VERSION ""

NS_ :

BS_:

BU_: ESM HIB HIP HIS SaGE CBC DASM DIAGNOST EBCM ECM EPS ESC ESL ETM HALF HCP IC OCM ORC PTS RF_HUB SCCM SGW

BO_ 1033 NM_SBWM: 8 ESM
 SG_ Awake_Diag_Actv m15 : 33|1@1+ (1,0) [0|0] ""  CBC,EBCM,EPS,ESC,ESL,HCP,IC,RF_HUB,SCCM,SGW
 SG_ Awake_EEPROM m15 : 35|1@1+ (1,0) [0|0] ""  CBC,EBCM,EPS,ESC,ESL,HCP,IC,RF_HUB,SCCM,SGW
 SG_ Awake_Ignition_On m15 : 34|1@1+ (1,0) [0|0] ""  CBC,EBCM,EPS,ESC,ESL,HCP,IC,RF_HUB,SCCM,SGW
 SG_ Awake_NwSt m15 : 32|1@1+ (1,0) [0|0] ""  CBC,EBCM,EPS,ESC,ESL,HCP,IC,RF_HUB,SCCM,SGW
 SG_ Awake_URS m15 : 36|1@1+ (1,0) [0|0] ""  CBC,EBCM,EPS,ESC,ESL,HCP,IC,RF_HUB,SCCM,SGW
 SG_ NM_Mode : 0|8@1+ (1,0) [0|0] ""  CBC,EBCM,EPS,ESC,ESL,HCP,IC,RF_HUB,SCCM,SGW
 SG_ NM_Sleep_Ack : 22|1@1+ (1,0) [0|0] ""  CBC,EBCM,EPS,ESC,ESL,HCP,IC,RF_HUB,SCCM,SGW
 SG_ NM_Sleep_Ind : 23|1@1+ (1,0) [0|0] ""  CBC,EBCM,EPS,ESC,ESL,HCP,IC,RF_HUB,SCCM,SGW
 SG_ NM_Successor : 8|8@1+ (1,0) [0|63] ""  CBC,EBCM,EPS,ESC,ESL,HCP,IC,RF_HUB,SCCM,SGW
 SG_ NM_Ud_Launch : 16|6@1+ (1,0) [0|0] ""  CBC,EBCM,EPS,ESC,ESL,HCP,IC,RF_HUB,SCCM,SGW
 SG_ NM_Ud_Srv M : 24|8@1+ (1,0) [0|0] ""  CBC,EBCM,EPS,ESC,ESL,HCP,IC,RF_HUB,SCCM,SGW
 SG_ Nw_Id : 56|8@1+ (1,0) [0|0] ""  CBC,EBCM,EPS,ESC,ESL,HCP,IC,RF_HUB,SCCM,SGW
 SG_ WakeupCnt m2 : 40|8@1+ (1,0) [0|254] ""  CBC,EBCM,EPS,ESC,ESL,HCP,IC,RF_HUB,SCCM,SGW
 SG_ WakeupRsn_SBWM m2 : 32|8@1+ (1,0) [0|0] ""  CBC,EBCM,EPS,ESC,ESL,HCP,IC,RF_HUB,SCCM,SGW

BO_ 1059 NM_SCCM: 8 SCCM
 SG_ Awake_Diag_Actv m15 : 33|1@1+ (1,0) [0|0] ""  CBC,EBCM,EPS,ESC,ESL,HCP,IC,RF_HUB,SCCM,SGW
 SG_ Awake_EEPROM m15 : 36|1@1+ (1,0) [0|0] ""  CBC,EBCM,EPS,ESC,ESL,HCP,IC,RF_HUB,SCCM,SGW
 SG_ Awake_FTP_Psd m15 : 38|1@1+ (1,0) [0|0] ""  CBC,EBCM,EPS,ESC,ESL,HCP,IC,RF_HUB,SCCM,SGW
 SG_ Awake_HrnSwt_Actv m15 : 39|1@1+ (1,0) [0|0] ""  CBC,EBCM,EPS,ESC,ESL,HCP,IC,RF_HUB,SCCM,SGW
 SG_ Awake_Ignition_On m15 : 35|1@1+ (1,0) [0|0] ""  CBC,EBCM,EPS,ESC,ESL,HCP,IC,RF_HUB,SCCM,SGW
 SG_ Awake_NwSt m15 : 32|1@1+ (1,0) [0|0] ""  CBC,EBCM,EPS,ESC,ESL,HCP,IC,RF_HUB,SCCM,SGW
 SG_ Awake_StwSw_Actv m15 : 34|1@1+ (1,0) [0|0] ""  CBC,EBCM,EPS,ESC,ESL,HCP,IC,RF_HUB,SCCM,SGW
 SG_ Awake_tilt_tel_Psd m15 : 37|1@1+ (1,0) [0|0] ""  CBC,EBCM,EPS,ESC,ESL,HCP,IC,RF_HUB,SCCM,SGW
 SG_ NM_Mode : 0|8@1+ (1,0) [0|0] ""  CBC,EBCM,EPS,ESC,ESL,HCP,IC,RF_HUB,SCCM,SGW
 SG_ NM_Sleep_Ack : 22|1@1+ (1,0) [0|0] ""  CBC,EBCM,EPS,ESC,ESL,HCP,IC,RF_HUB,SCCM,SGW
 SG_ NM_Sleep_Ind : 23|1@1+ (1,0) [0|0] ""  CBC,EBCM,EPS,ESC,ESL,HCP,IC,RF_HUB,SCCM,SGW
 SG_ NM_Successor : 8|8@1+ (1,0) [0|63] ""  CBC,EBCM,EPS,ESC,ESL,HCP,IC,RF_HUB,SCCM,SGW
 SG_ NM_Ud_Launch : 16|6@1+ (1,0) [0|0] ""  CBC,EBCM,EPS,ESC,ESL,HCP,IC,RF_HUB,SCCM,SGW
 SG_ NM_Ud_Srv M : 24|8@1+ (1,0) [0|0] ""  CBC,EBCM,EPS,ESC,ESL,HCP,IC,RF_HUB,SCCM,SGW
 SG_ Nw_Id : 56|8@1+ (1,0) [0|0] ""  CBC,EBCM,EPS,ESC,ESL,HCP,IC,RF_HUB,SCCM,SGW
 SG_ WakeupCnt m2 : 40|8@1+ (1,0) [0|254] ""  CBC,EBCM,EPS,ESC,ESL,HCP,IC,RF_HUB,SCCM,SGW
 SG_ WakeupRsn_SCCM m2 : 32|8@1+ (1,0) [0|0] ""  CBC,EBCM,EPS,ESC,ESL,HCP,IC,RF_HUB,SCCM,SGW

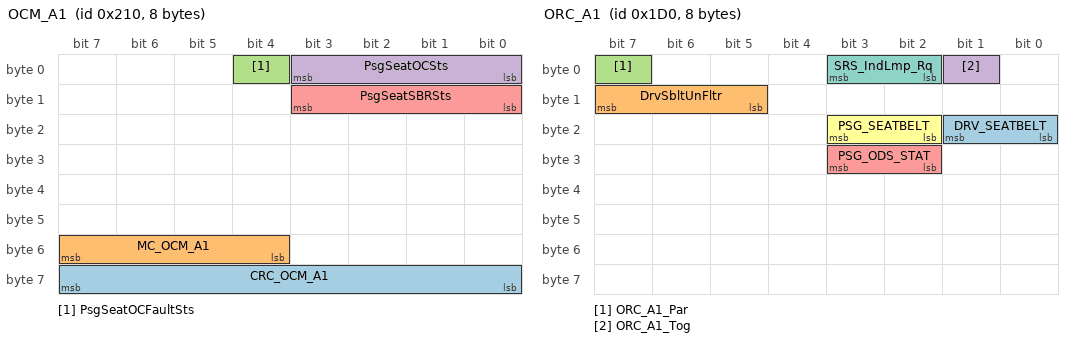
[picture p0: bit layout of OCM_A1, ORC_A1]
BO_ 528 OCM_A1: 8 OCM
 SG_ CRC_OCM_A1 : 56|8@1+ (1,0) [0|0] ""  ORC,SGW
 SG_ MC_OCM_A1 : 52|4@1+ (1,0) [0|15] ""  ORC,SGW
 SG_ PsgSeatOCFaultSts : 4|1@1+ (1,0) [0|0] ""  ORC,SGW
 SG_ PsgSeatOCSts : 0|4@1+ (1,0) [0|0] ""  ORC,SGW
 SG_ PsgSeatSBRSts : 8|4@1+ (1,0) [0|0] ""  ORC,SGW

BO_ 464 ORC_A1: 8 ORC
 SG_ DRV_SEATBELT : 16|2@1+ (1,0) [0|0] ""  HIB,DASM,ECM,ESC,ETM,HCP,IC,SGW
 SG_ DrvSbltUnFltr : 13|3@1+ (1,0) [0|0] ""  ECM,ESC,SGW
 SG_ ORC_A1_Par : 7|1@1+ (1,0) [0|0] ""  HIB,DASM,SGW
 SG_ ORC_A1_Tog : 1|1@1+ (1,0) [0|0] ""  HIB,DASM,SGW
 SG_ PSG_ODS_STAT : 26|2@1+ (1,0) [0|0] ""  IC,SGW
 SG_ PSG_SEATBELT : 18|2@1+ (1,0) [0|0] ""  ETM,IC,SGW
 SG_ SRS_IndLmp_Rq : 2|2@1+ (1,0) [0|0] ""  ETM,IC,SGW

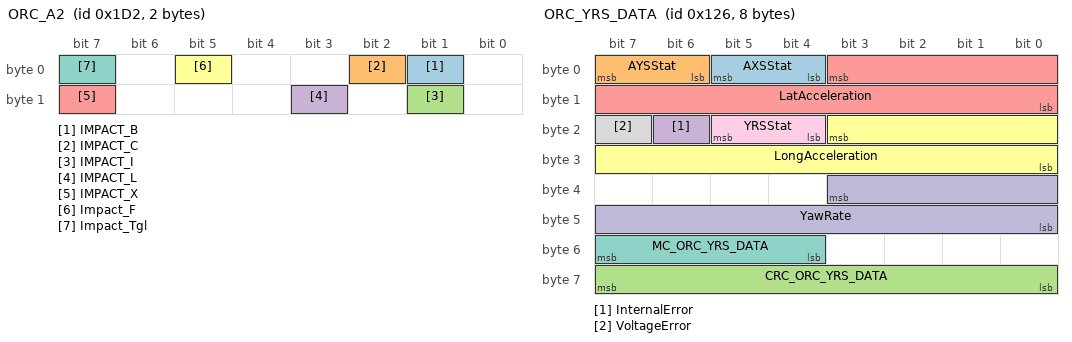
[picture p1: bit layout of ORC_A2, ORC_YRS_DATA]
BO_ 466 ORC_A2: 2 ORC
 SG_ IMPACT_B : 1|1@1+ (1,0) [0|0] ""  ETM,SGW
 SG_ IMPACT_C : 2|1@1+ (1,0) [0|0] ""  ETM,SGW
 SG_ IMPACT_I : 9|1@1+ (1,0) [0|0] ""  ETM,SGW
 SG_ IMPACT_L : 11|1@1+ (1,0) [0|0] ""  ETM,SGW
 SG_ IMPACT_X : 15|1@1+ (1,0) [0|0] ""  CBC,ECM,ETM,HCP,OCM,SGW
 SG_ Impact_F : 5|1@1+ (1,0) [0|0] ""  ETM,SGW
 SG_ Impact_Tgl : 7|1@1+ (1,0) [0|0] ""  CBC,ECM,ETM,HCP,OCM,SGW

BO_ 469 ORC_A4: 8 ORC
 SG_ ORC_Health : 23|1@1+ (1,0) [0|0] ""  HCP,SGW

BO_ 294 ORC_YRS_DATA: 8 ORC
 SG_ AXSStat : 4|2@1+ (1,0) [0|0] ""  EBCM,ESC,HCP,SGW
 SG_ AYSStat : 6|2@1+ (1,0) [0|0] ""  ESC,SGW
 SG_ CRC_ORC_YRS_DATA : 56|8@1+ (1,0) [0|0] ""  EBCM,ESC,SGW
 SG_ InternalError : 22|1@1+ (1,0) [0|0] ""  EBCM,ESC,SGW
 SG_ LatAcceleration : 3|12@0+ (0.02,-40.96) [-40.96|40.92] "m/s²"  EBCM,ESC,SGW
 SG_ LongAcceleration : 19|12@0+ (0.02,-40.96) [-40.96|40.92] "m/s²"  EBCM,ESC,HCP,SGW
 SG_ MC_ORC_YRS_DATA : 52|4@1+ (1,0) [0|15] ""  EBCM,ESC,SGW
 SG_ VoltageError : 23|1@1+ (1,0) [0|0] ""  EBCM,ESC,SGW
 SG_ YRSStat : 20|2@1+ (1,0) [0|0] ""  EBCM,ESC,SGW
 SG_ YawRate : 35|12@0+ (0.08,-163.84) [-163.84|163.68] "°/s"  EBCM,ESC,SGW

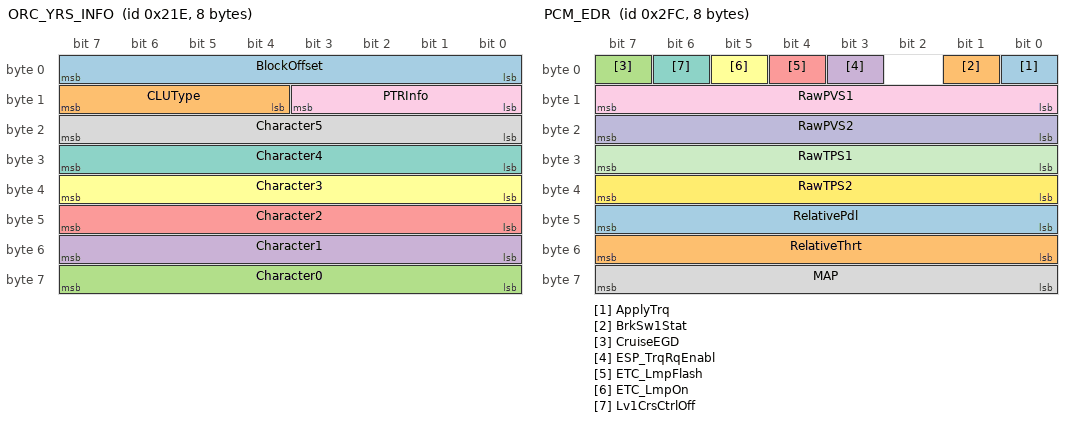
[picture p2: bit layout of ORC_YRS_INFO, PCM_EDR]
BO_ 542 ORC_YRS_INFO: 8 ORC
 SG_ BlockOffset : 0|8@1+ (1,0) [0|0] ""  ESC,SGW
 SG_ CLUType : 12|4@1+ (1,0) [0|0] ""  ESC,SGW
 SG_ Character0 : 56|8@1+ (1,0) [0|0] ""  ESC,SGW
 SG_ Character1 : 48|8@1+ (1,0) [0|0] ""  ESC,SGW
 SG_ Character2 : 40|8@1+ (1,0) [0|0] ""  ESC,SGW
 SG_ Character3 : 32|8@1+ (1,0) [0|0] ""  ESC,SGW
 SG_ Character4 : 24|8@1+ (1,0) [0|0] ""  ESC,SGW
 SG_ Character5 : 16|8@1+ (1,0) [0|0] ""  ESC,SGW
 SG_ PTRInfo : 8|4@1+ (1,0) [0|0] ""  ESC,SGW

BO_ 764 PCM_EDR: 8 ECM
 SG_ ApplyTrq : 0|1@1+ (1,0) [0|0] ""  SGW
 SG_ BrkSw1Stat : 1|1@1+ (1,0) [0|0] ""  ETM,SGW
 SG_ CruiseEGD : 7|1@1+ (1,0) [0|0] ""  SGW
 SG_ ESP_TrqRqEnabl : 3|1@1+ (1,0) [0|0] ""  ORC,SGW
 SG_ ETC_LmpFlash : 4|1@1+ (1,0) [0|0] ""  ORC,SGW
 SG_ ETC_LmpOn : 5|1@1+ (1,0) [0|0] ""  ORC,SGW
 SG_ Lv1CrsCtrlOff : 6|1@1+ (1,0) [0|0] ""  ORC,SGW
 SG_ MAP : 56|8@1+ (0.8,0) [0|203.2] "kPa"  ORC,SGW
 SG_ RawPVS1 : 8|8@1+ (0.019607843,0) [0|4.98] "Volts"  ORC,SGW
 SG_ RawPVS2 : 16|8@1+ (0.019607843,0) [0|4.98] "Volts"  ORC,SGW
 SG_ RawTPS1 : 24|8@1+ (0.019607843,0) [0|4.98] "Volts"  ORC,SGW
 SG_ RawTPS2 : 32|8@1+ (0.019607843,0) [0|4.98] "Volts"  ORC,SGW
 SG_ RelativePdl : 40|8@1+ (0.019607843,0) [0|4.98] "Volts"  SGW
 SG_ RelativeThrt : 48|8@1+ (0.019607843,0) [0|4.98] "Volts"  SGW

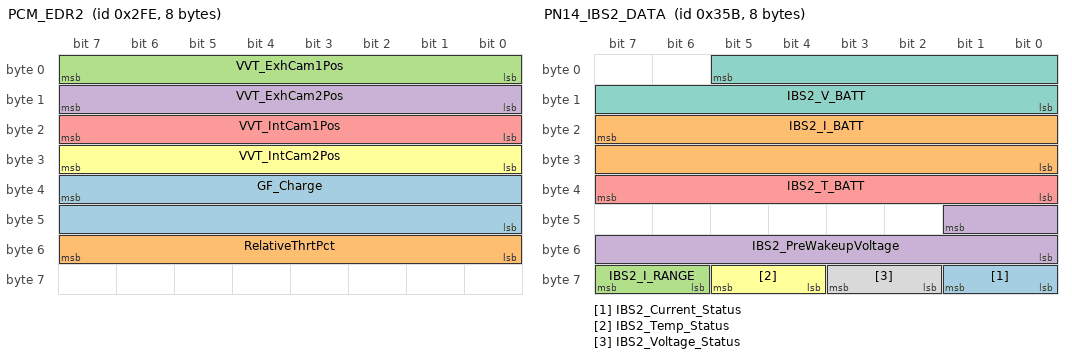
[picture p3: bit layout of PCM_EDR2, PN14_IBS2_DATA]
BO_ 766 PCM_EDR2: 8 ECM
 SG_ GF_Charge : 39|16@0+ (0.2,0) [0|13106.8] "mg/cycle/cyl"  ETM,ORC,SGW
 SG_ RelativeThrtPct : 48|8@1+ (0.4,0) [0|100] "%"  ORC,SGW
 SG_ VVT_ExhCam1Pos : 0|8@1+ (1,0) [1|255] "Degrees"  SGW
 SG_ VVT_ExhCam2Pos : 8|8@1+ (1,0) [1|255] "Degrees"  SGW
 SG_ VVT_IntCam1Pos : 16|8@1+ (1,0) [1|255] "Degrees"  SGW
 SG_ VVT_IntCam2Pos : 24|8@1+ (1,0) [1|255] "Degrees"  SGW

BO_ 859 PN14_IBS2_DATA: 8 CBC
 SG_ IBS2_Current_Status : 56|2@1+ (1,0) [0|0] ""  SGW
 SG_ IBS2_I_BATT : 23|16@0+ (1,-32768) [-32768|32766] "I_RANGE res."  SGW
 SG_ IBS2_I_RANGE : 62|2@1+ (1,0) [0|0] "Amp"  SGW
 SG_ IBS2_PreWakeupVoltage : 41|10@0+ (0.01,5) [5|15] "V"  SGW
 SG_ IBS2_T_BATT : 32|8@1+ (1,-40) [-40|105] "°C"  HCP,SGW
 SG_ IBS2_Temp_Status : 60|2@1+ (1,0) [0|0] ""  HCP,SGW
 SG_ IBS2_V_BATT : 5|14@0+ (0.0009765625,3) [3|18] "Volts"  HCP,SGW
 SG_ IBS2_Voltage_Status : 58|2@1+ (1,0) [0|0] ""  HCP,SGW

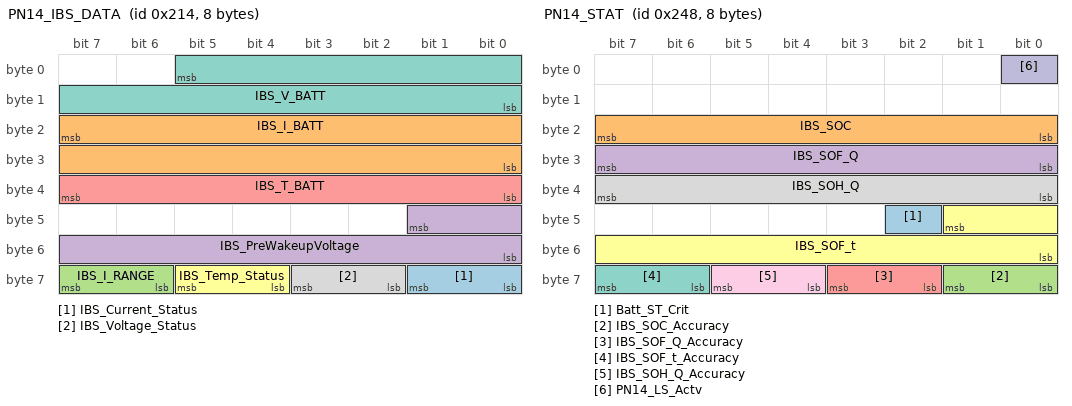
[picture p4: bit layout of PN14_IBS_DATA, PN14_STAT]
BO_ 532 PN14_IBS_DATA: 8 CBC
 SG_ IBS_Current_Status : 56|2@1+ (1,0) [0|0] ""  SGW
 SG_ IBS_I_BATT : 23|16@0+ (1,-32768) [-32768|32766] "I_RANGE res."  ETM,SGW
 SG_ IBS_I_RANGE : 62|2@1+ (1,0) [0|0] "Amp"  SGW
 SG_ IBS_PreWakeupVoltage : 41|10@0+ (0.01,5) [5|15] "V"  SGW
 SG_ IBS_T_BATT : 32|8@1+ (1,-40) [-40|105] "°C"  ETM,HCP,SGW
 SG_ IBS_Temp_Status : 60|2@1+ (1,0) [0|0] ""  HCP,SGW
 SG_ IBS_V_BATT : 5|14@0+ (0.0009765625,3) [3|18] "Volts"  ETM,HCP,ORC,SGW
 SG_ IBS_Voltage_Status : 58|2@1+ (1,0) [0|0] ""  HCP,SGW

BO_ 584 PN14_STAT: 8 CBC
 SG_ Batt_ST_Crit : 42|1@1+ (1,0) [0|0] ""  IC,SGW
 SG_ IBS_SOC : 16|8@1+ (1,0) [0|100] "%"  ETM,HCP,ORC,SGW
 SG_ IBS_SOC_Accuracy : 56|2@1+ (1,0) [0|0] ""  ETM,HCP,SGW
 SG_ IBS_SOF_Q : 24|8@1+ (0.5,0) [0|127] "Ah"  SGW
 SG_ IBS_SOF_Q_Accuracy : 58|2@1+ (1,0) [0|0] ""  SGW
 SG_ IBS_SOF_t : 41|10@0+ (1,0) [0|1022] "min"  SGW
 SG_ IBS_SOF_t_Accuracy : 62|2@1+ (1,0) [0|0] ""  SGW
 SG_ IBS_SOH_Q : 32|8@1+ (0.5,0) [0|127] "Ah"  SGW
 SG_ IBS_SOH_Q_Accuracy : 60|2@1+ (1,0) [0|0] ""  SGW
 SG_ PN14_LS_Actv : 0|1@1+ (1,0) [0|0] ""  IC,SGW

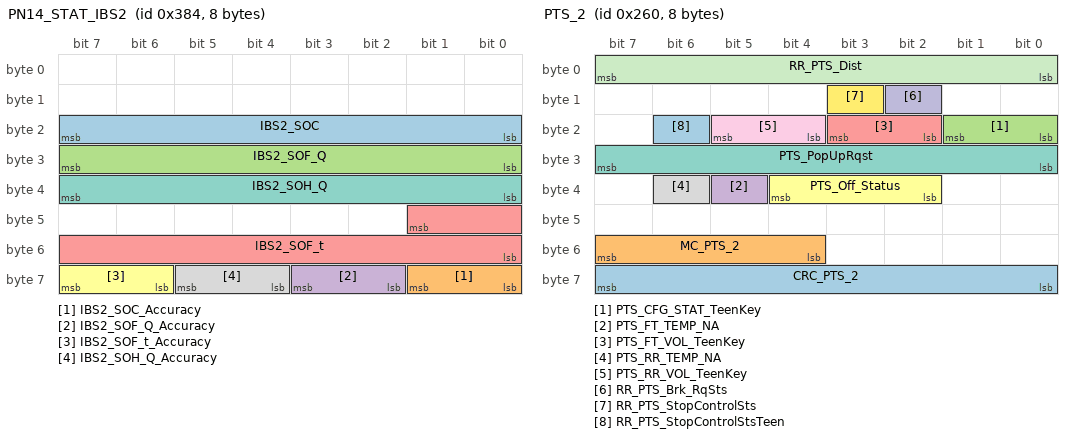
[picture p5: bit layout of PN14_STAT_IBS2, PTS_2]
BO_ 900 PN14_STAT_IBS2: 8 CBC
 SG_ IBS2_SOC : 16|8@1+ (1,0) [0|100] "%"  HCP,SGW
 SG_ IBS2_SOC_Accuracy : 56|2@1+ (1,0) [0|0] ""  HCP,SGW
 SG_ IBS2_SOF_Q : 24|8@1+ (0.5,0) [0|127] "Ah"  SGW
 SG_ IBS2_SOF_Q_Accuracy : 58|2@1+ (1,0) [0|0] ""  SGW
 SG_ IBS2_SOF_t : 41|10@0+ (1,0) [0|1022] "min"  SGW
 SG_ IBS2_SOF_t_Accuracy : 62|2@1+ (1,0) [0|0] ""  SGW
 SG_ IBS2_SOH_Q : 32|8@1+ (0.5,0) [0|127] "Ah"  SGW
 SG_ IBS2_SOH_Q_Accuracy : 60|2@1+ (1,0) [0|0] ""  SGW

BO_ 826 PTS_1: 8 PTS
 SG_ PTS_AlrFC : 40|4@1+ (1,0) [0|0] ""  CBC,IC,SGW
 SG_ PTS_AlrFL : 8|4@1+ (1,0) [0|0] ""  CBC,IC,SGW
 SG_ PTS_AlrFR : 16|4@1+ (1,0) [0|0] ""  CBC,IC,SGW
 SG_ PTS_AlrRC : 48|4@1+ (1,0) [0|0] ""  CBC,IC,SGW
 SG_ PTS_AlrRL : 24|4@1+ (1,0) [0|0] ""  CBC,IC,SGW
 SG_ PTS_AlrRR : 32|4@1+ (1,0) [0|0] ""  CBC,IC,SGW
 SG_ PTS_CFG_STAT : 1|2@1+ (1,0) [0|0] ""  CBC,SGW
 SG_ PTS_FT_NA : 3|1@1+ (1,0) [0|0] ""  IC,SGW
 SG_ PTS_FT_SRV : 58|1@1+ (1,0) [0|0] ""  ETM,IC,SGW
 SG_ PTS_GraphicFC : 46|2@1+ (1,0) [0|0] ""  IC,SGW
 SG_ PTS_GraphicFL : 14|2@1+ (1,0) [0|0] ""  IC,SGW
 SG_ PTS_GraphicFR : 22|2@1+ (1,0) [0|0] ""  IC,SGW
 SG_ PTS_GraphicRC : 54|2@1+ (1,0) [0|0] ""  IC,SGW
 SG_ PTS_GraphicRL : 30|2@1+ (1,0) [0|0] ""  IC,SGW
 SG_ PTS_GraphicRR : 38|2@1+ (1,0) [0|0] ""  IC,SGW
 SG_ PTS_RR_NA : 4|1@1+ (1,0) [0|0] ""  IC,SGW
 SG_ PTS_RR_SRV : 59|1@1+ (1,0) [0|0] ""  ETM,IC,SGW
 SG_ PTS_SRV_RQ : 5|1@1+ (1,0) [0|0] ""  IC,SGW
 SG_ PTS_STAT : 60|2@1+ (1,0) [0|0] ""  CBC,SGW

BO_ 608 PTS_2: 8 PTS
 SG_ CRC_PTS_2 : 56|8@1+ (1,0) [0|0] ""  ESC,SGW
 SG_ MC_PTS_2 : 52|4@1+ (1,0) [0|15] ""  ESC,SGW
 SG_ PTS_CFG_STAT_TeenKey : 16|2@1+ (1,0) [0|0] ""  CBC,SGW
 SG_ PTS_FT_TEMP_NA : 37|1@1+ (1,0) [0|0] ""  IC,SGW
 SG_ PTS_FT_VOL_TeenKey : 18|2@1+ (1,0) [0|0] ""  CBC,SGW
 SG_ PTS_Off_Status : 34|3@1+ (1,0) [0|0] ""  IC,SGW
 SG_ PTS_PopUpRqst : 24|8@1+ (1,0) [0|0] ""  IC,SGW
 SG_ PTS_RR_TEMP_NA : 38|1@1+ (1,0) [0|0] ""  IC,SGW
 SG_ PTS_RR_VOL_TeenKey : 20|2@1+ (1,0) [0|0] ""  CBC,SGW
 SG_ RR_PTS_Brk_RqSts : 10|1@1+ (1,0) [0|0] ""  ESC,SGW
 SG_ RR_PTS_Dist : 0|8@1+ (1,0) [0|254] "cm"  ESC,SGW
 SG_ RR_PTS_StopControlSts : 11|1@1+ (1,0) [0|0] ""  CBC,IC,SGW
 SG_ RR_PTS_StopControlStsTeen : 22|1@1+ (1,0) [0|0] ""  CBC,IC,SGW

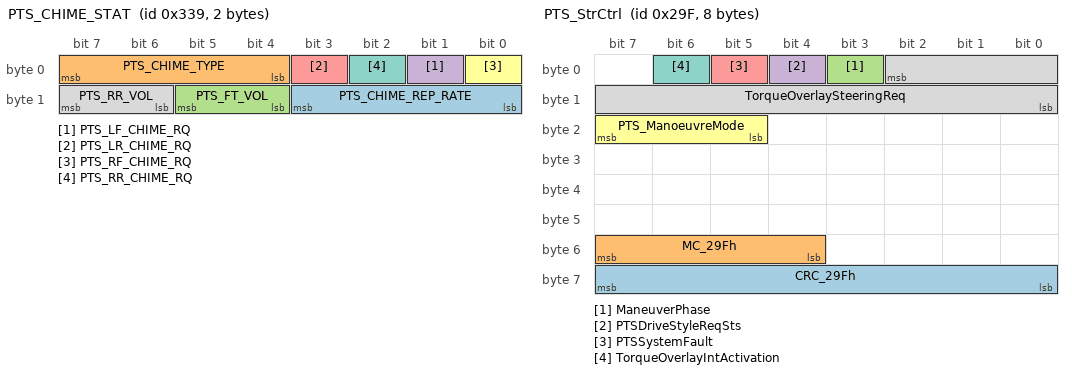
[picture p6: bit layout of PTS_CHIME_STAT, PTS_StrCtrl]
BO_ 825 PTS_CHIME_STAT: 2 PTS
 SG_ PTS_CHIME_REP_RATE : 8|4@1+ (1,0) [0|15] "Hz"  CBC,SGW
 SG_ PTS_CHIME_TYPE : 4|4@1+ (1,0) [0|0] ""  CBC,SGW
 SG_ PTS_FT_VOL : 12|2@1+ (1,0) [0|0] ""  CBC,SGW
 SG_ PTS_LF_CHIME_RQ : 1|1@1+ (1,0) [0|0] ""  CBC,SGW
 SG_ PTS_LR_CHIME_RQ : 3|1@1+ (1,0) [0|0] ""  CBC,SGW
 SG_ PTS_RF_CHIME_RQ : 0|1@1+ (1,0) [0|0] ""  CBC,SGW
 SG_ PTS_RR_CHIME_RQ : 2|1@1+ (1,0) [0|0] ""  CBC,SGW
 SG_ PTS_RR_VOL : 14|2@1+ (1,0) [0|0] ""  CBC,SGW

BO_ 671 PTS_StrCtrl: 8 PTS
 SG_ CRC_29Fh : 56|8@1+ (1,0) [0|0] ""  EPS,SGW
 SG_ MC_29Fh : 52|4@1+ (1,0) [0|15] ""  EPS,SGW
 SG_ ManeuverPhase : 3|1@1+ (1,0) [0|0] ""  EPS,SGW
 SG_ PTSDriveStyleReqSts : 4|1@1+ (1,0) [0|0] ""  EPS,SGW
 SG_ PTSSystemFault : 5|1@1+ (1,0) [0|0] ""  EPS,SGW
 SG_ PTS_ManoeuvreMode : 21|3@1+ (1,0) [0|0] ""  IC,SGW
 SG_ TorqueOverlayIntActivation : 6|1@1+ (1,0) [0|0] ""  EPS,SGW
 SG_ TorqueOverlaySteeringReq : 2|11@0+ (0.0078125,-8) [-8|7.9921875] "Nm"  EPS,SGW

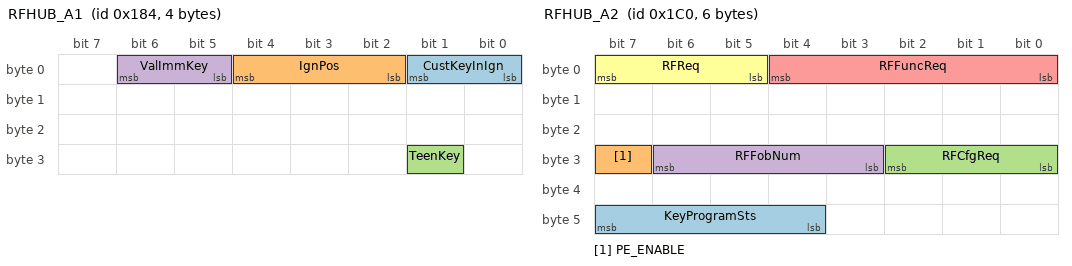
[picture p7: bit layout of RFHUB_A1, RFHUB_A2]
BO_ 388 RFHUB_A1: 4 RF_HUB
 SG_ CustKeyInIgn : 0|2@1+ (1,0) [0|0] ""  CBC,SGW
 SG_ IgnPos : 2|3@1+ (1,0) [0|0] ""  CBC,SGW
 SG_ TeenKey : 25|1@1+ (1,0) [0|0] ""  CBC,SGW
 SG_ ValImmKey : 5|2@1+ (1,0) [0|0] ""  SGW

BO_ 448 RFHUB_A2: 6 RF_HUB
 SG_ KeyProgramSts : 44|4@1+ (1,0) [0|0] ""  IC,SGW
 SG_ PE_ENABLE : 31|1@1+ (1,0) [0|0] ""  CBC,SGW
 SG_ RFCfgReq : 24|3@1+ (1,0) [0|0] ""  CBC,SGW
 SG_ RFFobNum : 27|4@1+ (1,0) [0|0] ""  CBC,SGW
 SG_ RFFuncReq : 0|5@1+ (1,0) [0|0] ""  CBC,ETM,IC,SGW
 SG_ RFReq : 5|3@1+ (1,0) [0|0] ""  CBC,IC,SGW

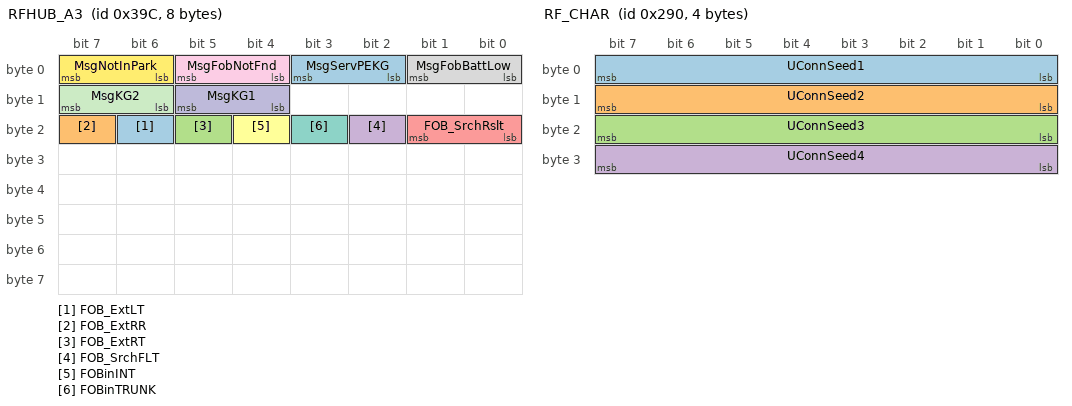
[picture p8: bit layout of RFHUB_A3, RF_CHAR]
BO_ 924 RFHUB_A3: 8 RF_HUB
 SG_ FOB_ExtLT : 22|1@1+ (1,0) [0|0] ""  CBC,SGW
 SG_ FOB_ExtRR : 23|1@1+ (1,0) [0|0] ""  CBC,SGW
 SG_ FOB_ExtRT : 21|1@1+ (1,0) [0|0] ""  CBC,SGW
 SG_ FOB_SrchFLT : 18|1@1+ (1,0) [0|0] ""  CBC,SGW
 SG_ FOB_SrchRslt : 16|2@1+ (1,0) [0|0] ""  CBC,SGW
 SG_ FOBinINT : 20|1@1+ (1,0) [0|0] ""  CBC,SGW
 SG_ FOBinTRUNK : 19|1@1+ (1,0) [0|0] ""  SGW
 SG_ MsgFobBattLow : 0|2@1+ (1,0) [0|0] ""  IC,SGW
 SG_ MsgFobNotFnd : 4|2@1+ (1,0) [0|0] ""  IC,SGW
 SG_ MsgKG1 : 12|2@1+ (1,0) [0|0] ""  IC,SGW
 SG_ MsgKG2 : 14|2@1+ (1,0) [0|0] ""  IC,SGW
 SG_ MsgNotInPark : 6|2@1+ (1,0) [0|0] ""  IC,SGW
 SG_ MsgServPEKG : 2|2@1+ (1,0) [0|0] ""  SGW

BO_ 656 RF_CHAR: 4 RF_HUB
 SG_ UConnSeed1 : 0|8@1+ (1,0) [0|0] ""  ETM,SGW
 SG_ UConnSeed2 : 8|8@1+ (1,0) [0|0] ""  ETM,SGW
 SG_ UConnSeed3 : 16|8@1+ (1,0) [0|0] ""  ETM,SGW
 SG_ UConnSeed4 : 24|8@1+ (1,0) [0|0] ""  ETM,SGW

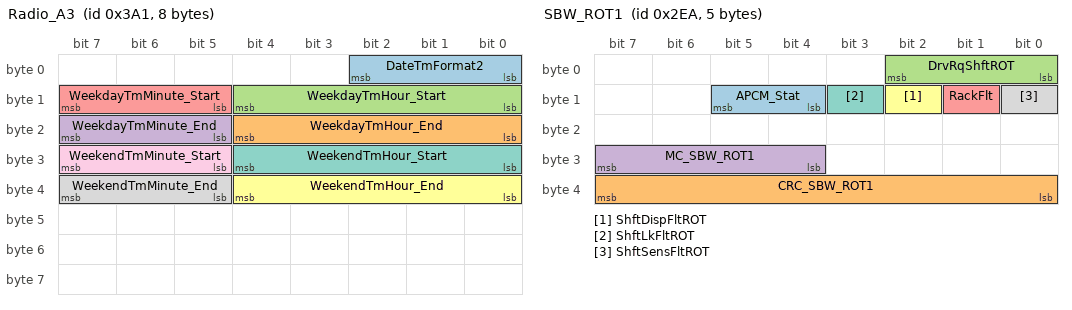
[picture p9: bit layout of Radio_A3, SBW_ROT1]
BO_ 929 Radio_A3: 8 CBC
 SG_ DateTmFormat2 : 0|3@1+ (1,0) [0|0] ""  IC,SGW
 SG_ WeekdayTmHour_End : 16|5@1+ (1,0) [0|24] "Hours"  IC,SGW
 SG_ WeekdayTmHour_Start : 8|5@1+ (1,0) [0|24] "Hours"  IC,SGW
 SG_ WeekdayTmMinute_End : 21|3@1+ (1,0) [0|0] "min"  IC,SGW
 SG_ WeekdayTmMinute_Start : 13|3@1+ (1,0) [0|0] "min"  IC,SGW
 SG_ WeekendTmHour_End : 32|5@1+ (1,0) [0|24] "Hours"  IC,SGW
 SG_ WeekendTmHour_Start : 24|5@1+ (1,0) [0|24] "Hours"  IC,SGW
 SG_ WeekendTmMinute_End : 37|3@1+ (1,0) [0|0] "min"  IC,SGW
 SG_ WeekendTmMinute_Start : 29|3@1+ (1,0) [0|0] "min"  IC,SGW

BO_ 746 SBW_ROT1: 5 ESM
 SG_ APCM_Stat : 12|2@1+ (1,0) [0|0] ""  HCP,SGW
 SG_ CRC_SBW_ROT1 : 32|8@1+ (1,0) [0|0] ""  EBCM,ESC,HCP,SGW
 SG_ DrvRqShftROT : 0|3@1+ (1,0) [0|0] ""  EBCM,ECM,ESC,HCP,RF_HUB,SGW
 SG_ MC_SBW_ROT1 : 28|4@1+ (1,0) [0|15] ""  EBCM,ESC,HCP,SGW
 SG_ RackFlt : 9|1@1+ (1,0) [0|0] ""  HCP,SGW
 SG_ ShftDispFltROT : 10|1@1+ (1,0) [0|0] ""  HCP,SGW
 SG_ ShftLkFltROT : 11|1@1+ (1,0) [0|0] ""  HCP,SGW
 SG_ ShftSensFltROT : 8|1@1+ (1,0) [0|0] ""  HCP,IC,SGW

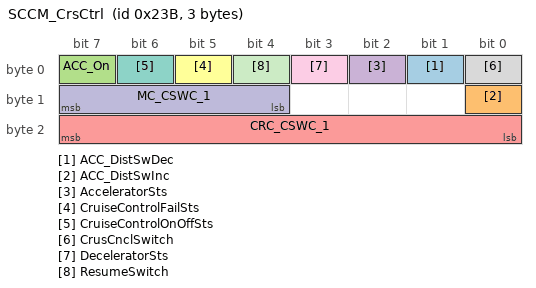
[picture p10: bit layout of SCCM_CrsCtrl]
BO_ 571 SCCM_CrsCtrl: 3 SCCM
 SG_ ACC_DistSwDec : 1|1@1+ (1,0) [0|0] ""  HIB,DASM,SGW
 SG_ ACC_DistSwInc : 8|1@1+ (1,0) [0|0] ""  HIB,DASM,SGW
 SG_ ACC_On : 7|1@1+ (1,0) [0|0] ""  HIB,DASM,ESC,SGW
 SG_ AcceleratorSts : 2|1@1+ (1,0) [0|0] ""  HIB,DASM,ECM,ESC,SGW
 SG_ CRC_CSWC_1 : 16|8@1+ (1,0) [0|0] ""  ECM,SGW
 SG_ CruiseControlFailSts : 5|1@1+ (1,0) [0|0] ""  HIB,DASM,ECM,ESC,SGW
 SG_ CruiseControlOnOffSts : 6|1@1+ (1,0) [0|0] ""  HIB,DASM,ECM,ESC,SGW
 SG_ CrusCnclSwitch : 0|1@1+ (1,0) [0|0] ""  HIB,DASM,ECM,ESC,SGW
 SG_ DeceleratorSts : 3|1@1+ (1,0) [0|0] ""  HIB,DASM,ECM,ESC,SGW
 SG_ MC_CSWC_1 : 12|4@1+ (1,0) [0|15] ""  ECM,SGW
 SG_ ResumeSwitch : 4|1@1+ (1,0) [0|0] ""  HIB,DASM,ECM,ESC,SGW

CM_ SG_ 1033 Awake_Diag_Actv "Stay awake for diagnostics active; True = [1]";
CM_ SG_ 1033 Awake_EEPROM "Stay awake for EEPROM write access; True = [1]";
CM_ SG_ 1033 Awake_Ignition_On "Stay awake for ignition on; True = [1]";
CM_ SG_ 1033 Awake_NwSt "Stay awake for network startup; True = [1]";
CM_ SG_ 1033 Awake_URS "Stay awake for 'Unlock Run Start' hardwired input; True = [1]";
CM_ SG_ 1033 NM_Mode "Network management mode";
CM_ SG_ 1033 NM_Sleep_Ack "Network management sleep acknowledge; True = [1]";
CM_ SG_ 1033 NM_Sleep_Ind "Network management sleep indication; True = [1]";
CM_ SG_ 1033 NM_Successor "Network management logical successor";
CM_ SG_ 1033 NM_Ud_Launch "Network management userdata launch type";
CM_ SG_ 1033 NM_Ud_Srv "Network management userdata service no.";
CM_ SG_ 1033 Nw_Id "Network identification no.";
CM_ SG_ 1033 WakeupCnt "Counter for module wakeup states during network sleep";
CM_ SG_ 1033 WakeupRsn_SBWM "Wakeup reason SBWM";
CM_ SG_ 1059 Awake_Diag_Actv "Stay awake for diagnostics active; True = [1]";
CM_ SG_ 1059 Awake_EEPROM "Stay awake for EEPROM write access; True = [1]";
CM_ SG_ 1059 Awake_FTP_Psd "Stay awake for flash to pass lever actuated; True = [1]";
CM_ SG_ 1059 Awake_HrnSwt_Actv "Stay awake for  horn switch active; True = [1]";
CM_ SG_ 1059 Awake_Ignition_On "Stay awake for ignition on; True = [1]";
CM_ SG_ 1059 Awake_NwSt "Stay awake for network startup; True = [1]";
CM_ SG_ 1059 Awake_StwSw_Actv "Stay awake for steering wheel switches active; True = [1]";
CM_ SG_ 1059 Awake_tilt_tel_Psd "Stay awake for tilt/telescope switch actuated; True = [1]";
CM_ SG_ 1059 NM_Mode "Network management mode";
CM_ SG_ 1059 NM_Sleep_Ack "Network management sleep acknowledge; True = [1]";
CM_ SG_ 1059 NM_Sleep_Ind "Network management sleep indication; True = [1]";
CM_ SG_ 1059 NM_Successor "Network management logical successor";
CM_ SG_ 1059 NM_Ud_Launch "Network management userdata launch type";
CM_ SG_ 1059 NM_Ud_Srv "Network management userdata service no.";
CM_ SG_ 1059 Nw_Id "Network identification no.";
CM_ SG_ 1059 WakeupCnt "Counter for module wakeup states during network sleep";
CM_ SG_ 1059 WakeupRsn_SCCM "Wakeup reason SCCM";
CM_ SG_ 528 CRC_OCM_A1 "CRC-checksum byte 1 to 7 according to SAE J1850";
CM_ SG_ 528 MC_OCM_A1 "Message counter";
CM_ SG_ 528 PsgSeatOCFaultSts "Passenger occupant classification fault; True = [1]";
CM_ SG_ 528 PsgSeatOCSts "Occupant classification passenger";
CM_ SG_ 528 PsgSeatSBRSts "Passenger seatbelt reminder status";
CM_ SG_ 464 DRV_SEATBELT "Drivers seat belt status";
CM_ SG_ 464 DrvSbltUnFltr "Drivers seat belt fault status - unfiltered";
CM_ SG_ 464 ORC_A1_Par "ORC_A1 even parity bit";
CM_ SG_ 464 ORC_A1_Tog "ORC_A1 toggle bit";
CM_ SG_ 464 PSG_ODS_STAT "Passenger Occupant Detection Sensor Status";
CM_ SG_ 464 PSG_SEATBELT "Passengers seat belt status";
CM_ SG_ 464 SRS_IndLmp_Rq "SRS indication lamp request";
CM_ SG_ 466 IMPACT_B "EARS Rear Event; actuate = [1]; do_not_actuate = [0]";
CM_ SG_ 466 IMPACT_C "EARS higher severity front event; actuate = [1]; do_not_actuate = [0]";
CM_ SG_ 466 IMPACT_I "EARS Rollover Event; actuate = [1]; do_not_actuate = [0]";
CM_ SG_ 466 IMPACT_L "EARS Side Event; actuate = [1]; do_not_actuate = [0]";
CM_ SG_ 466 IMPACT_X "Any impact event; actuate = [1]; do_not_actuate = [0]";
CM_ SG_ 466 Impact_F "EARS lower severity front event; actuate = [1]; do_not_actuate = [0]";
CM_ SG_ 466 Impact_Tgl "Toggle bit for all impact events; See Signal Description Document";
CM_ SG_ 469 ORC_Health "ORC alive and active; True = [1]";
CM_ SG_ 294 AXSStat "Longitudinal signal status";
CM_ SG_ 294 AYSStat "Latitudinal signal status";
CM_ SG_ 294 CRC_ORC_YRS_DATA "CRC-checksum byte 1 to 7 according to SAE J1850";
CM_ SG_ 294 InternalError "ORC ESC internal error; True = [1]";
CM_ SG_ 294 LatAcceleration "Raw lateral acceleration";
CM_ SG_ 294 LongAcceleration "Raw longitudinal acceleration";
CM_ SG_ 294 MC_ORC_YRS_DATA "Message counter";
CM_ SG_ 294 VoltageError "ORC ESC voltage error; True = [1]";
CM_ SG_ 294 YRSStat "Yaw rate signal status";
CM_ SG_ 294 YawRate "Raw yaw acceleration";
CM_ SG_ 542 BlockOffset "Part number block offset";
CM_ SG_ 542 CLUType "Part number CLU type";
CM_ SG_ 542 Character0 "Part number character 0";
CM_ SG_ 542 Character1 "Part number character 1";
CM_ SG_ 542 Character2 "Part number character 2";
CM_ SG_ 542 Character3 "Part number character 3";
CM_ SG_ 542 Character4 "Part number character 4";
CM_ SG_ 542 Character5 "Part number character 5";
CM_ SG_ 542 PTRInfo "Part number PTR information";
CM_ SG_ 764 ApplyTrq "EDR ONLY - Torque may be applied to the wheels";
CM_ SG_ 764 BrkSw1Stat "EDR ONLY - Brake switch1 status, off = [0]";
CM_ SG_ 764 CruiseEGD "EDR ONLY - Cruise system is engaged";
CM_ SG_ 764 ESP_TrqRqEnabl "EDR ONLY - ESP torque requests are allowed = [1]";
CM_ SG_ 764 ETC_LmpFlash "EDR ONLY - ETC lamp is flashing";
CM_ SG_ 764 ETC_LmpOn "EDR ONLY - ETC lamp is on";
CM_ SG_ 764 Lv1CrsCtrlOff "EDR ONLY - Level is requested cruise off";
CM_ SG_ 764 MAP "EDR ONLY - Intake manifold pressure";
CM_ SG_ 764 RawPVS1 "EDR ONLY - Raw pedal value sensor #1";
CM_ SG_ 764 RawPVS2 "EDR ONLY - Raw pedal value sensor #2";
CM_ SG_ 764 RawTPS1 "EDR ONLY - Raw throttle position sensor #1";
CM_ SG_ 764 RawTPS2 "EDR ONLY - Raw throttle position sensor #2";
CM_ SG_ 764 RelativePdl "EDR ONLY - Relative pedal value";
CM_ SG_ 764 RelativeThrt "EDR ONLY - Relative throttle value";
CM_ SG_ 766 GF_Charge "EDR ONLY - Port flow per cylinder per stroke";
CM_ SG_ 766 RelativeThrtPct "EDR ONLY - Relative throttle percent";
CM_ SG_ 766 VVT_ExhCam1Pos "EDR ONLY - Centerline position for exhaust cam on bank 1";
CM_ SG_ 766 VVT_ExhCam2Pos "EDR ONLY - Centerline position for exhaust cam on bank 2";
CM_ SG_ 766 VVT_IntCam1Pos "EDR ONLY - Centerline position for intake cam on bank 1";
CM_ SG_ 766 VVT_IntCam2Pos "EDR ONLY - Centerline position for intake cam on bank 2";
CM_ SG_ 859 IBS2_Current_Status "IBS2 Current Status";
CM_ SG_ 859 IBS2_I_BATT "Secondary Battery current (Using I_Range resolution)";
CM_ SG_ 859 IBS2_I_RANGE "Secondary Current range sensor setting";
CM_ SG_ 859 IBS2_PreWakeupVoltage "IBS2 voltage before LIN wakeup";
CM_ SG_ 859 IBS2_T_BATT "Secondary Battery temperature";
CM_ SG_ 859 IBS2_Temp_Status "IBS2 Temperature Status";
CM_ SG_ 859 IBS2_V_BATT "Secondary Batt. voltage measured at the terminals";
CM_ SG_ 859 IBS2_Voltage_Status "IBS2 Voltage Status";
CM_ SG_ 532 IBS_Current_Status "IBS Current Status";
CM_ SG_ 532 IBS_I_BATT "Battery current (Using I_Range resolution)";
CM_ SG_ 532 IBS_I_RANGE "Current range sensor setting";
CM_ SG_ 532 IBS_PreWakeupVoltage "IBS voltage before LIN wakeup";
CM_ SG_ 532 IBS_T_BATT "Battery temperature";
CM_ SG_ 532 IBS_Temp_Status "IBS Temperature Status";
CM_ SG_ 532 IBS_V_BATT "Batt. voltage measured at the terminals";
CM_ SG_ 532 IBS_Voltage_Status "IBS Voltage Status";
CM_ SG_ 584 Batt_ST_Crit "Battery reached critical state";
CM_ SG_ 584 IBS_SOC "State of charge";
CM_ SG_ 584 IBS_SOC_Accuracy "SOC accuracy status";
CM_ SG_ 584 IBS_SOF_Q "Residual battery charge in Ah";
CM_ SG_ 584 IBS_SOF_Q_Accuracy "SOF_Q accuracy status";
CM_ SG_ 584 IBS_SOF_t "Predicted time limit for start capability";
CM_ SG_ 584 IBS_SOF_t_Accuracy "SOF_t accuracy status";
CM_ SG_ 584 IBS_SOH_Q "State of health";
CM_ SG_ 584 IBS_SOH_Q_Accuracy "SOH_Q accuracy status";
CM_ SG_ 584 PN14_LS_Actv "14 V powernet Load Shed active";
CM_ SG_ 900 IBS2_SOC "State of charge - secondary batt";
CM_ SG_ 900 IBS2_SOC_Accuracy "SOC accuracy status - secondary batt";
CM_ SG_ 900 IBS2_SOF_Q "Residual battery charge in Ah - secondary batt";
CM_ SG_ 900 IBS2_SOF_Q_Accuracy "SOF_Q accuracy status - secondary batt";
CM_ SG_ 900 IBS2_SOF_t "Predicted time limit for start capability- secondary batt";
CM_ SG_ 900 IBS2_SOF_t_Accuracy "SOF_t accuracy status - secondary batt";
CM_ SG_ 900 IBS2_SOH_Q "Batt State of health - secondary batt";
CM_ SG_ 900 IBS2_SOH_Q_Accuracy "SOH_Q accuracy status - secondary batt";
CM_ SG_ 826 PTS_AlrFC "PTS alert front center";
CM_ SG_ 826 PTS_AlrFL "PTS alert front left";
CM_ SG_ 826 PTS_AlrFR "PTS alert front right";
CM_ SG_ 826 PTS_AlrRC "PTS alert rear center";
CM_ SG_ 826 PTS_AlrRL "PTS alert rear left";
CM_ SG_ 826 PTS_AlrRR "PTS alert rear right";
CM_ SG_ 826 PTS_CFG_STAT "Park assist configuration status";
CM_ SG_ 826 PTS_FT_NA "Front park assist not available - blinded sensor; True = [1]";
CM_ SG_ 826 PTS_FT_SRV "Front PTS sensor service request; True = [1]";
CM_ SG_ 826 PTS_GraphicFC "PTS graphic flash rate front center";
CM_ SG_ 826 PTS_GraphicFL "PTS graphic flash rate front left";
CM_ SG_ 826 PTS_GraphicFR "PTS graphic flash rate front right";
CM_ SG_ 826 PTS_GraphicRC "PTS graphic flash rate rear center";
CM_ SG_ 826 PTS_GraphicRL "PTS graphic flash rate rear left";
CM_ SG_ 826 PTS_GraphicRR "PTS graphic flash rate rear right";
CM_ SG_ 826 PTS_RR_NA "Rear park assist not available - blinded sensor; True = [1]";
CM_ SG_ 826 PTS_RR_SRV "Rear PTS sensor service request; True = [1]";
CM_ SG_ 826 PTS_SRV_RQ "PTS service warning request; True = [1]";
CM_ SG_ 826 PTS_STAT "Park Assist System - LED control status";
CM_ SG_ 608 CRC_PTS_2 "CRC-checksum byte 1 to 7 according to SAE J1850";
CM_ SG_ 608 MC_PTS_2 "Message counter";
CM_ SG_ 608 PTS_CFG_STAT_TeenKey "Park assist configuration status for teen key";
CM_ SG_ 608 PTS_FT_TEMP_NA "ParkSense front system temporarily not available; True = [1]";
CM_ SG_ 608 PTS_FT_VOL_TeenKey "PTS Front Volume Setting for teen key";
CM_ SG_ 608 PTS_Off_Status "ParkSense system on/off status indication";
CM_ SG_ 608 PTS_PopUpRqst "ParkSense HMI pop-up message request";
CM_ SG_ 608 PTS_RR_TEMP_NA "ParkSense rear system temporarily not available; True = [1]";
CM_ SG_ 608 PTS_RR_VOL_TeenKey "PTS Rear Volume Setting for teen key";
CM_ SG_ 608 RR_PTS_Brk_RqSts "PTS rear brake request flag; True = [1]";
CM_ SG_ 608 RR_PTS_Dist "Rear distance to nearest obstacle";
CM_ SG_ 608 RR_PTS_StopControlSts "PTS rear park stop control status; Enabled = [1]";
CM_ SG_ 608 RR_PTS_StopControlStsTeen "PTS rear park stop control status for teen key; Enabled = [1]";
CM_ SG_ 825 PTS_CHIME_REP_RATE "PTS chime repetition rate";
CM_ SG_ 825 PTS_CHIME_TYPE "PTS chime type";
CM_ SG_ 825 PTS_FT_VOL "PTS Front Volume Setting";
CM_ SG_ 825 PTS_LF_CHIME_RQ "PTS left front chime on request; True = [1]";
CM_ SG_ 825 PTS_LR_CHIME_RQ "PTS left rear chime on request; True = [1]";
CM_ SG_ 825 PTS_RF_CHIME_RQ "PTS right front chime on request; True = [1]";
CM_ SG_ 825 PTS_RR_CHIME_RQ "PTS right rear chime on request; True = [1]";
CM_ SG_ 825 PTS_RR_VOL "PTS Rear Volume Setting";
CM_ SG_ 671 CRC_29Fh "CRC-checksum byte 1 to 7 according to SAE J1850";
CM_ SG_ 671 MC_29Fh "Message counter";
CM_ SG_ 671 ManeuverPhase "Movement direction estimated by PTS; Forward = [1]";
CM_ SG_ 671 PTSDriveStyleReqSts "PTS drive style request status; Active = [1]";
CM_ SG_ 671 PTSSystemFault "PTS system fault; True = [1]";
CM_ SG_ 671 PTS_ManoeuvreMode "Parking maneuver mode status of the PTS";
CM_ SG_ 671 TorqueOverlayIntActivation "Torques overlay interface activiation request; Active = [1]";
CM_ SG_ 671 TorqueOverlaySteeringReq "Torque requested by the PTS torque overlay";
CM_ SG_ 388 CustKeyInIgn "Driver's request, key-in-ignition";
CM_ SG_ 388 IgnPos "Drivers request, ignition position";
CM_ SG_ 388 TeenKey "Teen key present; Present = [1]";
CM_ SG_ 388 ValImmKey "Drivers request, immobilizer results";
CM_ SG_ 448 KeyProgramSts "Key programming status";
CM_ SG_ 448 PE_ENABLE "Passive entry feature enabled; [1] = True";
CM_ SG_ 448 RFCfgReq "Change customer programmable items by RKE";
CM_ SG_ 448 RFFobNum "FOB number making the request";
CM_ SG_ 448 RFFuncReq "Basic request (RKE, PE, Remstart)";
CM_ SG_ 448 RFReq "Who's asking for the request";
CM_ SG_ 924 FOB_ExtLT "FOB is in zone exterior left";
CM_ SG_ 924 FOB_ExtRR "FOB is in zone exterior rear";
CM_ SG_ 924 FOB_ExtRT "FOB is in zone exterior right";
CM_ SG_ 924 FOB_SrchFLT "FOB search fault";
CM_ SG_ 924 FOB_SrchRslt "FOB search result";
CM_ SG_ 924 FOBinINT "FOB is in zone interior";
CM_ SG_ 924 FOBinTRUNK "FOB is in zone trunk";
CM_ SG_ 924 MsgFobBattLow "Indicates battery low on FOBIK last used for RKE purposes";
CM_ SG_ 924 MsgFobNotFnd "FOB Not Detected.";
CM_ SG_ 924 MsgKG1 "Place holder for future.";
CM_ SG_ 924 MsgKG2 "Place holder for future.";
CM_ SG_ 924 MsgNotInPark "Vehicle was not in Park.";
CM_ SG_ 924 MsgServPEKG "Service the Keyless System.";
CM_ SG_ 656 UConnSeed1 "Character 1";
CM_ SG_ 656 UConnSeed2 "Character 2";
CM_ SG_ 656 UConnSeed3 "Character 3";
CM_ SG_ 656 UConnSeed4 "Character 4";
CM_ SG_ 929 DateTmFormat2 "Date and Time Format";
CM_ SG_ 929 WeekdayTmHour_End "Time of day during the weekday: Hours";
CM_ SG_ 929 WeekdayTmHour_Start "Time of day during the weekday: Hours";
CM_ SG_ 929 WeekdayTmMinute_End "Time of day during the weekday: Minutes";
CM_ SG_ 929 WeekdayTmMinute_Start "Time of day during the weekday: Minutes";
CM_ SG_ 929 WeekendTmHour_End "Time of day during the weekend: Hours";
CM_ SG_ 929 WeekendTmHour_Start "Time of day during the weekend: Hours";
CM_ SG_ 929 WeekendTmMinute_End "Time of day during the weekend: Minutes";
CM_ SG_ 929 WeekendTmMinute_Start "Time of day during the weekend: Minutes";
CM_ SG_ 746 APCM_Stat "Auto position correction mode status";
CM_ SG_ 746 CRC_SBW_ROT1 "CRC-checksum byte 1 to 4 according to SAE J1850";
CM_ SG_ 746 DrvRqShftROT "Driver requested gear shift position";
CM_ SG_ 746 MC_SBW_ROT1 "Message counter";
CM_ SG_ 746 RackFlt "Rack / detent sensor fault, 1=fault";
CM_ SG_ 746 ShftDispFltROT "Gear shifter display/trigger fault status - rotary shifter, 1=fault";
CM_ SG_ 746 ShftLkFltROT "Shift lock fault - rotary shifter, 1=fault";
CM_ SG_ 746 ShftSensFltROT "Shift sensor single fault - rotary shifter, 1=fault";
CM_ SG_ 571 ACC_DistSwDec "Cruise Switch: Distance Decrease pressed";
CM_ SG_ 571 ACC_DistSwInc "Cruise Switch: Distance Increase pressed";
CM_ SG_ 571 ACC_On "Cruise Switch: ACC or ESC mode pressed";
CM_ SG_ 571 AcceleratorSts "Cruise Switch: Set/Accel Pressed";
CM_ SG_ 571 CRC_CSWC_1 "CRC-checksum byte 1 to 2 according to SAE J1850";
CM_ SG_ 571 CruiseControlFailSts "Cruise Switch: Implausible State=1";
CM_ SG_ 571 CruiseControlOnOffSts "Cruise Switch: On/Off  Pressed";
CM_ SG_ 571 CrusCnclSwitch "Cruise Switch: Cancel Pressed";
CM_ SG_ 571 DeceleratorSts "Cruise Switch: Coast or Set/Decel Pressed";
CM_ SG_ 571 MC_CSWC_1 "Message counter";
CM_ SG_ 571 ResumeSwitch "Cruise Switch: Resume Pressed";
BA_DEF_ BO_  "App-Botschaft" ENUM  "nein","ja";
BA_DEF_ BO_  "CanMsgMinLen" INT 0 8;
BA_DEF_ BO_  "DiagRequest" ENUM  "nein","ja";
BA_DEF_ BO_  "DiagResponse" ENUM  "nein","ja";
BA_DEF_ BO_  "DiagState" ENUM  "nein","ja";
BA_DEF_ BO_  "GenMsgCycleTime" INT 0 65535;
BA_DEF_ BO_  "GenMsgCycleTimeActive" INT 0 65535;
BA_DEF_ BO_  "GenMsgDelayTime" INT 0 65535;
BA_DEF_ BO_  "GenMsgNrOfRepetitions" INT 0 65535;
BA_DEF_ BO_  "GenMsgSendType" ENUM  "cyclicX","spontanX","cyclicIfActiveX","spontanWithDelay","cyclicAndSpontanX","cyclicAndSpontanWithDelay","spontanWithRepitition","cyclicIfActiveAndSpontanWD","cyclicIfActiveFast","cyclicWithRepeatOnDemand","none";
BA_DEF_ BO_  "GenMsgStartDelayTime" INT 0 65535;
BA_DEF_ BO_  "GenMsgStartValue" STRING ;
BA_DEF_ BO_  "NWM-Botschaft" ENUM  "nein","ja";
BA_DEF_ BO_  "TpTxIndex" INT 0 99;
BA_DEF_ SG_  "FlexKomComment" STRING ;
BA_DEF_ SG_  "FlexKomIsMotorola" ENUM  "nein","ja";
BA_DEF_ SG_  "FlexKomSID" INT 0 2147483647;
BA_DEF_ SG_  "FlexKomSigLaenge" INT 0 64;
BA_DEF_ SG_  "FlexKomSigName" STRING ;
BA_DEF_ SG_  "FlexKomSigStartPos" INT 0 63;
BA_DEF_ SG_  "FlexKomSigStartValue" STRING ;
BA_DEF_ SG_  "GenSigCycleTime" INT 0 65535;
BA_DEF_ SG_  "GenSigCycleTimeActive" INT 0 65535;
BA_DEF_ SG_  "GenSigSendType" ENUM  "cyclicX","spontanX","cyclicIfActiveX","spontanWithDelay","cyclicAndSpontanX","cyclicAndSpontanWithDelay","spontanWithRepitition","cyclicIfActiveAndSpontanWD","cyclicIfActiveFast","cyclicWithRepeatOnDemand","none";
BA_DEF_ SG_  "GenSigSNA" STRING ;
BA_DEF_ SG_  "GenSigStartValue" HEX 0 2147483648;
BA_DEF_ SG_  "GenSigTimeout_CBC" INT 0 65535;
BA_DEF_ SG_  "GenSigTimeout_EPS" INT 0 65535;
BA_DEF_ SG_  "GenSigTimeout_ESC" INT 0 65535;
BA_DEF_ SG_  "GenSigTimeout_ESL" INT 0 65535;
BA_DEF_ SG_  "GenSigTimeout_RHSC2" INT 0 65535;
BA_DEF_ SG_  "GenSigTimeout_ETM" INT 0 65535;
BA_DEF_ SG_  "GenSigTimeout_HaLF" INT 0 65535;
BA_DEF_ SG_  "GenSigTimeout_IC" INT 0 65535;
BA_DEF_ SG_  "GenSigTimeout_OCM" INT 0 65535;
BA_DEF_ SG_  "GenSigTimeout_ORC" INT 0 65535;
BA_DEF_ SG_  "GenSigTimeout_PTS" INT 0 65535;
BA_DEF_ SG_  "GenSigTimeout_RF_HUB" INT 0 65535;
BA_DEF_ SG_  "GenSigTimeout_SCCM" INT 0 65535;
BA_DEF_ SG_  "RID" STRING ;
BA_DEF_DEF_  "App-Botschaft" "nein";
BA_DEF_DEF_  "CanMsgMinLen" 0;
BA_DEF_DEF_  "DiagRequest" "nein";
BA_DEF_DEF_  "DiagResponse" "nein";
BA_DEF_DEF_  "DiagState" "nein";
BA_DEF_DEF_  "GenMsgCycleTime" 0;
BA_DEF_DEF_  "GenMsgCycleTimeActive" 0;
BA_DEF_DEF_  "GenMsgDelayTime" 0;
BA_DEF_DEF_  "GenMsgNrOfRepetitions" 0;
BA_DEF_DEF_  "GenMsgSendType" "cyclicX";
BA_DEF_DEF_  "GenMsgStartDelayTime" 0;
BA_DEF_DEF_  "GenMsgStartValue" "";
BA_DEF_DEF_  "NWM-Botschaft" "nein";
BA_DEF_DEF_  "TpTxIndex" 0;
BA_DEF_DEF_  "FlexKomComment" "";
BA_DEF_DEF_  "FlexKomIsMotorola" "nein";
BA_DEF_DEF_  "FlexKomSID" 0;
BA_DEF_DEF_  "FlexKomSigLaenge" 0;
BA_DEF_DEF_  "FlexKomSigName" "";
BA_DEF_DEF_  "FlexKomSigStartPos" 0;
BA_DEF_DEF_  "FlexKomSigStartValue" "";
BA_DEF_DEF_  "GenSigCycleTime" 0;
BA_DEF_DEF_  "GenSigCycleTimeActive" 0;
BA_DEF_DEF_  "GenSigSendType" "cyclicX";
BA_DEF_DEF_  "GenSigSNA" "";
BA_DEF_DEF_  "GenSigStartValue" 0;
BA_DEF_DEF_  "GenSigTimeout_CBC" 0;
BA_DEF_DEF_  "GenSigTimeout_EPS" 0;
BA_DEF_DEF_  "GenSigTimeout_ESC" 0;
BA_DEF_DEF_  "GenSigTimeout_ESL" 0;
BA_DEF_DEF_  "GenSigTimeout_RHSC2" 0;
BA_DEF_DEF_  "GenSigTimeout_ETM" 0;
BA_DEF_DEF_  "GenSigTimeout_HaLF" 0;
BA_DEF_DEF_  "GenSigTimeout_IC" 0;
BA_DEF_DEF_  "GenSigTimeout_OCM" 0;
BA_DEF_DEF_  "GenSigTimeout_ORC" 0;
BA_DEF_DEF_  "GenSigTimeout_PTS" 0;
BA_DEF_DEF_  "GenSigTimeout_RF_HUB" 0;
BA_DEF_DEF_  "GenSigTimeout_SCCM" 0;
BA_DEF_DEF_  "RID" "";
BA_ "GenMsgDelayTime" BO_ 1033 20;
BA_ "GenMsgNrOfRepetitions" BO_ 1033 2;
BA_ "GenMsgSendType" BO_ 1033 1;
BA_ "GenMsgStartValue" BO_ 1033 "FFFFFFFF000000FFh";
BA_ "NWM-Botschaft" BO_ 1033 1;
BA_ "GenMsgDelayTime" BO_ 1059 20;
BA_ "GenMsgNrOfRepetitions" BO_ 1059 2;
BA_ "GenMsgSendType" BO_ 1059 1;
BA_ "GenMsgStartValue" BO_ 1059 "FFFFFFFF000000FFh";
BA_ "NWM-Botschaft" BO_ 1059 1;
BA_ "GenMsgCycleTime" BO_ 528 1000;
BA_ "GenMsgDelayTime" BO_ 528 20;
BA_ "GenMsgNrOfRepetitions" BO_ 528 2;
BA_ "GenMsgSendType" BO_ 528 5;
BA_ "GenMsgStartValue" BO_ 528 "0F0F0000000000FFh";
BA_ "GenMsgCycleTime" BO_ 464 1000;
BA_ "GenMsgDelayTime" BO_ 464 20;
BA_ "GenMsgNrOfRepetitions" BO_ 464 2;
BA_ "GenMsgSendType" BO_ 464 5;
BA_ "GenMsgStartValue" BO_ 464 "44E70F0F00070000h";
BA_ "GenMsgCycleTimeActive" BO_ 466 20;
BA_ "GenMsgDelayTime" BO_ 466 20;
BA_ "GenMsgNrOfRepetitions" BO_ 466 2;
BA_ "GenMsgSendType" BO_ 466 2;
BA_ "GenMsgStartValue" BO_ 466 "0000h";
BA_ "GenMsgCycleTime" BO_ 469 250;
BA_ "GenMsgDelayTime" BO_ 469 20;
BA_ "GenMsgNrOfRepetitions" BO_ 469 2;
BA_ "GenMsgSendType" BO_ 469 5;
BA_ "GenMsgStartValue" BO_ 469 "0000000000000000h";
BA_ "GenMsgCycleTime" BO_ 294 10;
BA_ "GenMsgDelayTime" BO_ 294 20;
BA_ "GenMsgNrOfRepetitions" BO_ 294 2;
BA_ "GenMsgStartValue" BO_ 294 "000000000FFF00FFh";
BA_ "GenMsgCycleTime" BO_ 542 100;
BA_ "GenMsgDelayTime" BO_ 542 100;
BA_ "GenMsgNrOfRepetitions" BO_ 542 3;
BA_ "GenMsgSendType" BO_ 542 9;
BA_ "GenMsgStartValue" BO_ 542 "0000000000000000h";
BA_ "GenMsgCycleTime" BO_ 764 100;
BA_ "GenMsgDelayTime" BO_ 764 20;
BA_ "GenMsgNrOfRepetitions" BO_ 764 2;
BA_ "GenMsgStartValue" BO_ 764 "00FFFFFFFFFFFFFFh";
BA_ "GenMsgCycleTime" BO_ 766 100;
BA_ "GenMsgDelayTime" BO_ 766 20;
BA_ "GenMsgNrOfRepetitions" BO_ 766 2;
BA_ "GenMsgStartValue" BO_ 766 "FFFFFFFF0000FF00h";
BA_ "GenMsgCycleTime" BO_ 859 100;
BA_ "GenMsgDelayTime" BO_ 859 20;
BA_ "GenMsgNrOfRepetitions" BO_ 859 2;
BA_ "GenMsgStartDelayTime" BO_ 859 10;
BA_ "GenMsgStartValue" BO_ 859 "3FFFFFFFFF03FFC0h";
BA_ "GenMsgCycleTime" BO_ 532 100;
BA_ "GenMsgDelayTime" BO_ 532 20;
BA_ "GenMsgNrOfRepetitions" BO_ 532 2;
BA_ "GenMsgStartDelayTime" BO_ 532 10;
BA_ "GenMsgStartValue" BO_ 532 "3FFFFFFFFF03FFC0h";
BA_ "GenMsgCycleTime" BO_ 584 500;
BA_ "GenMsgDelayTime" BO_ 584 20;
BA_ "GenMsgNrOfRepetitions" BO_ 584 2;
BA_ "GenMsgSendType" BO_ 584 5;
BA_ "GenMsgStartDelayTime" BO_ 584 70;
BA_ "GenMsgStartValue" BO_ 584 "0000FFFFFF03FFFFh";
BA_ "GenMsgCycleTime" BO_ 900 500;
BA_ "GenMsgDelayTime" BO_ 900 20;
BA_ "GenMsgNrOfRepetitions" BO_ 900 2;
BA_ "GenMsgSendType" BO_ 900 5;
BA_ "GenMsgStartDelayTime" BO_ 900 70;
BA_ "GenMsgStartValue" BO_ 900 "0000FFFFFF03FFFFh";
BA_ "GenMsgCycleTime" BO_ 826 500;
BA_ "GenMsgDelayTime" BO_ 826 20;
BA_ "GenMsgNrOfRepetitions" BO_ 826 2;
BA_ "GenMsgSendType" BO_ 826 5;
BA_ "GenMsgStartValue" BO_ 826 "00F0F0F0F0F0F000h";
BA_ "GenMsgCycleTime" BO_ 608 500;
BA_ "GenMsgDelayTime" BO_ 608 20;
BA_ "GenMsgNrOfRepetitions" BO_ 608 2;
BA_ "GenMsgSendType" BO_ 608 5;
BA_ "GenMsgStartValue" BO_ 608 "FF001400000000FFh";
BA_ "GenMsgCycleTime" BO_ 825 500;
BA_ "GenMsgDelayTime" BO_ 825 20;
BA_ "GenMsgNrOfRepetitions" BO_ 825 2;
BA_ "GenMsgSendType" BO_ 825 5;
BA_ "GenMsgStartValue" BO_ 825 "0050h";
BA_ "GenMsgCycleTime" BO_ 671 20;
BA_ "GenMsgDelayTime" BO_ 671 20;
BA_ "GenMsgNrOfRepetitions" BO_ 671 2;
BA_ "GenMsgStartValue" BO_ 671 "04000000000000FFh";
BA_ "GenMsgCycleTime" BO_ 388 100;
BA_ "GenMsgDelayTime" BO_ 388 20;
BA_ "GenMsgNrOfRepetitions" BO_ 388 2;
BA_ "GenMsgSendType" BO_ 388 5;
BA_ "GenMsgStartValue" BO_ 388 "1C000000h";
BA_ "GenMsgCycleTime" BO_ 448 200;
BA_ "GenMsgDelayTime" BO_ 448 20;
BA_ "GenMsgNrOfRepetitions" BO_ 448 2;
BA_ "GenMsgSendType" BO_ 448 5;
BA_ "GenMsgStartValue" BO_ 448 "000000000000h";
BA_ "GenMsgCycleTime" BO_ 924 1000;
BA_ "GenMsgDelayTime" BO_ 924 20;
BA_ "GenMsgNrOfRepetitions" BO_ 924 2;
BA_ "GenMsgSendType" BO_ 924 5;
BA_ "GenMsgStartValue" BO_ 924 "0000000000000000h";
BA_ "GenMsgDelayTime" BO_ 656 20;
BA_ "GenMsgNrOfRepetitions" BO_ 656 2;
BA_ "GenMsgSendType" BO_ 656 1;
BA_ "GenMsgStartValue" BO_ 656 "00000000h";
BA_ "GenMsgCycleTime" BO_ 929 1000;
BA_ "GenMsgDelayTime" BO_ 929 20;
BA_ "GenMsgNrOfRepetitions" BO_ 929 2;
BA_ "GenMsgSendType" BO_ 929 5;
BA_ "GenMsgStartValue" BO_ 929 "07FFFFFFFF000000h";
BA_ "GenMsgCycleTime" BO_ 746 20;
BA_ "GenMsgDelayTime" BO_ 746 20;
BA_ "GenMsgNrOfRepetitions" BO_ 746 2;
BA_ "GenMsgStartValue" BO_ 746 "00000000FFh";
BA_ "GenMsgDelayTime" BO_ 571 20;
BA_ "GenMsgNrOfRepetitions" BO_ 571 2;
BA_ "GenMsgSendType" BO_ 571 1;
BA_ "GenMsgStartValue" BO_ 571 "0000FFh";
BA_ "FlexKomComment" SG_ 1033 Awake_Diag_Actv "Mode 15 of NM_Ud_Srv";
BA_ "FlexKomIsMotorola" SG_ 1033 Awake_Diag_Actv 1;
BA_ "FlexKomSID" SG_ 1033 Awake_Diag_Actv 1370;
BA_ "FlexKomSigLaenge" SG_ 1033 Awake_Diag_Actv 24;
BA_ "FlexKomSigName" SG_ 1033 Awake_Diag_Actv "Awake_SBWM";
BA_ "FlexKomSigStartPos" SG_ 1033 Awake_Diag_Actv 39;
BA_ "FlexKomSigStartValue" SG_ 1033 Awake_Diag_Actv "000000h";
BA_ "GenSigSendType" SG_ 1033 Awake_Diag_Actv 1;
BA_ "GenSigSNA" SG_ 1033 Awake_Diag_Actv "0h";
BA_ "RID" SG_ 1033 Awake_Diag_Actv "9612";
BA_ "FlexKomComment" SG_ 1033 Awake_EEPROM "Mode 15 of NM_Ud_Srv";
BA_ "FlexKomIsMotorola" SG_ 1033 Awake_EEPROM 1;
BA_ "FlexKomSID" SG_ 1033 Awake_EEPROM 1370;
BA_ "FlexKomSigLaenge" SG_ 1033 Awake_EEPROM 24;
BA_ "FlexKomSigName" SG_ 1033 Awake_EEPROM "Awake_SBWM";
BA_ "FlexKomSigStartPos" SG_ 1033 Awake_EEPROM 39;
BA_ "FlexKomSigStartValue" SG_ 1033 Awake_EEPROM "000000h";
BA_ "GenSigSendType" SG_ 1033 Awake_EEPROM 1;
BA_ "GenSigSNA" SG_ 1033 Awake_EEPROM "0h";
BA_ "RID" SG_ 1033 Awake_EEPROM "9613";
BA_ "FlexKomComment" SG_ 1033 Awake_Ignition_On "Mode 15 of NM_Ud_Srv";
BA_ "FlexKomIsMotorola" SG_ 1033 Awake_Ignition_On 1;
BA_ "FlexKomSID" SG_ 1033 Awake_Ignition_On 1370;
BA_ "FlexKomSigLaenge" SG_ 1033 Awake_Ignition_On 24;
BA_ "FlexKomSigName" SG_ 1033 Awake_Ignition_On "Awake_SBWM";
BA_ "FlexKomSigStartPos" SG_ 1033 Awake_Ignition_On 39;
BA_ "FlexKomSigStartValue" SG_ 1033 Awake_Ignition_On "000000h";
BA_ "GenSigSendType" SG_ 1033 Awake_Ignition_On 1;
BA_ "GenSigSNA" SG_ 1033 Awake_Ignition_On "0h";
BA_ "RID" SG_ 1033 Awake_Ignition_On "9614";
BA_ "FlexKomComment" SG_ 1033 Awake_NwSt "Mode 15 of NM_Ud_Srv";
BA_ "FlexKomIsMotorola" SG_ 1033 Awake_NwSt 1;
BA_ "FlexKomSID" SG_ 1033 Awake_NwSt 1370;
BA_ "FlexKomSigLaenge" SG_ 1033 Awake_NwSt 24;
BA_ "FlexKomSigName" SG_ 1033 Awake_NwSt "Awake_SBWM";
BA_ "FlexKomSigStartPos" SG_ 1033 Awake_NwSt 39;
BA_ "FlexKomSigStartValue" SG_ 1033 Awake_NwSt "000000h";
BA_ "GenSigSendType" SG_ 1033 Awake_NwSt 1;
BA_ "GenSigSNA" SG_ 1033 Awake_NwSt "0h";
BA_ "RID" SG_ 1033 Awake_NwSt "9615";
BA_ "FlexKomComment" SG_ 1033 Awake_URS "Mode 15 of NM_Ud_Srv";
BA_ "FlexKomIsMotorola" SG_ 1033 Awake_URS 1;
BA_ "FlexKomSID" SG_ 1033 Awake_URS 1370;
BA_ "FlexKomSigLaenge" SG_ 1033 Awake_URS 24;
BA_ "FlexKomSigName" SG_ 1033 Awake_URS "Awake_SBWM";
BA_ "FlexKomSigStartPos" SG_ 1033 Awake_URS 39;
BA_ "FlexKomSigStartValue" SG_ 1033 Awake_URS "000000h";
BA_ "GenSigSendType" SG_ 1033 Awake_URS 1;
BA_ "GenSigSNA" SG_ 1033 Awake_URS "0h";
BA_ "RID" SG_ 1033 Awake_URS "9616";
BA_ "FlexKomComment" SG_ 1033 NM_Mode "Network management state";
BA_ "FlexKomIsMotorola" SG_ 1033 NM_Mode 1;
BA_ "FlexKomSID" SG_ 1033 NM_Mode 472;
BA_ "FlexKomSigLaenge" SG_ 1033 NM_Mode 32;
BA_ "FlexKomSigName" SG_ 1033 NM_Mode "NM";
BA_ "FlexKomSigStartPos" SG_ 1033 NM_Mode 7;
BA_ "FlexKomSigStartValue" SG_ 1033 NM_Mode "FFFFFFFFh";
BA_ "GenSigSendType" SG_ 1033 NM_Mode 1;
BA_ "GenSigSNA" SG_ 1033 NM_Mode "FFh";
BA_ "GenSigStartValue" SG_ 1033 NM_Mode 255;
BA_ "RID" SG_ 1033 NM_Mode "9617";
BA_ "FlexKomComment" SG_ 1033 NM_Sleep_Ack "Network management state";
BA_ "FlexKomIsMotorola" SG_ 1033 NM_Sleep_Ack 1;
BA_ "FlexKomSID" SG_ 1033 NM_Sleep_Ack 472;
BA_ "FlexKomSigLaenge" SG_ 1033 NM_Sleep_Ack 32;
BA_ "FlexKomSigName" SG_ 1033 NM_Sleep_Ack "NM";
BA_ "FlexKomSigStartPos" SG_ 1033 NM_Sleep_Ack 7;
BA_ "FlexKomSigStartValue" SG_ 1033 NM_Sleep_Ack "FFFFFFFFh";
BA_ "GenSigSendType" SG_ 1033 NM_Sleep_Ack 1;
BA_ "GenSigSNA" SG_ 1033 NM_Sleep_Ack "1h";
BA_ "GenSigStartValue" SG_ 1033 NM_Sleep_Ack 1;
BA_ "RID" SG_ 1033 NM_Sleep_Ack "9618";
BA_ "FlexKomComment" SG_ 1033 NM_Sleep_Ind "Network management state";
BA_ "FlexKomIsMotorola" SG_ 1033 NM_Sleep_Ind 1;
BA_ "FlexKomSID" SG_ 1033 NM_Sleep_Ind 472;
BA_ "FlexKomSigLaenge" SG_ 1033 NM_Sleep_Ind 32;
BA_ "FlexKomSigName" SG_ 1033 NM_Sleep_Ind "NM";
BA_ "FlexKomSigStartPos" SG_ 1033 NM_Sleep_Ind 7;
BA_ "FlexKomSigStartValue" SG_ 1033 NM_Sleep_Ind "FFFFFFFFh";
BA_ "GenSigSendType" SG_ 1033 NM_Sleep_Ind 1;
BA_ "GenSigSNA" SG_ 1033 NM_Sleep_Ind "1h";
BA_ "GenSigStartValue" SG_ 1033 NM_Sleep_Ind 1;
BA_ "RID" SG_ 1033 NM_Sleep_Ind "9619";
BA_ "FlexKomComment" SG_ 1033 NM_Successor "Network management state";
BA_ "FlexKomIsMotorola" SG_ 1033 NM_Successor 1;
BA_ "FlexKomSID" SG_ 1033 NM_Successor 472;
BA_ "FlexKomSigLaenge" SG_ 1033 NM_Successor 32;
BA_ "FlexKomSigName" SG_ 1033 NM_Successor "NM";
BA_ "FlexKomSigStartPos" SG_ 1033 NM_Successor 7;
BA_ "FlexKomSigStartValue" SG_ 1033 NM_Successor "FFFFFFFFh";
BA_ "GenSigSendType" SG_ 1033 NM_Successor 1;
BA_ "GenSigSNA" SG_ 1033 NM_Successor "FFh";
BA_ "GenSigStartValue" SG_ 1033 NM_Successor 255;
BA_ "RID" SG_ 1033 NM_Successor "9620";
BA_ "FlexKomComment" SG_ 1033 NM_Ud_Launch "Network management state";
BA_ "FlexKomIsMotorola" SG_ 1033 NM_Ud_Launch 1;
BA_ "FlexKomSID" SG_ 1033 NM_Ud_Launch 472;
BA_ "FlexKomSigLaenge" SG_ 1033 NM_Ud_Launch 32;
BA_ "FlexKomSigName" SG_ 1033 NM_Ud_Launch "NM";
BA_ "FlexKomSigStartPos" SG_ 1033 NM_Ud_Launch 7;
BA_ "FlexKomSigStartValue" SG_ 1033 NM_Ud_Launch "FFFFFFFFh";
BA_ "GenSigSendType" SG_ 1033 NM_Ud_Launch 1;
BA_ "GenSigSNA" SG_ 1033 NM_Ud_Launch "3Fh";
BA_ "GenSigStartValue" SG_ 1033 NM_Ud_Launch 63;
BA_ "RID" SG_ 1033 NM_Ud_Launch "9621";
BA_ "FlexKomComment" SG_ 1033 NM_Ud_Srv "Network management state";
BA_ "FlexKomIsMotorola" SG_ 1033 NM_Ud_Srv 1;
BA_ "FlexKomSID" SG_ 1033 NM_Ud_Srv 472;
BA_ "FlexKomSigLaenge" SG_ 1033 NM_Ud_Srv 32;
BA_ "FlexKomSigName" SG_ 1033 NM_Ud_Srv "NM";
BA_ "FlexKomSigStartPos" SG_ 1033 NM_Ud_Srv 7;
BA_ "FlexKomSigStartValue" SG_ 1033 NM_Ud_Srv "FFFFFFFFh";
BA_ "GenSigSendType" SG_ 1033 NM_Ud_Srv 1;
BA_ "GenSigSNA" SG_ 1033 NM_Ud_Srv "FFh";
BA_ "GenSigStartValue" SG_ 1033 NM_Ud_Srv 255;
BA_ "RID" SG_ 1033 NM_Ud_Srv "9622";
BA_ "FlexKomComment" SG_ 1033 Nw_Id "Network identification no.";
BA_ "FlexKomIsMotorola" SG_ 1033 Nw_Id 1;
BA_ "FlexKomSID" SG_ 1033 Nw_Id 535;
BA_ "FlexKomSigLaenge" SG_ 1033 Nw_Id 8;
BA_ "FlexKomSigName" SG_ 1033 Nw_Id "Nw_Id";
BA_ "FlexKomSigStartPos" SG_ 1033 Nw_Id 63;
BA_ "FlexKomSigStartValue" SG_ 1033 Nw_Id "FFh";
BA_ "GenSigSendType" SG_ 1033 Nw_Id 1;
BA_ "GenSigSNA" SG_ 1033 Nw_Id "FFh";
BA_ "GenSigStartValue" SG_ 1033 Nw_Id 255;
BA_ "RID" SG_ 1033 Nw_Id "9623";
BA_ "FlexKomComment" SG_ 1033 WakeupCnt "Mode 2 of NM_Ud_Srv";
BA_ "FlexKomIsMotorola" SG_ 1033 WakeupCnt 1;
BA_ "FlexKomSID" SG_ 1033 WakeupCnt 1371;
BA_ "FlexKomSigLaenge" SG_ 1033 WakeupCnt 24;
BA_ "FlexKomSigName" SG_ 1033 WakeupCnt "Wakeup_SBWM";
BA_ "FlexKomSigStartPos" SG_ 1033 WakeupCnt 39;
BA_ "FlexKomSigStartValue" SG_ 1033 WakeupCnt "FFFF00h";
BA_ "GenSigSendType" SG_ 1033 WakeupCnt 1;
BA_ "GenSigSNA" SG_ 1033 WakeupCnt "FFh";
BA_ "GenSigStartValue" SG_ 1033 WakeupCnt 255;
BA_ "RID" SG_ 1033 WakeupCnt "9624";
BA_ "FlexKomComment" SG_ 1033 WakeupRsn_SBWM "Mode 2 of NM_Ud_Srv";
BA_ "FlexKomIsMotorola" SG_ 1033 WakeupRsn_SBWM 1;
BA_ "FlexKomSID" SG_ 1033 WakeupRsn_SBWM 1371;
BA_ "FlexKomSigLaenge" SG_ 1033 WakeupRsn_SBWM 24;
BA_ "FlexKomSigName" SG_ 1033 WakeupRsn_SBWM "Wakeup_SBWM";
BA_ "FlexKomSigStartPos" SG_ 1033 WakeupRsn_SBWM 39;
BA_ "FlexKomSigStartValue" SG_ 1033 WakeupRsn_SBWM "FFFF00h";
BA_ "GenSigSendType" SG_ 1033 WakeupRsn_SBWM 1;
BA_ "GenSigSNA" SG_ 1033 WakeupRsn_SBWM "FFh";
BA_ "GenSigStartValue" SG_ 1033 WakeupRsn_SBWM 255;
BA_ "RID" SG_ 1033 WakeupRsn_SBWM "9625";
BA_ "FlexKomComment" SG_ 1059 Awake_Diag_Actv "Mode 15 of NM_Ud_Srv";
BA_ "FlexKomIsMotorola" SG_ 1059 Awake_Diag_Actv 1;
BA_ "FlexKomSID" SG_ 1059 Awake_Diag_Actv 524;
BA_ "FlexKomSigLaenge" SG_ 1059 Awake_Diag_Actv 24;
BA_ "FlexKomSigName" SG_ 1059 Awake_Diag_Actv "Awake_SCCM_Pkt";
BA_ "FlexKomSigStartPos" SG_ 1059 Awake_Diag_Actv 39;
BA_ "FlexKomSigStartValue" SG_ 1059 Awake_Diag_Actv "000000h";
BA_ "GenSigSendType" SG_ 1059 Awake_Diag_Actv 1;
BA_ "GenSigSNA" SG_ 1059 Awake_Diag_Actv "0h";
BA_ "RID" SG_ 1059 Awake_Diag_Actv "9726";
BA_ "FlexKomComment" SG_ 1059 Awake_EEPROM "Mode 15 of NM_Ud_Srv";
BA_ "FlexKomIsMotorola" SG_ 1059 Awake_EEPROM 1;
BA_ "FlexKomSID" SG_ 1059 Awake_EEPROM 524;
BA_ "FlexKomSigLaenge" SG_ 1059 Awake_EEPROM 24;
BA_ "FlexKomSigName" SG_ 1059 Awake_EEPROM "Awake_SCCM_Pkt";
BA_ "FlexKomSigStartPos" SG_ 1059 Awake_EEPROM 39;
BA_ "FlexKomSigStartValue" SG_ 1059 Awake_EEPROM "000000h";
BA_ "GenSigSendType" SG_ 1059 Awake_EEPROM 1;
BA_ "GenSigSNA" SG_ 1059 Awake_EEPROM "0h";
BA_ "RID" SG_ 1059 Awake_EEPROM "9727";
BA_ "FlexKomComment" SG_ 1059 Awake_FTP_Psd "Mode 15 of NM_Ud_Srv";
BA_ "FlexKomIsMotorola" SG_ 1059 Awake_FTP_Psd 1;
BA_ "FlexKomSID" SG_ 1059 Awake_FTP_Psd 524;
BA_ "FlexKomSigLaenge" SG_ 1059 Awake_FTP_Psd 24;
BA_ "FlexKomSigName" SG_ 1059 Awake_FTP_Psd "Awake_SCCM_Pkt";
BA_ "FlexKomSigStartPos" SG_ 1059 Awake_FTP_Psd 39;
BA_ "FlexKomSigStartValue" SG_ 1059 Awake_FTP_Psd "000000h";
BA_ "GenSigSendType" SG_ 1059 Awake_FTP_Psd 1;
BA_ "GenSigSNA" SG_ 1059 Awake_FTP_Psd "0h";
BA_ "RID" SG_ 1059 Awake_FTP_Psd "9728";
BA_ "FlexKomComment" SG_ 1059 Awake_HrnSwt_Actv "Mode 15 of NM_Ud_Srv";
BA_ "FlexKomIsMotorola" SG_ 1059 Awake_HrnSwt_Actv 1;
BA_ "FlexKomSID" SG_ 1059 Awake_HrnSwt_Actv 524;
BA_ "FlexKomSigLaenge" SG_ 1059 Awake_HrnSwt_Actv 24;
BA_ "FlexKomSigName" SG_ 1059 Awake_HrnSwt_Actv "Awake_SCCM_Pkt";
BA_ "FlexKomSigStartPos" SG_ 1059 Awake_HrnSwt_Actv 39;
BA_ "FlexKomSigStartValue" SG_ 1059 Awake_HrnSwt_Actv "000000h";
BA_ "GenSigSendType" SG_ 1059 Awake_HrnSwt_Actv 1;
BA_ "GenSigSNA" SG_ 1059 Awake_HrnSwt_Actv "0h";
BA_ "RID" SG_ 1059 Awake_HrnSwt_Actv "9729";
BA_ "FlexKomComment" SG_ 1059 Awake_Ignition_On "Mode 15 of NM_Ud_Srv";
BA_ "FlexKomIsMotorola" SG_ 1059 Awake_Ignition_On 1;
BA_ "FlexKomSID" SG_ 1059 Awake_Ignition_On 524;
BA_ "FlexKomSigLaenge" SG_ 1059 Awake_Ignition_On 24;
BA_ "FlexKomSigName" SG_ 1059 Awake_Ignition_On "Awake_SCCM_Pkt";
BA_ "FlexKomSigStartPos" SG_ 1059 Awake_Ignition_On 39;
BA_ "FlexKomSigStartValue" SG_ 1059 Awake_Ignition_On "000000h";
BA_ "GenSigSendType" SG_ 1059 Awake_Ignition_On 1;
BA_ "GenSigSNA" SG_ 1059 Awake_Ignition_On "0h";
BA_ "RID" SG_ 1059 Awake_Ignition_On "9730";
BA_ "FlexKomComment" SG_ 1059 Awake_NwSt "Mode 15 of NM_Ud_Srv";
BA_ "FlexKomIsMotorola" SG_ 1059 Awake_NwSt 1;
BA_ "FlexKomSID" SG_ 1059 Awake_NwSt 524;
BA_ "FlexKomSigLaenge" SG_ 1059 Awake_NwSt 24;
BA_ "FlexKomSigName" SG_ 1059 Awake_NwSt "Awake_SCCM_Pkt";
BA_ "FlexKomSigStartPos" SG_ 1059 Awake_NwSt 39;
BA_ "FlexKomSigStartValue" SG_ 1059 Awake_NwSt "000000h";
BA_ "GenSigSendType" SG_ 1059 Awake_NwSt 1;
BA_ "GenSigSNA" SG_ 1059 Awake_NwSt "0h";
BA_ "RID" SG_ 1059 Awake_NwSt "9731";
BA_ "FlexKomComment" SG_ 1059 Awake_StwSw_Actv "Mode 15 of NM_Ud_Srv";
BA_ "FlexKomIsMotorola" SG_ 1059 Awake_StwSw_Actv 1;
BA_ "FlexKomSID" SG_ 1059 Awake_StwSw_Actv 524;
BA_ "FlexKomSigLaenge" SG_ 1059 Awake_StwSw_Actv 24;
BA_ "FlexKomSigName" SG_ 1059 Awake_StwSw_Actv "Awake_SCCM_Pkt";
BA_ "FlexKomSigStartPos" SG_ 1059 Awake_StwSw_Actv 39;
BA_ "FlexKomSigStartValue" SG_ 1059 Awake_StwSw_Actv "000000h";
BA_ "GenSigSendType" SG_ 1059 Awake_StwSw_Actv 1;
BA_ "GenSigSNA" SG_ 1059 Awake_StwSw_Actv "0h";
BA_ "RID" SG_ 1059 Awake_StwSw_Actv "9732";
BA_ "FlexKomComment" SG_ 1059 Awake_tilt_tel_Psd "Mode 15 of NM_Ud_Srv";
BA_ "FlexKomIsMotorola" SG_ 1059 Awake_tilt_tel_Psd 1;
BA_ "FlexKomSID" SG_ 1059 Awake_tilt_tel_Psd 524;
BA_ "FlexKomSigLaenge" SG_ 1059 Awake_tilt_tel_Psd 24;
BA_ "FlexKomSigName" SG_ 1059 Awake_tilt_tel_Psd "Awake_SCCM_Pkt";
BA_ "FlexKomSigStartPos" SG_ 1059 Awake_tilt_tel_Psd 39;
BA_ "FlexKomSigStartValue" SG_ 1059 Awake_tilt_tel_Psd "000000h";
BA_ "GenSigSendType" SG_ 1059 Awake_tilt_tel_Psd 1;
BA_ "GenSigSNA" SG_ 1059 Awake_tilt_tel_Psd "0h";
BA_ "RID" SG_ 1059 Awake_tilt_tel_Psd "9733";
BA_ "FlexKomComment" SG_ 1059 NM_Mode "Network management state";
BA_ "FlexKomIsMotorola" SG_ 1059 NM_Mode 1;
BA_ "FlexKomSID" SG_ 1059 NM_Mode 472;
BA_ "FlexKomSigLaenge" SG_ 1059 NM_Mode 32;
BA_ "FlexKomSigName" SG_ 1059 NM_Mode "NM";
BA_ "FlexKomSigStartPos" SG_ 1059 NM_Mode 7;
BA_ "FlexKomSigStartValue" SG_ 1059 NM_Mode "FFFFFFFFh";
BA_ "GenSigSendType" SG_ 1059 NM_Mode 1;
BA_ "GenSigSNA" SG_ 1059 NM_Mode "FFh";
BA_ "GenSigStartValue" SG_ 1059 NM_Mode 255;
BA_ "RID" SG_ 1059 NM_Mode "9734";
BA_ "FlexKomComment" SG_ 1059 NM_Sleep_Ack "Network management state";
BA_ "FlexKomIsMotorola" SG_ 1059 NM_Sleep_Ack 1;
BA_ "FlexKomSID" SG_ 1059 NM_Sleep_Ack 472;
BA_ "FlexKomSigLaenge" SG_ 1059 NM_Sleep_Ack 32;
BA_ "FlexKomSigName" SG_ 1059 NM_Sleep_Ack "NM";
BA_ "FlexKomSigStartPos" SG_ 1059 NM_Sleep_Ack 7;
BA_ "FlexKomSigStartValue" SG_ 1059 NM_Sleep_Ack "FFFFFFFFh";
BA_ "GenSigSendType" SG_ 1059 NM_Sleep_Ack 1;
BA_ "GenSigSNA" SG_ 1059 NM_Sleep_Ack "1h";
BA_ "GenSigStartValue" SG_ 1059 NM_Sleep_Ack 1;
BA_ "RID" SG_ 1059 NM_Sleep_Ack "9735";
BA_ "FlexKomComment" SG_ 1059 NM_Sleep_Ind "Network management state";
BA_ "FlexKomIsMotorola" SG_ 1059 NM_Sleep_Ind 1;
BA_ "FlexKomSID" SG_ 1059 NM_Sleep_Ind 472;
BA_ "FlexKomSigLaenge" SG_ 1059 NM_Sleep_Ind 32;
BA_ "FlexKomSigName" SG_ 1059 NM_Sleep_Ind "NM";
BA_ "FlexKomSigStartPos" SG_ 1059 NM_Sleep_Ind 7;
BA_ "FlexKomSigStartValue" SG_ 1059 NM_Sleep_Ind "FFFFFFFFh";
BA_ "GenSigSendType" SG_ 1059 NM_Sleep_Ind 1;
BA_ "GenSigSNA" SG_ 1059 NM_Sleep_Ind "1h";
BA_ "GenSigStartValue" SG_ 1059 NM_Sleep_Ind 1;
BA_ "RID" SG_ 1059 NM_Sleep_Ind "9736";
BA_ "FlexKomComment" SG_ 1059 NM_Successor "Network management state";
BA_ "FlexKomIsMotorola" SG_ 1059 NM_Successor 1;
BA_ "FlexKomSID" SG_ 1059 NM_Successor 472;
BA_ "FlexKomSigLaenge" SG_ 1059 NM_Successor 32;
BA_ "FlexKomSigName" SG_ 1059 NM_Successor "NM";
BA_ "FlexKomSigStartPos" SG_ 1059 NM_Successor 7;
BA_ "FlexKomSigStartValue" SG_ 1059 NM_Successor "FFFFFFFFh";
BA_ "GenSigSendType" SG_ 1059 NM_Successor 1;
BA_ "GenSigSNA" SG_ 1059 NM_Successor "FFh";
BA_ "GenSigStartValue" SG_ 1059 NM_Successor 255;
BA_ "RID" SG_ 1059 NM_Successor "9737";
BA_ "FlexKomComment" SG_ 1059 NM_Ud_Launch "Network management state";
BA_ "FlexKomIsMotorola" SG_ 1059 NM_Ud_Launch 1;
BA_ "FlexKomSID" SG_ 1059 NM_Ud_Launch 472;
BA_ "FlexKomSigLaenge" SG_ 1059 NM_Ud_Launch 32;
BA_ "FlexKomSigName" SG_ 1059 NM_Ud_Launch "NM";
BA_ "FlexKomSigStartPos" SG_ 1059 NM_Ud_Launch 7;
BA_ "FlexKomSigStartValue" SG_ 1059 NM_Ud_Launch "FFFFFFFFh";
BA_ "GenSigSendType" SG_ 1059 NM_Ud_Launch 1;
BA_ "GenSigSNA" SG_ 1059 NM_Ud_Launch "3Fh";
BA_ "GenSigStartValue" SG_ 1059 NM_Ud_Launch 63;
BA_ "RID" SG_ 1059 NM_Ud_Launch "9738";
BA_ "FlexKomComment" SG_ 1059 NM_Ud_Srv "Network management state";
BA_ "FlexKomIsMotorola" SG_ 1059 NM_Ud_Srv 1;
BA_ "FlexKomSID" SG_ 1059 NM_Ud_Srv 472;
BA_ "FlexKomSigLaenge" SG_ 1059 NM_Ud_Srv 32;
BA_ "FlexKomSigName" SG_ 1059 NM_Ud_Srv "NM";
BA_ "FlexKomSigStartPos" SG_ 1059 NM_Ud_Srv 7;
BA_ "FlexKomSigStartValue" SG_ 1059 NM_Ud_Srv "FFFFFFFFh";
BA_ "GenSigSendType" SG_ 1059 NM_Ud_Srv 1;
BA_ "GenSigSNA" SG_ 1059 NM_Ud_Srv "FFh";
BA_ "GenSigStartValue" SG_ 1059 NM_Ud_Srv 255;
BA_ "RID" SG_ 1059 NM_Ud_Srv "9739";
BA_ "FlexKomComment" SG_ 1059 Nw_Id "Network identification no.";
BA_ "FlexKomIsMotorola" SG_ 1059 Nw_Id 1;
BA_ "FlexKomSID" SG_ 1059 Nw_Id 535;
BA_ "FlexKomSigLaenge" SG_ 1059 Nw_Id 8;
BA_ "FlexKomSigName" SG_ 1059 Nw_Id "Nw_Id";
BA_ "FlexKomSigStartPos" SG_ 1059 Nw_Id 63;
BA_ "FlexKomSigStartValue" SG_ 1059 Nw_Id "FFh";
BA_ "GenSigSendType" SG_ 1059 Nw_Id 1;
BA_ "GenSigSNA" SG_ 1059 Nw_Id "FFh";
BA_ "GenSigStartValue" SG_ 1059 Nw_Id 255;
BA_ "RID" SG_ 1059 Nw_Id "9740";
BA_ "FlexKomComment" SG_ 1059 WakeupCnt "Mode 2 of NM_Ud_Srv";
BA_ "FlexKomIsMotorola" SG_ 1059 WakeupCnt 1;
BA_ "FlexKomSID" SG_ 1059 WakeupCnt 494;
BA_ "FlexKomSigLaenge" SG_ 1059 WakeupCnt 24;
BA_ "FlexKomSigName" SG_ 1059 WakeupCnt "Wakeup_SCCM_Pkt";
BA_ "FlexKomSigStartPos" SG_ 1059 WakeupCnt 39;
BA_ "FlexKomSigStartValue" SG_ 1059 WakeupCnt "FFFF00h";
BA_ "GenSigSendType" SG_ 1059 WakeupCnt 1;
BA_ "GenSigSNA" SG_ 1059 WakeupCnt "FFh";
BA_ "GenSigStartValue" SG_ 1059 WakeupCnt 255;
BA_ "RID" SG_ 1059 WakeupCnt "9741";
BA_ "FlexKomComment" SG_ 1059 WakeupRsn_SCCM "Mode 2 of NM_Ud_Srv";
BA_ "FlexKomIsMotorola" SG_ 1059 WakeupRsn_SCCM 1;
BA_ "FlexKomSID" SG_ 1059 WakeupRsn_SCCM 494;
BA_ "FlexKomSigLaenge" SG_ 1059 WakeupRsn_SCCM 24;
BA_ "FlexKomSigName" SG_ 1059 WakeupRsn_SCCM "Wakeup_SCCM_Pkt";
BA_ "FlexKomSigStartPos" SG_ 1059 WakeupRsn_SCCM 39;
BA_ "FlexKomSigStartValue" SG_ 1059 WakeupRsn_SCCM "FFFF00h";
BA_ "GenSigSendType" SG_ 1059 WakeupRsn_SCCM 1;
BA_ "GenSigSNA" SG_ 1059 WakeupRsn_SCCM "FFh";
BA_ "GenSigStartValue" SG_ 1059 WakeupRsn_SCCM 255;
BA_ "RID" SG_ 1059 WakeupRsn_SCCM "9742";
BA_ "FlexKomComment" SG_ 528 CRC_OCM_A1 "Passenger occupant classification system status";
BA_ "FlexKomIsMotorola" SG_ 528 CRC_OCM_A1 1;
BA_ "FlexKomSID" SG_ 528 CRC_OCM_A1 1586;
BA_ "FlexKomSigLaenge" SG_ 528 CRC_OCM_A1 64;
BA_ "FlexKomSigName" SG_ 528 CRC_OCM_A1 "OC_P_Stat";
BA_ "FlexKomSigStartPos" SG_ 528 CRC_OCM_A1 7;
BA_ "FlexKomSigStartValue" SG_ 528 CRC_OCM_A1 "0F0F0000000000FFh";
BA_ "GenSigCycleTime" SG_ 528 CRC_OCM_A1 1000;
BA_ "GenSigSendType" SG_ 528 CRC_OCM_A1 5;
BA_ "GenSigSNA" SG_ 528 CRC_OCM_A1 "FFh";
BA_ "GenSigStartValue" SG_ 528 CRC_OCM_A1 255;
BA_ "GenSigTimeout_ORC" SG_ 528 CRC_OCM_A1 3500;
BA_ "FlexKomComment" SG_ 528 MC_OCM_A1 "Passenger occupant classification system status";
BA_ "FlexKomIsMotorola" SG_ 528 MC_OCM_A1 1;
BA_ "FlexKomSID" SG_ 528 MC_OCM_A1 1586;
BA_ "FlexKomSigLaenge" SG_ 528 MC_OCM_A1 64;
BA_ "FlexKomSigName" SG_ 528 MC_OCM_A1 "OC_P_Stat";
BA_ "FlexKomSigStartPos" SG_ 528 MC_OCM_A1 7;
BA_ "FlexKomSigStartValue" SG_ 528 MC_OCM_A1 "0F0F0000000000FFh";
BA_ "GenSigCycleTime" SG_ 528 MC_OCM_A1 1000;
BA_ "GenSigSendType" SG_ 528 MC_OCM_A1 5;
BA_ "GenSigSNA" SG_ 528 MC_OCM_A1 "0h";
BA_ "GenSigTimeout_ORC" SG_ 528 MC_OCM_A1 3500;
BA_ "FlexKomComment" SG_ 528 PsgSeatOCFaultSts "Passenger occupant classification system status";
BA_ "FlexKomIsMotorola" SG_ 528 PsgSeatOCFaultSts 1;
BA_ "FlexKomSID" SG_ 528 PsgSeatOCFaultSts 1586;
BA_ "FlexKomSigLaenge" SG_ 528 PsgSeatOCFaultSts 64;
BA_ "FlexKomSigName" SG_ 528 PsgSeatOCFaultSts "OC_P_Stat";
BA_ "FlexKomSigStartPos" SG_ 528 PsgSeatOCFaultSts 7;
BA_ "FlexKomSigStartValue" SG_ 528 PsgSeatOCFaultSts "0F0F0000000000FFh";
BA_ "GenSigCycleTime" SG_ 528 PsgSeatOCFaultSts 1000;
BA_ "GenSigSendType" SG_ 528 PsgSeatOCFaultSts 5;
BA_ "GenSigSNA" SG_ 528 PsgSeatOCFaultSts "0h";
BA_ "GenSigTimeout_ORC" SG_ 528 PsgSeatOCFaultSts 3500;
BA_ "FlexKomComment" SG_ 528 PsgSeatOCSts "Passenger occupant classification system status";
BA_ "FlexKomIsMotorola" SG_ 528 PsgSeatOCSts 1;
BA_ "FlexKomSID" SG_ 528 PsgSeatOCSts 1586;
BA_ "FlexKomSigLaenge" SG_ 528 PsgSeatOCSts 64;
BA_ "FlexKomSigName" SG_ 528 PsgSeatOCSts "OC_P_Stat";
BA_ "FlexKomSigStartPos" SG_ 528 PsgSeatOCSts 7;
BA_ "FlexKomSigStartValue" SG_ 528 PsgSeatOCSts "0F0F0000000000FFh";
BA_ "GenSigCycleTime" SG_ 528 PsgSeatOCSts 1000;
BA_ "GenSigSendType" SG_ 528 PsgSeatOCSts 5;
BA_ "GenSigSNA" SG_ 528 PsgSeatOCSts "Fh";
BA_ "GenSigStartValue" SG_ 528 PsgSeatOCSts 15;
BA_ "GenSigTimeout_ORC" SG_ 528 PsgSeatOCSts 3500;
BA_ "FlexKomComment" SG_ 528 PsgSeatSBRSts "Passenger occupant classification system status";
BA_ "FlexKomIsMotorola" SG_ 528 PsgSeatSBRSts 1;
BA_ "FlexKomSID" SG_ 528 PsgSeatSBRSts 1586;
BA_ "FlexKomSigLaenge" SG_ 528 PsgSeatSBRSts 64;
BA_ "FlexKomSigName" SG_ 528 PsgSeatSBRSts "OC_P_Stat";
BA_ "FlexKomSigStartPos" SG_ 528 PsgSeatSBRSts 7;
BA_ "FlexKomSigStartValue" SG_ 528 PsgSeatSBRSts "0F0F0000000000FFh";
BA_ "GenSigCycleTime" SG_ 528 PsgSeatSBRSts 1000;
BA_ "GenSigSendType" SG_ 528 PsgSeatSBRSts 5;
BA_ "GenSigSNA" SG_ 528 PsgSeatSBRSts "Fh";
BA_ "GenSigStartValue" SG_ 528 PsgSeatSBRSts 15;
BA_ "GenSigTimeout_ORC" SG_ 528 PsgSeatSBRSts 3500;
BA_ "FlexKomComment" SG_ 464 DRV_SEATBELT "Drivers seat belt status";
BA_ "FlexKomIsMotorola" SG_ 464 DRV_SEATBELT 1;
BA_ "FlexKomSID" SG_ 464 DRV_SEATBELT 330;
BA_ "FlexKomSigLaenge" SG_ 464 DRV_SEATBELT 2;
BA_ "FlexKomSigName" SG_ 464 DRV_SEATBELT "DRV_SEATBELT";
BA_ "FlexKomSigStartPos" SG_ 464 DRV_SEATBELT 17;
BA_ "FlexKomSigStartValue" SG_ 464 DRV_SEATBELT "03h";
BA_ "GenSigCycleTime" SG_ 464 DRV_SEATBELT 1000;
BA_ "GenSigSendType" SG_ 464 DRV_SEATBELT 5;
BA_ "GenSigSNA" SG_ 464 DRV_SEATBELT "3h";
BA_ "GenSigStartValue" SG_ 464 DRV_SEATBELT 3;
BA_ "GenSigTimeout_CBC" SG_ 464 DRV_SEATBELT 10500;
BA_ "GenSigTimeout_ETM" SG_ 464 DRV_SEATBELT 10500;
BA_ "GenSigTimeout_IC" SG_ 464 DRV_SEATBELT 10500;
BA_ "GenSigTimeout_PTS" SG_ 464 DRV_SEATBELT 10500;
BA_ "RID" SG_ 464 DRV_SEATBELT "1107";
BA_ "FlexKomComment" SG_ 464 DrvSbltUnFltr "Drivers seat belt fault status - unfiltered";
BA_ "FlexKomIsMotorola" SG_ 464 DrvSbltUnFltr 1;
BA_ "FlexKomSID" SG_ 464 DrvSbltUnFltr 1814;
BA_ "FlexKomSigLaenge" SG_ 464 DrvSbltUnFltr 3;
BA_ "FlexKomSigName" SG_ 464 DrvSbltUnFltr "DrvSbltUnFltr";
BA_ "FlexKomSigStartPos" SG_ 464 DrvSbltUnFltr 15;
BA_ "FlexKomSigStartValue" SG_ 464 DrvSbltUnFltr "07h";
BA_ "GenSigCycleTime" SG_ 464 DrvSbltUnFltr 1000;
BA_ "GenSigSendType" SG_ 464 DrvSbltUnFltr 5;
BA_ "GenSigSNA" SG_ 464 DrvSbltUnFltr "7h";
BA_ "GenSigStartValue" SG_ 464 DrvSbltUnFltr 7;
BA_ "RID" SG_ 464 DrvSbltUnFltr "1973";
BA_ "FlexKomComment" SG_ 464 ORC_A1_Par "ORC_A1 even parity bit";
BA_ "FlexKomIsMotorola" SG_ 464 ORC_A1_Par 1;
BA_ "FlexKomSID" SG_ 464 ORC_A1_Par 1903;
BA_ "FlexKomSigLaenge" SG_ 464 ORC_A1_Par 1;
BA_ "FlexKomSigName" SG_ 464 ORC_A1_Par "ORC_A1_Par";
BA_ "FlexKomSigStartPos" SG_ 464 ORC_A1_Par 7;
BA_ "FlexKomSigStartValue" SG_ 464 ORC_A1_Par "00h";
BA_ "GenSigCycleTime" SG_ 464 ORC_A1_Par 1000;
BA_ "GenSigSendType" SG_ 464 ORC_A1_Par 5;
BA_ "GenSigSNA" SG_ 464 ORC_A1_Par "0h";
BA_ "RID" SG_ 464 ORC_A1_Par "1961";
BA_ "FlexKomComment" SG_ 464 ORC_A1_Tog "ORC_A1 toggle bit";
BA_ "FlexKomIsMotorola" SG_ 464 ORC_A1_Tog 1;
BA_ "FlexKomSID" SG_ 464 ORC_A1_Tog 1902;
BA_ "FlexKomSigLaenge" SG_ 464 ORC_A1_Tog 1;
BA_ "FlexKomSigName" SG_ 464 ORC_A1_Tog "ORC_A1_Tog";
BA_ "FlexKomSigStartPos" SG_ 464 ORC_A1_Tog 1;
BA_ "FlexKomSigStartValue" SG_ 464 ORC_A1_Tog "00h";
BA_ "GenSigCycleTime" SG_ 464 ORC_A1_Tog 1000;
BA_ "GenSigSendType" SG_ 464 ORC_A1_Tog 5;
BA_ "GenSigSNA" SG_ 464 ORC_A1_Tog "0h";
BA_ "RID" SG_ 464 ORC_A1_Tog "1970";
BA_ "FlexKomComment" SG_ 464 PSG_ODS_STAT "Passenger Occupant Detection Sensor Status";
BA_ "FlexKomIsMotorola" SG_ 464 PSG_ODS_STAT 1;
BA_ "FlexKomSID" SG_ 464 PSG_ODS_STAT 426;
BA_ "FlexKomSigLaenge" SG_ 464 PSG_ODS_STAT 2;
BA_ "FlexKomSigName" SG_ 464 PSG_ODS_STAT "PSG_ODS_STAT";
BA_ "FlexKomSigStartPos" SG_ 464 PSG_ODS_STAT 27;
BA_ "FlexKomSigStartValue" SG_ 464 PSG_ODS_STAT "03h";
BA_ "GenSigCycleTime" SG_ 464 PSG_ODS_STAT 1000;
BA_ "GenSigSendType" SG_ 464 PSG_ODS_STAT 5;
BA_ "GenSigSNA" SG_ 464 PSG_ODS_STAT "3h";
BA_ "GenSigStartValue" SG_ 464 PSG_ODS_STAT 3;
BA_ "GenSigTimeout_CBC" SG_ 464 PSG_ODS_STAT 10500;
BA_ "GenSigTimeout_ETM" SG_ 464 PSG_ODS_STAT 10500;
BA_ "GenSigTimeout_IC" SG_ 464 PSG_ODS_STAT 10500;
BA_ "RID" SG_ 464 PSG_ODS_STAT "1142";
BA_ "FlexKomComment" SG_ 464 PSG_SEATBELT "Passengers seat belt status";
BA_ "FlexKomIsMotorola" SG_ 464 PSG_SEATBELT 1;
BA_ "FlexKomSID" SG_ 464 PSG_SEATBELT 331;
BA_ "FlexKomSigLaenge" SG_ 464 PSG_SEATBELT 2;
BA_ "FlexKomSigName" SG_ 464 PSG_SEATBELT "PSG_SEATBELT";
BA_ "FlexKomSigStartPos" SG_ 464 PSG_SEATBELT 19;
BA_ "FlexKomSigStartValue" SG_ 464 PSG_SEATBELT "03h";
BA_ "GenSigCycleTime" SG_ 464 PSG_SEATBELT 1000;
BA_ "GenSigSendType" SG_ 464 PSG_SEATBELT 5;
BA_ "GenSigSNA" SG_ 464 PSG_SEATBELT "3h";
BA_ "GenSigStartValue" SG_ 464 PSG_SEATBELT 3;
BA_ "GenSigTimeout_CBC" SG_ 464 PSG_SEATBELT 10500;
BA_ "GenSigTimeout_ETM" SG_ 464 PSG_SEATBELT 10500;
BA_ "GenSigTimeout_IC" SG_ 464 PSG_SEATBELT 10500;
BA_ "RID" SG_ 464 PSG_SEATBELT "1160";
BA_ "FlexKomComment" SG_ 464 SRS_IndLmp_Rq "SRS indication lamp request";
BA_ "FlexKomIsMotorola" SG_ 464 SRS_IndLmp_Rq 1;
BA_ "FlexKomSID" SG_ 464 SRS_IndLmp_Rq 329;
BA_ "FlexKomSigLaenge" SG_ 464 SRS_IndLmp_Rq 2;
BA_ "FlexKomSigName" SG_ 464 SRS_IndLmp_Rq "SRS_IndLmp_Rq";
BA_ "FlexKomSigStartPos" SG_ 464 SRS_IndLmp_Rq 3;
BA_ "FlexKomSigStartValue" SG_ 464 SRS_IndLmp_Rq "01h";
BA_ "GenSigCycleTime" SG_ 464 SRS_IndLmp_Rq 1000;
BA_ "GenSigSendType" SG_ 464 SRS_IndLmp_Rq 5;
BA_ "GenSigSNA" SG_ 464 SRS_IndLmp_Rq "3h";
BA_ "GenSigStartValue" SG_ 464 SRS_IndLmp_Rq 1;
BA_ "GenSigTimeout_CBC" SG_ 464 SRS_IndLmp_Rq 5500;
BA_ "GenSigTimeout_ETM" SG_ 464 SRS_IndLmp_Rq 10500;
BA_ "GenSigTimeout_IC" SG_ 464 SRS_IndLmp_Rq 10500;
BA_ "RID" SG_ 464 SRS_IndLmp_Rq "1152";
BA_ "FlexKomComment" SG_ 466 IMPACT_B "Impact events";
BA_ "FlexKomIsMotorola" SG_ 466 IMPACT_B 1;
BA_ "FlexKomSID" SG_ 466 IMPACT_B 325;
BA_ "FlexKomSigLaenge" SG_ 466 IMPACT_B 16;
BA_ "FlexKomSigName" SG_ 466 IMPACT_B "IMPACT";
BA_ "FlexKomSigStartPos" SG_ 466 IMPACT_B 7;
BA_ "FlexKomSigStartValue" SG_ 466 IMPACT_B "0000h";
BA_ "GenSigCycleTimeActive" SG_ 466 IMPACT_B 20;
BA_ "GenSigSendType" SG_ 466 IMPACT_B 2;
BA_ "GenSigSNA" SG_ 466 IMPACT_B "0h";
BA_ "RID" SG_ 466 IMPACT_B "1278";
BA_ "FlexKomComment" SG_ 466 IMPACT_C "Impact events";
BA_ "FlexKomIsMotorola" SG_ 466 IMPACT_C 1;
BA_ "FlexKomSID" SG_ 466 IMPACT_C 325;
BA_ "FlexKomSigLaenge" SG_ 466 IMPACT_C 16;
BA_ "FlexKomSigName" SG_ 466 IMPACT_C "IMPACT";
BA_ "FlexKomSigStartPos" SG_ 466 IMPACT_C 7;
BA_ "FlexKomSigStartValue" SG_ 466 IMPACT_C "0000h";
BA_ "GenSigCycleTimeActive" SG_ 466 IMPACT_C 20;
BA_ "GenSigSendType" SG_ 466 IMPACT_C 2;
BA_ "GenSigSNA" SG_ 466 IMPACT_C "0h";
BA_ "RID" SG_ 466 IMPACT_C "1032";
BA_ "FlexKomComment" SG_ 466 IMPACT_I "Impact events";
BA_ "FlexKomIsMotorola" SG_ 466 IMPACT_I 1;
BA_ "FlexKomSID" SG_ 466 IMPACT_I 325;
BA_ "FlexKomSigLaenge" SG_ 466 IMPACT_I 16;
BA_ "FlexKomSigName" SG_ 466 IMPACT_I "IMPACT";
BA_ "FlexKomSigStartPos" SG_ 466 IMPACT_I 7;
BA_ "FlexKomSigStartValue" SG_ 466 IMPACT_I "0000h";
BA_ "GenSigCycleTimeActive" SG_ 466 IMPACT_I 20;
BA_ "GenSigSendType" SG_ 466 IMPACT_I 2;
BA_ "GenSigSNA" SG_ 466 IMPACT_I "0h";
BA_ "RID" SG_ 466 IMPACT_I "1034";
BA_ "FlexKomComment" SG_ 466 IMPACT_L "Impact events";
BA_ "FlexKomIsMotorola" SG_ 466 IMPACT_L 1;
BA_ "FlexKomSID" SG_ 466 IMPACT_L 325;
BA_ "FlexKomSigLaenge" SG_ 466 IMPACT_L 16;
BA_ "FlexKomSigName" SG_ 466 IMPACT_L "IMPACT";
BA_ "FlexKomSigStartPos" SG_ 466 IMPACT_L 7;
BA_ "FlexKomSigStartValue" SG_ 466 IMPACT_L "0000h";
BA_ "GenSigCycleTimeActive" SG_ 466 IMPACT_L 20;
BA_ "GenSigSendType" SG_ 466 IMPACT_L 2;
BA_ "GenSigSNA" SG_ 466 IMPACT_L "0h";
BA_ "RID" SG_ 466 IMPACT_L "1073";
BA_ "FlexKomComment" SG_ 466 IMPACT_X "Impact events";
BA_ "FlexKomIsMotorola" SG_ 466 IMPACT_X 1;
BA_ "FlexKomSID" SG_ 466 IMPACT_X 325;
BA_ "FlexKomSigLaenge" SG_ 466 IMPACT_X 16;
BA_ "FlexKomSigName" SG_ 466 IMPACT_X "IMPACT";
BA_ "FlexKomSigStartPos" SG_ 466 IMPACT_X 7;
BA_ "FlexKomSigStartValue" SG_ 466 IMPACT_X "0000h";
BA_ "GenSigCycleTimeActive" SG_ 466 IMPACT_X 20;
BA_ "GenSigSendType" SG_ 466 IMPACT_X 2;
BA_ "GenSigSNA" SG_ 466 IMPACT_X "0h";
BA_ "RID" SG_ 466 IMPACT_X "1273 2130";
BA_ "FlexKomComment" SG_ 466 Impact_F "Impact events";
BA_ "FlexKomIsMotorola" SG_ 466 Impact_F 1;
BA_ "FlexKomSID" SG_ 466 Impact_F 325;
BA_ "FlexKomSigLaenge" SG_ 466 Impact_F 16;
BA_ "FlexKomSigName" SG_ 466 Impact_F "IMPACT";
BA_ "FlexKomSigStartPos" SG_ 466 Impact_F 7;
BA_ "FlexKomSigStartValue" SG_ 466 Impact_F "0000h";
BA_ "GenSigCycleTimeActive" SG_ 466 Impact_F 20;
BA_ "GenSigSendType" SG_ 466 Impact_F 2;
BA_ "GenSigSNA" SG_ 466 Impact_F "0h";
BA_ "RID" SG_ 466 Impact_F "1249";
BA_ "FlexKomComment" SG_ 466 Impact_Tgl "Impact events";
BA_ "FlexKomIsMotorola" SG_ 466 Impact_Tgl 1;
BA_ "FlexKomSID" SG_ 466 Impact_Tgl 325;
BA_ "FlexKomSigLaenge" SG_ 466 Impact_Tgl 16;
BA_ "FlexKomSigName" SG_ 466 Impact_Tgl "IMPACT";
BA_ "FlexKomSigStartPos" SG_ 466 Impact_Tgl 7;
BA_ "FlexKomSigStartValue" SG_ 466 Impact_Tgl "0000h";
BA_ "GenSigCycleTimeActive" SG_ 466 Impact_Tgl 20;
BA_ "GenSigSendType" SG_ 466 Impact_Tgl 2;
BA_ "GenSigSNA" SG_ 466 Impact_Tgl "0h";
BA_ "RID" SG_ 466 Impact_Tgl "1060 2149";
BA_ "FlexKomComment" SG_ 469 ORC_Health "ORC A4 packet";
BA_ "FlexKomIsMotorola" SG_ 469 ORC_Health 1;
BA_ "FlexKomSID" SG_ 469 ORC_Health 2442;
BA_ "FlexKomSigLaenge" SG_ 469 ORC_Health 64;
BA_ "FlexKomSigName" SG_ 469 ORC_Health "ORC_A4_Pkt";
BA_ "FlexKomSigStartPos" SG_ 469 ORC_Health 7;
BA_ "FlexKomSigStartValue" SG_ 469 ORC_Health "0000000000000000h";
BA_ "GenSigCycleTime" SG_ 469 ORC_Health 250;
BA_ "GenSigSendType" SG_ 469 ORC_Health 5;
BA_ "GenSigSNA" SG_ 469 ORC_Health "0h";
BA_ "FlexKomComment" SG_ 294 AXSStat "Accelerometer data packet";
BA_ "FlexKomIsMotorola" SG_ 294 AXSStat 1;
BA_ "FlexKomSID" SG_ 294 AXSStat 1587;
BA_ "FlexKomSigLaenge" SG_ 294 AXSStat 64;
BA_ "FlexKomSigName" SG_ 294 AXSStat "ORC_YRS_PKT";
BA_ "FlexKomSigStartPos" SG_ 294 AXSStat 7;
BA_ "FlexKomSigStartValue" SG_ 294 AXSStat "000000000FFF00FFh";
BA_ "GenSigCycleTime" SG_ 294 AXSStat 10;
BA_ "GenSigSNA" SG_ 294 AXSStat "0h";
BA_ "RID" SG_ 294 AXSStat "9962";
BA_ "FlexKomComment" SG_ 294 AYSStat "Accelerometer data packet";
BA_ "FlexKomIsMotorola" SG_ 294 AYSStat 1;
BA_ "FlexKomSID" SG_ 294 AYSStat 1587;
BA_ "FlexKomSigLaenge" SG_ 294 AYSStat 64;
BA_ "FlexKomSigName" SG_ 294 AYSStat "ORC_YRS_PKT";
BA_ "FlexKomSigStartPos" SG_ 294 AYSStat 7;
BA_ "FlexKomSigStartValue" SG_ 294 AYSStat "000000000FFF00FFh";
BA_ "GenSigCycleTime" SG_ 294 AYSStat 10;
BA_ "GenSigSNA" SG_ 294 AYSStat "0h";
BA_ "RID" SG_ 294 AYSStat "9963";
BA_ "FlexKomComment" SG_ 294 CRC_ORC_YRS_DATA "Accelerometer data packet";
BA_ "FlexKomIsMotorola" SG_ 294 CRC_ORC_YRS_DATA 1;
BA_ "FlexKomSID" SG_ 294 CRC_ORC_YRS_DATA 1587;
BA_ "FlexKomSigLaenge" SG_ 294 CRC_ORC_YRS_DATA 64;
BA_ "FlexKomSigName" SG_ 294 CRC_ORC_YRS_DATA "ORC_YRS_PKT";
BA_ "FlexKomSigStartPos" SG_ 294 CRC_ORC_YRS_DATA 7;
BA_ "FlexKomSigStartValue" SG_ 294 CRC_ORC_YRS_DATA "000000000FFF00FFh";
BA_ "GenSigCycleTime" SG_ 294 CRC_ORC_YRS_DATA 10;
BA_ "GenSigSNA" SG_ 294 CRC_ORC_YRS_DATA "FFh";
BA_ "GenSigStartValue" SG_ 294 CRC_ORC_YRS_DATA 255;
BA_ "RID" SG_ 294 CRC_ORC_YRS_DATA "9971";
BA_ "FlexKomComment" SG_ 294 InternalError "Accelerometer data packet";
BA_ "FlexKomIsMotorola" SG_ 294 InternalError 1;
BA_ "FlexKomSID" SG_ 294 InternalError 1587;
BA_ "FlexKomSigLaenge" SG_ 294 InternalError 64;
BA_ "FlexKomSigName" SG_ 294 InternalError "ORC_YRS_PKT";
BA_ "FlexKomSigStartPos" SG_ 294 InternalError 7;
BA_ "FlexKomSigStartValue" SG_ 294 InternalError "000000000FFF00FFh";
BA_ "GenSigCycleTime" SG_ 294 InternalError 10;
BA_ "GenSigSNA" SG_ 294 InternalError "0h";
BA_ "RID" SG_ 294 InternalError "9966";
BA_ "FlexKomComment" SG_ 294 LatAcceleration "Accelerometer data packet";
BA_ "FlexKomIsMotorola" SG_ 294 LatAcceleration 1;
BA_ "FlexKomSID" SG_ 294 LatAcceleration 1587;
BA_ "FlexKomSigLaenge" SG_ 294 LatAcceleration 64;
BA_ "FlexKomSigName" SG_ 294 LatAcceleration "ORC_YRS_PKT";
BA_ "FlexKomSigStartPos" SG_ 294 LatAcceleration 7;
BA_ "FlexKomSigStartValue" SG_ 294 LatAcceleration "000000000FFF00FFh";
BA_ "GenSigCycleTime" SG_ 294 LatAcceleration 10;
BA_ "GenSigSNA" SG_ 294 LatAcceleration "FFFh";
BA_ "RID" SG_ 294 LatAcceleration "9964";
BA_ "FlexKomComment" SG_ 294 LongAcceleration "Accelerometer data packet";
BA_ "FlexKomIsMotorola" SG_ 294 LongAcceleration 1;
BA_ "FlexKomSID" SG_ 294 LongAcceleration 1587;
BA_ "FlexKomSigLaenge" SG_ 294 LongAcceleration 64;
BA_ "FlexKomSigName" SG_ 294 LongAcceleration "ORC_YRS_PKT";
BA_ "FlexKomSigStartPos" SG_ 294 LongAcceleration 7;
BA_ "FlexKomSigStartValue" SG_ 294 LongAcceleration "000000000FFF00FFh";
BA_ "GenSigCycleTime" SG_ 294 LongAcceleration 10;
BA_ "GenSigSNA" SG_ 294 LongAcceleration "FFFh";
BA_ "RID" SG_ 294 LongAcceleration "9968";
BA_ "FlexKomComment" SG_ 294 MC_ORC_YRS_DATA "Accelerometer data packet";
BA_ "FlexKomIsMotorola" SG_ 294 MC_ORC_YRS_DATA 1;
BA_ "FlexKomSID" SG_ 294 MC_ORC_YRS_DATA 1587;
BA_ "FlexKomSigLaenge" SG_ 294 MC_ORC_YRS_DATA 64;
BA_ "FlexKomSigName" SG_ 294 MC_ORC_YRS_DATA "ORC_YRS_PKT";
BA_ "FlexKomSigStartPos" SG_ 294 MC_ORC_YRS_DATA 7;
BA_ "FlexKomSigStartValue" SG_ 294 MC_ORC_YRS_DATA "000000000FFF00FFh";
BA_ "GenSigCycleTime" SG_ 294 MC_ORC_YRS_DATA 10;
BA_ "GenSigSNA" SG_ 294 MC_ORC_YRS_DATA "0h";
BA_ "RID" SG_ 294 MC_ORC_YRS_DATA "9970";
BA_ "FlexKomComment" SG_ 294 VoltageError "Accelerometer data packet";
BA_ "FlexKomIsMotorola" SG_ 294 VoltageError 1;
BA_ "FlexKomSID" SG_ 294 VoltageError 1587;
BA_ "FlexKomSigLaenge" SG_ 294 VoltageError 64;
BA_ "FlexKomSigName" SG_ 294 VoltageError "ORC_YRS_PKT";
BA_ "FlexKomSigStartPos" SG_ 294 VoltageError 7;
BA_ "FlexKomSigStartValue" SG_ 294 VoltageError "000000000FFF00FFh";
BA_ "GenSigCycleTime" SG_ 294 VoltageError 10;
BA_ "GenSigSNA" SG_ 294 VoltageError "0h";
BA_ "RID" SG_ 294 VoltageError "9967";
BA_ "FlexKomComment" SG_ 294 YRSStat "Accelerometer data packet";
BA_ "FlexKomIsMotorola" SG_ 294 YRSStat 1;
BA_ "FlexKomSID" SG_ 294 YRSStat 1587;
BA_ "FlexKomSigLaenge" SG_ 294 YRSStat 64;
BA_ "FlexKomSigName" SG_ 294 YRSStat "ORC_YRS_PKT";
BA_ "FlexKomSigStartPos" SG_ 294 YRSStat 7;
BA_ "FlexKomSigStartValue" SG_ 294 YRSStat "000000000FFF00FFh";
BA_ "GenSigCycleTime" SG_ 294 YRSStat 10;
BA_ "GenSigSNA" SG_ 294 YRSStat "0h";
BA_ "RID" SG_ 294 YRSStat "9965";
BA_ "FlexKomComment" SG_ 294 YawRate "Accelerometer data packet";
BA_ "FlexKomIsMotorola" SG_ 294 YawRate 1;
BA_ "FlexKomSID" SG_ 294 YawRate 1587;
BA_ "FlexKomSigLaenge" SG_ 294 YawRate 64;
BA_ "FlexKomSigName" SG_ 294 YawRate "ORC_YRS_PKT";
BA_ "FlexKomSigStartPos" SG_ 294 YawRate 7;
BA_ "FlexKomSigStartValue" SG_ 294 YawRate "000000000FFF00FFh";
BA_ "GenSigCycleTime" SG_ 294 YawRate 10;
BA_ "GenSigSNA" SG_ 294 YawRate "FFFh";
BA_ "GenSigStartValue" SG_ 294 YawRate 4095;
BA_ "RID" SG_ 294 YawRate "9969";
BA_ "FlexKomComment" SG_ 542 BlockOffset "Traceability - part number information packet";
BA_ "FlexKomIsMotorola" SG_ 542 BlockOffset 1;
BA_ "FlexKomSID" SG_ 542 BlockOffset 1588;
BA_ "FlexKomSigLaenge" SG_ 542 BlockOffset 64;
BA_ "FlexKomSigName" SG_ 542 BlockOffset "ORC_YRS_INFO";
BA_ "FlexKomSigStartPos" SG_ 542 BlockOffset 7;
BA_ "FlexKomSigStartValue" SG_ 542 BlockOffset "0000000000000000h";
BA_ "GenSigCycleTime" SG_ 542 BlockOffset 100;
BA_ "GenSigSendType" SG_ 542 BlockOffset 9;
BA_ "GenSigSNA" SG_ 542 BlockOffset "0h";
BA_ "FlexKomComment" SG_ 542 CLUType "Traceability - part number information packet";
BA_ "FlexKomIsMotorola" SG_ 542 CLUType 1;
BA_ "FlexKomSID" SG_ 542 CLUType 1588;
BA_ "FlexKomSigLaenge" SG_ 542 CLUType 64;
BA_ "FlexKomSigName" SG_ 542 CLUType "ORC_YRS_INFO";
BA_ "FlexKomSigStartPos" SG_ 542 CLUType 7;
BA_ "FlexKomSigStartValue" SG_ 542 CLUType "0000000000000000h";
BA_ "GenSigCycleTime" SG_ 542 CLUType 100;
BA_ "GenSigSendType" SG_ 542 CLUType 9;
BA_ "GenSigSNA" SG_ 542 CLUType "0h";
BA_ "FlexKomComment" SG_ 542 Character0 "Traceability - part number information packet";
BA_ "FlexKomIsMotorola" SG_ 542 Character0 1;
BA_ "FlexKomSID" SG_ 542 Character0 1588;
BA_ "FlexKomSigLaenge" SG_ 542 Character0 64;
BA_ "FlexKomSigName" SG_ 542 Character0 "ORC_YRS_INFO";
BA_ "FlexKomSigStartPos" SG_ 542 Character0 7;
BA_ "FlexKomSigStartValue" SG_ 542 Character0 "0000000000000000h";
BA_ "GenSigCycleTime" SG_ 542 Character0 100;
BA_ "GenSigSendType" SG_ 542 Character0 9;
BA_ "GenSigSNA" SG_ 542 Character0 "0h";
BA_ "FlexKomComment" SG_ 542 Character1 "Traceability - part number information packet";
BA_ "FlexKomIsMotorola" SG_ 542 Character1 1;
BA_ "FlexKomSID" SG_ 542 Character1 1588;
BA_ "FlexKomSigLaenge" SG_ 542 Character1 64;
BA_ "FlexKomSigName" SG_ 542 Character1 "ORC_YRS_INFO";
BA_ "FlexKomSigStartPos" SG_ 542 Character1 7;
BA_ "FlexKomSigStartValue" SG_ 542 Character1 "0000000000000000h";
BA_ "GenSigCycleTime" SG_ 542 Character1 100;
BA_ "GenSigSendType" SG_ 542 Character1 9;
BA_ "GenSigSNA" SG_ 542 Character1 "0h";
BA_ "FlexKomComment" SG_ 542 Character2 "Traceability - part number information packet";
BA_ "FlexKomIsMotorola" SG_ 542 Character2 1;
BA_ "FlexKomSID" SG_ 542 Character2 1588;
BA_ "FlexKomSigLaenge" SG_ 542 Character2 64;
BA_ "FlexKomSigName" SG_ 542 Character2 "ORC_YRS_INFO";
BA_ "FlexKomSigStartPos" SG_ 542 Character2 7;
BA_ "FlexKomSigStartValue" SG_ 542 Character2 "0000000000000000h";
BA_ "GenSigCycleTime" SG_ 542 Character2 100;
BA_ "GenSigSendType" SG_ 542 Character2 9;
BA_ "GenSigSNA" SG_ 542 Character2 "0h";
BA_ "FlexKomComment" SG_ 542 Character3 "Traceability - part number information packet";
BA_ "FlexKomIsMotorola" SG_ 542 Character3 1;
BA_ "FlexKomSID" SG_ 542 Character3 1588;
BA_ "FlexKomSigLaenge" SG_ 542 Character3 64;
BA_ "FlexKomSigName" SG_ 542 Character3 "ORC_YRS_INFO";
BA_ "FlexKomSigStartPos" SG_ 542 Character3 7;
BA_ "FlexKomSigStartValue" SG_ 542 Character3 "0000000000000000h";
BA_ "GenSigCycleTime" SG_ 542 Character3 100;
BA_ "GenSigSendType" SG_ 542 Character3 9;
BA_ "GenSigSNA" SG_ 542 Character3 "0h";
BA_ "FlexKomComment" SG_ 542 Character4 "Traceability - part number information packet";
BA_ "FlexKomIsMotorola" SG_ 542 Character4 1;
BA_ "FlexKomSID" SG_ 542 Character4 1588;
BA_ "FlexKomSigLaenge" SG_ 542 Character4 64;
BA_ "FlexKomSigName" SG_ 542 Character4 "ORC_YRS_INFO";
BA_ "FlexKomSigStartPos" SG_ 542 Character4 7;
BA_ "FlexKomSigStartValue" SG_ 542 Character4 "0000000000000000h";
BA_ "GenSigCycleTime" SG_ 542 Character4 100;
BA_ "GenSigSendType" SG_ 542 Character4 9;
BA_ "GenSigSNA" SG_ 542 Character4 "0h";
BA_ "FlexKomComment" SG_ 542 Character5 "Traceability - part number information packet";
BA_ "FlexKomIsMotorola" SG_ 542 Character5 1;
BA_ "FlexKomSID" SG_ 542 Character5 1588;
BA_ "FlexKomSigLaenge" SG_ 542 Character5 64;
BA_ "FlexKomSigName" SG_ 542 Character5 "ORC_YRS_INFO";
BA_ "FlexKomSigStartPos" SG_ 542 Character5 7;
BA_ "FlexKomSigStartValue" SG_ 542 Character5 "0000000000000000h";
BA_ "GenSigCycleTime" SG_ 542 Character5 100;
BA_ "GenSigSendType" SG_ 542 Character5 9;
BA_ "GenSigSNA" SG_ 542 Character5 "0h";
BA_ "FlexKomComment" SG_ 542 PTRInfo "Traceability - part number information packet";
BA_ "FlexKomIsMotorola" SG_ 542 PTRInfo 1;
BA_ "FlexKomSID" SG_ 542 PTRInfo 1588;
BA_ "FlexKomSigLaenge" SG_ 542 PTRInfo 64;
BA_ "FlexKomSigName" SG_ 542 PTRInfo "ORC_YRS_INFO";
BA_ "FlexKomSigStartPos" SG_ 542 PTRInfo 7;
BA_ "FlexKomSigStartValue" SG_ 542 PTRInfo "0000000000000000h";
BA_ "GenSigCycleTime" SG_ 542 PTRInfo 100;
BA_ "GenSigSendType" SG_ 542 PTRInfo 9;
BA_ "GenSigSNA" SG_ 542 PTRInfo "0h";
BA_ "FlexKomComment" SG_ 764 ApplyTrq "EDR Only information packet";
BA_ "FlexKomIsMotorola" SG_ 764 ApplyTrq 1;
BA_ "FlexKomSID" SG_ 764 ApplyTrq 762;
BA_ "FlexKomSigLaenge" SG_ 764 ApplyTrq 64;
BA_ "FlexKomSigName" SG_ 764 ApplyTrq "EDR_Pkt";
BA_ "FlexKomSigStartPos" SG_ 764 ApplyTrq 7;
BA_ "FlexKomSigStartValue" SG_ 764 ApplyTrq "00FFFFFFFFFFFFFFh";
BA_ "GenSigCycleTime" SG_ 764 ApplyTrq 100;
BA_ "GenSigSNA" SG_ 764 ApplyTrq "0h";
BA_ "GenSigTimeout_ORC" SG_ 764 ApplyTrq 350;
BA_ "FlexKomComment" SG_ 764 BrkSw1Stat "EDR Only information packet";
BA_ "FlexKomIsMotorola" SG_ 764 BrkSw1Stat 1;
BA_ "FlexKomSID" SG_ 764 BrkSw1Stat 762;
BA_ "FlexKomSigLaenge" SG_ 764 BrkSw1Stat 64;
BA_ "FlexKomSigName" SG_ 764 BrkSw1Stat "EDR_Pkt";
BA_ "FlexKomSigStartPos" SG_ 764 BrkSw1Stat 7;
BA_ "FlexKomSigStartValue" SG_ 764 BrkSw1Stat "00FFFFFFFFFFFFFFh";
BA_ "GenSigCycleTime" SG_ 764 BrkSw1Stat 100;
BA_ "GenSigSNA" SG_ 764 BrkSw1Stat "0h";
BA_ "FlexKomComment" SG_ 764 CruiseEGD "EDR Only information packet";
BA_ "FlexKomIsMotorola" SG_ 764 CruiseEGD 1;
BA_ "FlexKomSID" SG_ 764 CruiseEGD 762;
BA_ "FlexKomSigLaenge" SG_ 764 CruiseEGD 64;
BA_ "FlexKomSigName" SG_ 764 CruiseEGD "EDR_Pkt";
BA_ "FlexKomSigStartPos" SG_ 764 CruiseEGD 7;
BA_ "FlexKomSigStartValue" SG_ 764 CruiseEGD "00FFFFFFFFFFFFFFh";
BA_ "GenSigCycleTime" SG_ 764 CruiseEGD 100;
BA_ "GenSigSNA" SG_ 764 CruiseEGD "0h";
BA_ "GenSigTimeout_ORC" SG_ 764 CruiseEGD 350;
BA_ "FlexKomComment" SG_ 764 ESP_TrqRqEnabl "EDR Only information packet";
BA_ "FlexKomIsMotorola" SG_ 764 ESP_TrqRqEnabl 1;
BA_ "FlexKomSID" SG_ 764 ESP_TrqRqEnabl 762;
BA_ "FlexKomSigLaenge" SG_ 764 ESP_TrqRqEnabl 64;
BA_ "FlexKomSigName" SG_ 764 ESP_TrqRqEnabl "EDR_Pkt";
BA_ "FlexKomSigStartPos" SG_ 764 ESP_TrqRqEnabl 7;
BA_ "FlexKomSigStartValue" SG_ 764 ESP_TrqRqEnabl "00FFFFFFFFFFFFFFh";
BA_ "GenSigCycleTime" SG_ 764 ESP_TrqRqEnabl 100;
BA_ "GenSigSNA" SG_ 764 ESP_TrqRqEnabl "0h";
BA_ "GenSigTimeout_ORC" SG_ 764 ESP_TrqRqEnabl 350;
BA_ "FlexKomComment" SG_ 764 ETC_LmpFlash "EDR Only information packet";
BA_ "FlexKomIsMotorola" SG_ 764 ETC_LmpFlash 1;
BA_ "FlexKomSID" SG_ 764 ETC_LmpFlash 762;
BA_ "FlexKomSigLaenge" SG_ 764 ETC_LmpFlash 64;
BA_ "FlexKomSigName" SG_ 764 ETC_LmpFlash "EDR_Pkt";
BA_ "FlexKomSigStartPos" SG_ 764 ETC_LmpFlash 7;
BA_ "FlexKomSigStartValue" SG_ 764 ETC_LmpFlash "00FFFFFFFFFFFFFFh";
BA_ "GenSigCycleTime" SG_ 764 ETC_LmpFlash 100;
BA_ "GenSigSNA" SG_ 764 ETC_LmpFlash "0h";
BA_ "GenSigTimeout_ORC" SG_ 764 ETC_LmpFlash 350;
BA_ "FlexKomComment" SG_ 764 ETC_LmpOn "EDR Only information packet";
BA_ "FlexKomIsMotorola" SG_ 764 ETC_LmpOn 1;
BA_ "FlexKomSID" SG_ 764 ETC_LmpOn 762;
BA_ "FlexKomSigLaenge" SG_ 764 ETC_LmpOn 64;
BA_ "FlexKomSigName" SG_ 764 ETC_LmpOn "EDR_Pkt";
BA_ "FlexKomSigStartPos" SG_ 764 ETC_LmpOn 7;
BA_ "FlexKomSigStartValue" SG_ 764 ETC_LmpOn "00FFFFFFFFFFFFFFh";
BA_ "GenSigCycleTime" SG_ 764 ETC_LmpOn 100;
BA_ "GenSigSNA" SG_ 764 ETC_LmpOn "0h";
BA_ "GenSigTimeout_ORC" SG_ 764 ETC_LmpOn 350;
BA_ "FlexKomComment" SG_ 764 Lv1CrsCtrlOff "EDR Only information packet";
BA_ "FlexKomIsMotorola" SG_ 764 Lv1CrsCtrlOff 1;
BA_ "FlexKomSID" SG_ 764 Lv1CrsCtrlOff 762;
BA_ "FlexKomSigLaenge" SG_ 764 Lv1CrsCtrlOff 64;
BA_ "FlexKomSigName" SG_ 764 Lv1CrsCtrlOff "EDR_Pkt";
BA_ "FlexKomSigStartPos" SG_ 764 Lv1CrsCtrlOff 7;
BA_ "FlexKomSigStartValue" SG_ 764 Lv1CrsCtrlOff "00FFFFFFFFFFFFFFh";
BA_ "GenSigCycleTime" SG_ 764 Lv1CrsCtrlOff 100;
BA_ "GenSigSNA" SG_ 764 Lv1CrsCtrlOff "0h";
BA_ "GenSigTimeout_ORC" SG_ 764 Lv1CrsCtrlOff 350;
BA_ "FlexKomComment" SG_ 764 MAP "EDR Only information packet";
BA_ "FlexKomIsMotorola" SG_ 764 MAP 1;
BA_ "FlexKomSID" SG_ 764 MAP 762;
BA_ "FlexKomSigLaenge" SG_ 764 MAP 64;
BA_ "FlexKomSigName" SG_ 764 MAP "EDR_Pkt";
BA_ "FlexKomSigStartPos" SG_ 764 MAP 7;
BA_ "FlexKomSigStartValue" SG_ 764 MAP "00FFFFFFFFFFFFFFh";
BA_ "GenSigCycleTime" SG_ 764 MAP 100;
BA_ "GenSigSNA" SG_ 764 MAP "FFh";
BA_ "GenSigStartValue" SG_ 764 MAP 255;
BA_ "GenSigTimeout_ORC" SG_ 764 MAP 350;
BA_ "FlexKomComment" SG_ 764 RawPVS1 "EDR Only information packet";
BA_ "FlexKomIsMotorola" SG_ 764 RawPVS1 1;
BA_ "FlexKomSID" SG_ 764 RawPVS1 762;
BA_ "FlexKomSigLaenge" SG_ 764 RawPVS1 64;
BA_ "FlexKomSigName" SG_ 764 RawPVS1 "EDR_Pkt";
BA_ "FlexKomSigStartPos" SG_ 764 RawPVS1 7;
BA_ "FlexKomSigStartValue" SG_ 764 RawPVS1 "00FFFFFFFFFFFFFFh";
BA_ "GenSigCycleTime" SG_ 764 RawPVS1 100;
BA_ "GenSigSNA" SG_ 764 RawPVS1 "FFh";
BA_ "GenSigStartValue" SG_ 764 RawPVS1 255;
BA_ "GenSigTimeout_ORC" SG_ 764 RawPVS1 350;
BA_ "FlexKomComment" SG_ 764 RawPVS2 "EDR Only information packet";
BA_ "FlexKomIsMotorola" SG_ 764 RawPVS2 1;
BA_ "FlexKomSID" SG_ 764 RawPVS2 762;
BA_ "FlexKomSigLaenge" SG_ 764 RawPVS2 64;
BA_ "FlexKomSigName" SG_ 764 RawPVS2 "EDR_Pkt";
BA_ "FlexKomSigStartPos" SG_ 764 RawPVS2 7;
BA_ "FlexKomSigStartValue" SG_ 764 RawPVS2 "00FFFFFFFFFFFFFFh";
BA_ "GenSigCycleTime" SG_ 764 RawPVS2 100;
BA_ "GenSigSNA" SG_ 764 RawPVS2 "FFh";
BA_ "GenSigStartValue" SG_ 764 RawPVS2 255;
BA_ "GenSigTimeout_ORC" SG_ 764 RawPVS2 350;
BA_ "FlexKomComment" SG_ 764 RawTPS1 "EDR Only information packet";
BA_ "FlexKomIsMotorola" SG_ 764 RawTPS1 1;
BA_ "FlexKomSID" SG_ 764 RawTPS1 762;
BA_ "FlexKomSigLaenge" SG_ 764 RawTPS1 64;
BA_ "FlexKomSigName" SG_ 764 RawTPS1 "EDR_Pkt";
BA_ "FlexKomSigStartPos" SG_ 764 RawTPS1 7;
BA_ "FlexKomSigStartValue" SG_ 764 RawTPS1 "00FFFFFFFFFFFFFFh";
BA_ "GenSigCycleTime" SG_ 764 RawTPS1 100;
BA_ "GenSigSNA" SG_ 764 RawTPS1 "FFh";
BA_ "GenSigStartValue" SG_ 764 RawTPS1 255;
BA_ "GenSigTimeout_ORC" SG_ 764 RawTPS1 350;
BA_ "FlexKomComment" SG_ 764 RawTPS2 "EDR Only information packet";
BA_ "FlexKomIsMotorola" SG_ 764 RawTPS2 1;
BA_ "FlexKomSID" SG_ 764 RawTPS2 762;
BA_ "FlexKomSigLaenge" SG_ 764 RawTPS2 64;
BA_ "FlexKomSigName" SG_ 764 RawTPS2 "EDR_Pkt";
BA_ "FlexKomSigStartPos" SG_ 764 RawTPS2 7;
BA_ "FlexKomSigStartValue" SG_ 764 RawTPS2 "00FFFFFFFFFFFFFFh";
BA_ "GenSigCycleTime" SG_ 764 RawTPS2 100;
BA_ "GenSigSNA" SG_ 764 RawTPS2 "FFh";
BA_ "GenSigStartValue" SG_ 764 RawTPS2 255;
BA_ "GenSigTimeout_ORC" SG_ 764 RawTPS2 350;
BA_ "FlexKomComment" SG_ 764 RelativePdl "EDR Only information packet";
BA_ "FlexKomIsMotorola" SG_ 764 RelativePdl 1;
BA_ "FlexKomSID" SG_ 764 RelativePdl 762;
BA_ "FlexKomSigLaenge" SG_ 764 RelativePdl 64;
BA_ "FlexKomSigName" SG_ 764 RelativePdl "EDR_Pkt";
BA_ "FlexKomSigStartPos" SG_ 764 RelativePdl 7;
BA_ "FlexKomSigStartValue" SG_ 764 RelativePdl "00FFFFFFFFFFFFFFh";
BA_ "GenSigCycleTime" SG_ 764 RelativePdl 100;
BA_ "GenSigSNA" SG_ 764 RelativePdl "FFh";
BA_ "GenSigStartValue" SG_ 764 RelativePdl 255;
BA_ "GenSigTimeout_ORC" SG_ 764 RelativePdl 350;
BA_ "FlexKomComment" SG_ 764 RelativeThrt "EDR Only information packet";
BA_ "FlexKomIsMotorola" SG_ 764 RelativeThrt 1;
BA_ "FlexKomSID" SG_ 764 RelativeThrt 762;
BA_ "FlexKomSigLaenge" SG_ 764 RelativeThrt 64;
BA_ "FlexKomSigName" SG_ 764 RelativeThrt "EDR_Pkt";
BA_ "FlexKomSigStartPos" SG_ 764 RelativeThrt 7;
BA_ "FlexKomSigStartValue" SG_ 764 RelativeThrt "00FFFFFFFFFFFFFFh";
BA_ "GenSigCycleTime" SG_ 764 RelativeThrt 100;
BA_ "GenSigSNA" SG_ 764 RelativeThrt "FFh";
BA_ "GenSigStartValue" SG_ 764 RelativeThrt 255;
BA_ "GenSigTimeout_ORC" SG_ 764 RelativeThrt 350;
BA_ "FlexKomComment" SG_ 766 GF_Charge "EDR2 information packet only";
BA_ "FlexKomIsMotorola" SG_ 766 GF_Charge 1;
BA_ "FlexKomSID" SG_ 766 GF_Charge 1093;
BA_ "FlexKomSigLaenge" SG_ 766 GF_Charge 64;
BA_ "FlexKomSigName" SG_ 766 GF_Charge "EDR2_Pkt";
BA_ "FlexKomSigStartPos" SG_ 766 GF_Charge 7;
BA_ "FlexKomSigStartValue" SG_ 766 GF_Charge "FFFFFFFF0000FF00h";
BA_ "GenSigCycleTime" SG_ 766 GF_Charge 100;
BA_ "GenSigSNA" SG_ 766 GF_Charge "FFFFh";
BA_ "GenSigTimeout_ORC" SG_ 766 GF_Charge 350;
BA_ "FlexKomComment" SG_ 766 RelativeThrtPct "EDR2 information packet only";
BA_ "FlexKomIsMotorola" SG_ 766 RelativeThrtPct 1;
BA_ "FlexKomSID" SG_ 766 RelativeThrtPct 1093;
BA_ "FlexKomSigLaenge" SG_ 766 RelativeThrtPct 64;
BA_ "FlexKomSigName" SG_ 766 RelativeThrtPct "EDR2_Pkt";
BA_ "FlexKomSigStartPos" SG_ 766 RelativeThrtPct 7;
BA_ "FlexKomSigStartValue" SG_ 766 RelativeThrtPct "FFFFFFFF0000FF00h";
BA_ "GenSigCycleTime" SG_ 766 RelativeThrtPct 100;
BA_ "GenSigSNA" SG_ 766 RelativeThrtPct "FFh";
BA_ "GenSigStartValue" SG_ 766 RelativeThrtPct 255;
BA_ "GenSigTimeout_ORC" SG_ 766 RelativeThrtPct 350;
BA_ "FlexKomComment" SG_ 766 VVT_ExhCam1Pos "EDR2 information packet only";
BA_ "FlexKomIsMotorola" SG_ 766 VVT_ExhCam1Pos 1;
BA_ "FlexKomSID" SG_ 766 VVT_ExhCam1Pos 1093;
BA_ "FlexKomSigLaenge" SG_ 766 VVT_ExhCam1Pos 64;
BA_ "FlexKomSigName" SG_ 766 VVT_ExhCam1Pos "EDR2_Pkt";
BA_ "FlexKomSigStartPos" SG_ 766 VVT_ExhCam1Pos 7;
BA_ "FlexKomSigStartValue" SG_ 766 VVT_ExhCam1Pos "FFFFFFFF0000FF00h";
BA_ "GenSigCycleTime" SG_ 766 VVT_ExhCam1Pos 100;
BA_ "GenSigSNA" SG_ 766 VVT_ExhCam1Pos "0h";
BA_ "GenSigStartValue" SG_ 766 VVT_ExhCam1Pos 255;
BA_ "GenSigTimeout_ORC" SG_ 766 VVT_ExhCam1Pos 350;
BA_ "FlexKomComment" SG_ 766 VVT_ExhCam2Pos "EDR2 information packet only";
BA_ "FlexKomIsMotorola" SG_ 766 VVT_ExhCam2Pos 1;
BA_ "FlexKomSID" SG_ 766 VVT_ExhCam2Pos 1093;
BA_ "FlexKomSigLaenge" SG_ 766 VVT_ExhCam2Pos 64;
BA_ "FlexKomSigName" SG_ 766 VVT_ExhCam2Pos "EDR2_Pkt";
BA_ "FlexKomSigStartPos" SG_ 766 VVT_ExhCam2Pos 7;
BA_ "FlexKomSigStartValue" SG_ 766 VVT_ExhCam2Pos "FFFFFFFF0000FF00h";
BA_ "GenSigCycleTime" SG_ 766 VVT_ExhCam2Pos 100;
BA_ "GenSigSNA" SG_ 766 VVT_ExhCam2Pos "0h";
BA_ "GenSigStartValue" SG_ 766 VVT_ExhCam2Pos 255;
BA_ "GenSigTimeout_ORC" SG_ 766 VVT_ExhCam2Pos 350;
BA_ "FlexKomComment" SG_ 766 VVT_IntCam1Pos "EDR2 information packet only";
BA_ "FlexKomIsMotorola" SG_ 766 VVT_IntCam1Pos 1;
BA_ "FlexKomSID" SG_ 766 VVT_IntCam1Pos 1093;
BA_ "FlexKomSigLaenge" SG_ 766 VVT_IntCam1Pos 64;
BA_ "FlexKomSigName" SG_ 766 VVT_IntCam1Pos "EDR2_Pkt";
BA_ "FlexKomSigStartPos" SG_ 766 VVT_IntCam1Pos 7;
BA_ "FlexKomSigStartValue" SG_ 766 VVT_IntCam1Pos "FFFFFFFF0000FF00h";
BA_ "GenSigCycleTime" SG_ 766 VVT_IntCam1Pos 100;
BA_ "GenSigSNA" SG_ 766 VVT_IntCam1Pos "0h";
BA_ "GenSigStartValue" SG_ 766 VVT_IntCam1Pos 255;
BA_ "GenSigTimeout_ORC" SG_ 766 VVT_IntCam1Pos 350;
BA_ "FlexKomComment" SG_ 766 VVT_IntCam2Pos "EDR2 information packet only";
BA_ "FlexKomIsMotorola" SG_ 766 VVT_IntCam2Pos 1;
BA_ "FlexKomSID" SG_ 766 VVT_IntCam2Pos 1093;
BA_ "FlexKomSigLaenge" SG_ 766 VVT_IntCam2Pos 64;
BA_ "FlexKomSigName" SG_ 766 VVT_IntCam2Pos "EDR2_Pkt";
BA_ "FlexKomSigStartPos" SG_ 766 VVT_IntCam2Pos 7;
BA_ "FlexKomSigStartValue" SG_ 766 VVT_IntCam2Pos "FFFFFFFF0000FF00h";
BA_ "GenSigCycleTime" SG_ 766 VVT_IntCam2Pos 100;
BA_ "GenSigSNA" SG_ 766 VVT_IntCam2Pos "0h";
BA_ "GenSigStartValue" SG_ 766 VVT_IntCam2Pos 255;
BA_ "GenSigTimeout_ORC" SG_ 766 VVT_IntCam2Pos 350;
BA_ "FlexKomComment" SG_ 859 IBS2_Current_Status "IBS2 Battery Information";
BA_ "FlexKomIsMotorola" SG_ 859 IBS2_Current_Status 1;
BA_ "FlexKomSID" SG_ 859 IBS2_Current_Status 9211;
BA_ "FlexKomSigLaenge" SG_ 859 IBS2_Current_Status 64;
BA_ "FlexKomSigName" SG_ 859 IBS2_Current_Status "PN14_IBS2_DATA";
BA_ "FlexKomSigStartPos" SG_ 859 IBS2_Current_Status 7;
BA_ "FlexKomSigStartValue" SG_ 859 IBS2_Current_Status "3FFFFFFFFF03FFC0h";
BA_ "GenSigCycleTime" SG_ 859 IBS2_Current_Status 100;
BA_ "GenSigSNA" SG_ 859 IBS2_Current_Status "0h";
BA_ "RID" SG_ 859 IBS2_Current_Status "9936";
BA_ "FlexKomComment" SG_ 859 IBS2_I_BATT "IBS2 Battery Information";
BA_ "FlexKomIsMotorola" SG_ 859 IBS2_I_BATT 1;
BA_ "FlexKomSID" SG_ 859 IBS2_I_BATT 9211;
BA_ "FlexKomSigLaenge" SG_ 859 IBS2_I_BATT 64;
BA_ "FlexKomSigName" SG_ 859 IBS2_I_BATT "PN14_IBS2_DATA";
BA_ "FlexKomSigStartPos" SG_ 859 IBS2_I_BATT 7;
BA_ "FlexKomSigStartValue" SG_ 859 IBS2_I_BATT "3FFFFFFFFF03FFC0h";
BA_ "GenSigCycleTime" SG_ 859 IBS2_I_BATT 100;
BA_ "GenSigSNA" SG_ 859 IBS2_I_BATT "FFFFh";
BA_ "GenSigStartValue" SG_ 859 IBS2_I_BATT 65535;
BA_ "RID" SG_ 859 IBS2_I_BATT "9933";
BA_ "FlexKomComment" SG_ 859 IBS2_I_RANGE "IBS2 Battery Information";
BA_ "FlexKomIsMotorola" SG_ 859 IBS2_I_RANGE 1;
BA_ "FlexKomSID" SG_ 859 IBS2_I_RANGE 9211;
BA_ "FlexKomSigLaenge" SG_ 859 IBS2_I_RANGE 64;
BA_ "FlexKomSigName" SG_ 859 IBS2_I_RANGE "PN14_IBS2_DATA";
BA_ "FlexKomSigStartPos" SG_ 859 IBS2_I_RANGE 7;
BA_ "FlexKomSigStartValue" SG_ 859 IBS2_I_RANGE "3FFFFFFFFF03FFC0h";
BA_ "GenSigCycleTime" SG_ 859 IBS2_I_RANGE 100;
BA_ "GenSigSNA" SG_ 859 IBS2_I_RANGE "3h";
BA_ "GenSigStartValue" SG_ 859 IBS2_I_RANGE 3;
BA_ "RID" SG_ 859 IBS2_I_RANGE "9938";
BA_ "FlexKomComment" SG_ 859 IBS2_PreWakeupVoltage "IBS2 Battery Information";
BA_ "FlexKomIsMotorola" SG_ 859 IBS2_PreWakeupVoltage 1;
BA_ "FlexKomSID" SG_ 859 IBS2_PreWakeupVoltage 9211;
BA_ "FlexKomSigLaenge" SG_ 859 IBS2_PreWakeupVoltage 64;
BA_ "FlexKomSigName" SG_ 859 IBS2_PreWakeupVoltage "PN14_IBS2_DATA";
BA_ "FlexKomSigStartPos" SG_ 859 IBS2_PreWakeupVoltage 7;
BA_ "FlexKomSigStartValue" SG_ 859 IBS2_PreWakeupVoltage "3FFFFFFFFF03FFC0h";
BA_ "GenSigCycleTime" SG_ 859 IBS2_PreWakeupVoltage 100;
BA_ "GenSigSNA" SG_ 859 IBS2_PreWakeupVoltage "3FFh";
BA_ "GenSigStartValue" SG_ 859 IBS2_PreWakeupVoltage 1023;
BA_ "RID" SG_ 859 IBS2_PreWakeupVoltage "9956";
BA_ "FlexKomComment" SG_ 859 IBS2_T_BATT "IBS2 Battery Information";
BA_ "FlexKomIsMotorola" SG_ 859 IBS2_T_BATT 1;
BA_ "FlexKomSID" SG_ 859 IBS2_T_BATT 9211;
BA_ "FlexKomSigLaenge" SG_ 859 IBS2_T_BATT 64;
BA_ "FlexKomSigName" SG_ 859 IBS2_T_BATT "PN14_IBS2_DATA";
BA_ "FlexKomSigStartPos" SG_ 859 IBS2_T_BATT 7;
BA_ "FlexKomSigStartValue" SG_ 859 IBS2_T_BATT "3FFFFFFFFF03FFC0h";
BA_ "GenSigCycleTime" SG_ 859 IBS2_T_BATT 100;
BA_ "GenSigSNA" SG_ 859 IBS2_T_BATT "FFh";
BA_ "GenSigStartValue" SG_ 859 IBS2_T_BATT 255;
BA_ "RID" SG_ 859 IBS2_T_BATT "9934";
BA_ "FlexKomComment" SG_ 859 IBS2_Temp_Status "IBS2 Battery Information";
BA_ "FlexKomIsMotorola" SG_ 859 IBS2_Temp_Status 1;
BA_ "FlexKomSID" SG_ 859 IBS2_Temp_Status 9211;
BA_ "FlexKomSigLaenge" SG_ 859 IBS2_Temp_Status 64;
BA_ "FlexKomSigName" SG_ 859 IBS2_Temp_Status "PN14_IBS2_DATA";
BA_ "FlexKomSigStartPos" SG_ 859 IBS2_Temp_Status 7;
BA_ "FlexKomSigStartValue" SG_ 859 IBS2_Temp_Status "3FFFFFFFFF03FFC0h";
BA_ "GenSigCycleTime" SG_ 859 IBS2_Temp_Status 100;
BA_ "GenSigSNA" SG_ 859 IBS2_Temp_Status "0h";
BA_ "RID" SG_ 859 IBS2_Temp_Status "9940";
BA_ "FlexKomComment" SG_ 859 IBS2_V_BATT "IBS2 Battery Information";
BA_ "FlexKomIsMotorola" SG_ 859 IBS2_V_BATT 1;
BA_ "FlexKomSID" SG_ 859 IBS2_V_BATT 9211;
BA_ "FlexKomSigLaenge" SG_ 859 IBS2_V_BATT 64;
BA_ "FlexKomSigName" SG_ 859 IBS2_V_BATT "PN14_IBS2_DATA";
BA_ "FlexKomSigStartPos" SG_ 859 IBS2_V_BATT 7;
BA_ "FlexKomSigStartValue" SG_ 859 IBS2_V_BATT "3FFFFFFFFF03FFC0h";
BA_ "GenSigCycleTime" SG_ 859 IBS2_V_BATT 100;
BA_ "GenSigSNA" SG_ 859 IBS2_V_BATT "3FFFh";
BA_ "GenSigStartValue" SG_ 859 IBS2_V_BATT 16383;
BA_ "RID" SG_ 859 IBS2_V_BATT "9932";
BA_ "FlexKomComment" SG_ 859 IBS2_Voltage_Status "IBS2 Battery Information";
BA_ "FlexKomIsMotorola" SG_ 859 IBS2_Voltage_Status 1;
BA_ "FlexKomSID" SG_ 859 IBS2_Voltage_Status 9211;
BA_ "FlexKomSigLaenge" SG_ 859 IBS2_Voltage_Status 64;
BA_ "FlexKomSigName" SG_ 859 IBS2_Voltage_Status "PN14_IBS2_DATA";
BA_ "FlexKomSigStartPos" SG_ 859 IBS2_Voltage_Status 7;
BA_ "FlexKomSigStartValue" SG_ 859 IBS2_Voltage_Status "3FFFFFFFFF03FFC0h";
BA_ "GenSigCycleTime" SG_ 859 IBS2_Voltage_Status 100;
BA_ "GenSigSNA" SG_ 859 IBS2_Voltage_Status "0h";
BA_ "RID" SG_ 859 IBS2_Voltage_Status "9939";
BA_ "FlexKomComment" SG_ 532 IBS_Current_Status "IBS Battery Information";
BA_ "FlexKomIsMotorola" SG_ 532 IBS_Current_Status 1;
BA_ "FlexKomSID" SG_ 532 IBS_Current_Status 1094;
BA_ "FlexKomSigLaenge" SG_ 532 IBS_Current_Status 64;
BA_ "FlexKomSigName" SG_ 532 IBS_Current_Status "PN14_IBS_DATA";
BA_ "FlexKomSigStartPos" SG_ 532 IBS_Current_Status 7;
BA_ "FlexKomSigStartValue" SG_ 532 IBS_Current_Status "3FFFFFFFFF03FFC0h";
BA_ "GenSigCycleTime" SG_ 532 IBS_Current_Status 100;
BA_ "GenSigSNA" SG_ 532 IBS_Current_Status "0h";
BA_ "RID" SG_ 532 IBS_Current_Status "762";
BA_ "FlexKomComment" SG_ 532 IBS_I_BATT "IBS Battery Information";
BA_ "FlexKomIsMotorola" SG_ 532 IBS_I_BATT 1;
BA_ "FlexKomSID" SG_ 532 IBS_I_BATT 1094;
BA_ "FlexKomSigLaenge" SG_ 532 IBS_I_BATT 64;
BA_ "FlexKomSigName" SG_ 532 IBS_I_BATT "PN14_IBS_DATA";
BA_ "FlexKomSigStartPos" SG_ 532 IBS_I_BATT 7;
BA_ "FlexKomSigStartValue" SG_ 532 IBS_I_BATT "3FFFFFFFFF03FFC0h";
BA_ "GenSigCycleTime" SG_ 532 IBS_I_BATT 100;
BA_ "GenSigSNA" SG_ 532 IBS_I_BATT "FFFFh";
BA_ "GenSigStartValue" SG_ 532 IBS_I_BATT 65535;
BA_ "RID" SG_ 532 IBS_I_BATT "773";
BA_ "FlexKomComment" SG_ 532 IBS_I_RANGE "IBS Battery Information";
BA_ "FlexKomIsMotorola" SG_ 532 IBS_I_RANGE 1;
BA_ "FlexKomSID" SG_ 532 IBS_I_RANGE 1094;
BA_ "FlexKomSigLaenge" SG_ 532 IBS_I_RANGE 64;
BA_ "FlexKomSigName" SG_ 532 IBS_I_RANGE "PN14_IBS_DATA";
BA_ "FlexKomSigStartPos" SG_ 532 IBS_I_RANGE 7;
BA_ "FlexKomSigStartValue" SG_ 532 IBS_I_RANGE "3FFFFFFFFF03FFC0h";
BA_ "GenSigCycleTime" SG_ 532 IBS_I_RANGE 100;
BA_ "GenSigSNA" SG_ 532 IBS_I_RANGE "3h";
BA_ "GenSigStartValue" SG_ 532 IBS_I_RANGE 3;
BA_ "RID" SG_ 532 IBS_I_RANGE "821";
BA_ "FlexKomComment" SG_ 532 IBS_PreWakeupVoltage "IBS Battery Information";
BA_ "FlexKomIsMotorola" SG_ 532 IBS_PreWakeupVoltage 1;
BA_ "FlexKomSID" SG_ 532 IBS_PreWakeupVoltage 1094;
BA_ "FlexKomSigLaenge" SG_ 532 IBS_PreWakeupVoltage 64;
BA_ "FlexKomSigName" SG_ 532 IBS_PreWakeupVoltage "PN14_IBS_DATA";
BA_ "FlexKomSigStartPos" SG_ 532 IBS_PreWakeupVoltage 7;
BA_ "FlexKomSigStartValue" SG_ 532 IBS_PreWakeupVoltage "3FFFFFFFFF03FFC0h";
BA_ "GenSigCycleTime" SG_ 532 IBS_PreWakeupVoltage 100;
BA_ "GenSigSNA" SG_ 532 IBS_PreWakeupVoltage "3FFh";
BA_ "GenSigStartValue" SG_ 532 IBS_PreWakeupVoltage 1023;
BA_ "RID" SG_ 532 IBS_PreWakeupVoltage "784";
BA_ "FlexKomComment" SG_ 532 IBS_T_BATT "IBS Battery Information";
BA_ "FlexKomIsMotorola" SG_ 532 IBS_T_BATT 1;
BA_ "FlexKomSID" SG_ 532 IBS_T_BATT 1094;
BA_ "FlexKomSigLaenge" SG_ 532 IBS_T_BATT 64;
BA_ "FlexKomSigName" SG_ 532 IBS_T_BATT "PN14_IBS_DATA";
BA_ "FlexKomSigStartPos" SG_ 532 IBS_T_BATT 7;
BA_ "FlexKomSigStartValue" SG_ 532 IBS_T_BATT "3FFFFFFFFF03FFC0h";
BA_ "GenSigCycleTime" SG_ 532 IBS_T_BATT 100;
BA_ "GenSigSNA" SG_ 532 IBS_T_BATT "FFh";
BA_ "GenSigStartValue" SG_ 532 IBS_T_BATT 255;
BA_ "RID" SG_ 532 IBS_T_BATT "794";
BA_ "FlexKomComment" SG_ 532 IBS_Temp_Status "IBS Battery Information";
BA_ "FlexKomIsMotorola" SG_ 532 IBS_Temp_Status 1;
BA_ "FlexKomSID" SG_ 532 IBS_Temp_Status 1094;
BA_ "FlexKomSigLaenge" SG_ 532 IBS_Temp_Status 64;
BA_ "FlexKomSigName" SG_ 532 IBS_Temp_Status "PN14_IBS_DATA";
BA_ "FlexKomSigStartPos" SG_ 532 IBS_Temp_Status 7;
BA_ "FlexKomSigStartValue" SG_ 532 IBS_Temp_Status "3FFFFFFFFF03FFC0h";
BA_ "GenSigCycleTime" SG_ 532 IBS_Temp_Status 100;
BA_ "GenSigSNA" SG_ 532 IBS_Temp_Status "0h";
BA_ "RID" SG_ 532 IBS_Temp_Status "761";
BA_ "FlexKomComment" SG_ 532 IBS_V_BATT "IBS Battery Information";
BA_ "FlexKomIsMotorola" SG_ 532 IBS_V_BATT 1;
BA_ "FlexKomSID" SG_ 532 IBS_V_BATT 1094;
BA_ "FlexKomSigLaenge" SG_ 532 IBS_V_BATT 64;
BA_ "FlexKomSigName" SG_ 532 IBS_V_BATT "PN14_IBS_DATA";
BA_ "FlexKomSigStartPos" SG_ 532 IBS_V_BATT 7;
BA_ "FlexKomSigStartValue" SG_ 532 IBS_V_BATT "3FFFFFFFFF03FFC0h";
BA_ "GenSigCycleTime" SG_ 532 IBS_V_BATT 100;
BA_ "GenSigSNA" SG_ 532 IBS_V_BATT "3FFFh";
BA_ "GenSigStartValue" SG_ 532 IBS_V_BATT 16383;
BA_ "RID" SG_ 532 IBS_V_BATT "803";
BA_ "FlexKomComment" SG_ 532 IBS_Voltage_Status "IBS Battery Information";
BA_ "FlexKomIsMotorola" SG_ 532 IBS_Voltage_Status 1;
BA_ "FlexKomSID" SG_ 532 IBS_Voltage_Status 1094;
BA_ "FlexKomSigLaenge" SG_ 532 IBS_Voltage_Status 64;
BA_ "FlexKomSigName" SG_ 532 IBS_Voltage_Status "PN14_IBS_DATA";
BA_ "FlexKomSigStartPos" SG_ 532 IBS_Voltage_Status 7;
BA_ "FlexKomSigStartValue" SG_ 532 IBS_Voltage_Status "3FFFFFFFFF03FFC0h";
BA_ "GenSigCycleTime" SG_ 532 IBS_Voltage_Status 100;
BA_ "GenSigSNA" SG_ 532 IBS_Voltage_Status "0h";
BA_ "RID" SG_ 532 IBS_Voltage_Status "776";
BA_ "FlexKomComment" SG_ 584 Batt_ST_Crit "14 V powernet limp-home cutoff state";
BA_ "FlexKomIsMotorola" SG_ 584 Batt_ST_Crit 1;
BA_ "FlexKomSID" SG_ 584 Batt_ST_Crit 1092;
BA_ "FlexKomSigLaenge" SG_ 584 Batt_ST_Crit 64;
BA_ "FlexKomSigName" SG_ 584 Batt_ST_Crit "PN14_LHC_Stat";
BA_ "FlexKomSigStartPos" SG_ 584 Batt_ST_Crit 7;
BA_ "FlexKomSigStartValue" SG_ 584 Batt_ST_Crit "0000FFFFFF03FFFFh";
BA_ "GenSigCycleTime" SG_ 584 Batt_ST_Crit 500;
BA_ "GenSigSendType" SG_ 584 Batt_ST_Crit 5;
BA_ "GenSigSNA" SG_ 584 Batt_ST_Crit "0h";
BA_ "FlexKomComment" SG_ 584 IBS_SOC "14 V powernet limp-home cutoff state";
BA_ "FlexKomIsMotorola" SG_ 584 IBS_SOC 1;
BA_ "FlexKomSID" SG_ 584 IBS_SOC 1092;
BA_ "FlexKomSigLaenge" SG_ 584 IBS_SOC 64;
BA_ "FlexKomSigName" SG_ 584 IBS_SOC "PN14_LHC_Stat";
BA_ "FlexKomSigStartPos" SG_ 584 IBS_SOC 7;
BA_ "FlexKomSigStartValue" SG_ 584 IBS_SOC "0000FFFFFF03FFFFh";
BA_ "GenSigCycleTime" SG_ 584 IBS_SOC 500;
BA_ "GenSigSendType" SG_ 584 IBS_SOC 5;
BA_ "GenSigSNA" SG_ 584 IBS_SOC "FFh";
BA_ "GenSigStartValue" SG_ 584 IBS_SOC 255;
BA_ "GenSigTimeout_ORC" SG_ 584 IBS_SOC 1750;
BA_ "RID" SG_ 584 IBS_SOC "798";
BA_ "FlexKomComment" SG_ 584 IBS_SOC_Accuracy "14 V powernet limp-home cutoff state";
BA_ "FlexKomIsMotorola" SG_ 584 IBS_SOC_Accuracy 1;
BA_ "FlexKomSID" SG_ 584 IBS_SOC_Accuracy 1092;
BA_ "FlexKomSigLaenge" SG_ 584 IBS_SOC_Accuracy 64;
BA_ "FlexKomSigName" SG_ 584 IBS_SOC_Accuracy "PN14_LHC_Stat";
BA_ "FlexKomSigStartPos" SG_ 584 IBS_SOC_Accuracy 7;
BA_ "FlexKomSigStartValue" SG_ 584 IBS_SOC_Accuracy "0000FFFFFF03FFFFh";
BA_ "GenSigCycleTime" SG_ 584 IBS_SOC_Accuracy 500;
BA_ "GenSigSendType" SG_ 584 IBS_SOC_Accuracy 5;
BA_ "GenSigSNA" SG_ 584 IBS_SOC_Accuracy "3h";
BA_ "GenSigStartValue" SG_ 584 IBS_SOC_Accuracy 3;
BA_ "RID" SG_ 584 IBS_SOC_Accuracy "783";
BA_ "FlexKomComment" SG_ 584 IBS_SOF_Q "14 V powernet limp-home cutoff state";
BA_ "FlexKomIsMotorola" SG_ 584 IBS_SOF_Q 1;
BA_ "FlexKomSID" SG_ 584 IBS_SOF_Q 1092;
BA_ "FlexKomSigLaenge" SG_ 584 IBS_SOF_Q 64;
BA_ "FlexKomSigName" SG_ 584 IBS_SOF_Q "PN14_LHC_Stat";
BA_ "FlexKomSigStartPos" SG_ 584 IBS_SOF_Q 7;
BA_ "FlexKomSigStartValue" SG_ 584 IBS_SOF_Q "0000FFFFFF03FFFFh";
BA_ "GenSigCycleTime" SG_ 584 IBS_SOF_Q 500;
BA_ "GenSigSendType" SG_ 584 IBS_SOF_Q 5;
BA_ "GenSigSNA" SG_ 584 IBS_SOF_Q "FFh";
BA_ "GenSigStartValue" SG_ 584 IBS_SOF_Q 255;
BA_ "RID" SG_ 584 IBS_SOF_Q "791";
BA_ "FlexKomComment" SG_ 584 IBS_SOF_Q_Accuracy "14 V powernet limp-home cutoff state";
BA_ "FlexKomIsMotorola" SG_ 584 IBS_SOF_Q_Accuracy 1;
BA_ "FlexKomSID" SG_ 584 IBS_SOF_Q_Accuracy 1092;
BA_ "FlexKomSigLaenge" SG_ 584 IBS_SOF_Q_Accuracy 64;
BA_ "FlexKomSigName" SG_ 584 IBS_SOF_Q_Accuracy "PN14_LHC_Stat";
BA_ "FlexKomSigStartPos" SG_ 584 IBS_SOF_Q_Accuracy 7;
BA_ "FlexKomSigStartValue" SG_ 584 IBS_SOF_Q_Accuracy "0000FFFFFF03FFFFh";
BA_ "GenSigCycleTime" SG_ 584 IBS_SOF_Q_Accuracy 500;
BA_ "GenSigSendType" SG_ 584 IBS_SOF_Q_Accuracy 5;
BA_ "GenSigSNA" SG_ 584 IBS_SOF_Q_Accuracy "3h";
BA_ "GenSigStartValue" SG_ 584 IBS_SOF_Q_Accuracy 3;
BA_ "RID" SG_ 584 IBS_SOF_Q_Accuracy "819";
BA_ "FlexKomComment" SG_ 584 IBS_SOF_t "14 V powernet limp-home cutoff state";
BA_ "FlexKomIsMotorola" SG_ 584 IBS_SOF_t 1;
BA_ "FlexKomSID" SG_ 584 IBS_SOF_t 1092;
BA_ "FlexKomSigLaenge" SG_ 584 IBS_SOF_t 64;
BA_ "FlexKomSigName" SG_ 584 IBS_SOF_t "PN14_LHC_Stat";
BA_ "FlexKomSigStartPos" SG_ 584 IBS_SOF_t 7;
BA_ "FlexKomSigStartValue" SG_ 584 IBS_SOF_t "0000FFFFFF03FFFFh";
BA_ "GenSigCycleTime" SG_ 584 IBS_SOF_t 500;
BA_ "GenSigSendType" SG_ 584 IBS_SOF_t 5;
BA_ "GenSigSNA" SG_ 584 IBS_SOF_t "3FFh";
BA_ "GenSigStartValue" SG_ 584 IBS_SOF_t 1023;
BA_ "RID" SG_ 584 IBS_SOF_t "806";
BA_ "FlexKomComment" SG_ 584 IBS_SOF_t_Accuracy "14 V powernet limp-home cutoff state";
BA_ "FlexKomIsMotorola" SG_ 584 IBS_SOF_t_Accuracy 1;
BA_ "FlexKomSID" SG_ 584 IBS_SOF_t_Accuracy 1092;
BA_ "FlexKomSigLaenge" SG_ 584 IBS_SOF_t_Accuracy 64;
BA_ "FlexKomSigName" SG_ 584 IBS_SOF_t_Accuracy "PN14_LHC_Stat";
BA_ "FlexKomSigStartPos" SG_ 584 IBS_SOF_t_Accuracy 7;
BA_ "FlexKomSigStartValue" SG_ 584 IBS_SOF_t_Accuracy "0000FFFFFF03FFFFh";
BA_ "GenSigCycleTime" SG_ 584 IBS_SOF_t_Accuracy 500;
BA_ "GenSigSendType" SG_ 584 IBS_SOF_t_Accuracy 5;
BA_ "GenSigSNA" SG_ 584 IBS_SOF_t_Accuracy "3h";
BA_ "GenSigStartValue" SG_ 584 IBS_SOF_t_Accuracy 3;
BA_ "RID" SG_ 584 IBS_SOF_t_Accuracy "764";
BA_ "FlexKomComment" SG_ 584 IBS_SOH_Q "14 V powernet limp-home cutoff state";
BA_ "FlexKomIsMotorola" SG_ 584 IBS_SOH_Q 1;
BA_ "FlexKomSID" SG_ 584 IBS_SOH_Q 1092;
BA_ "FlexKomSigLaenge" SG_ 584 IBS_SOH_Q 64;
BA_ "FlexKomSigName" SG_ 584 IBS_SOH_Q "PN14_LHC_Stat";
BA_ "FlexKomSigStartPos" SG_ 584 IBS_SOH_Q 7;
BA_ "FlexKomSigStartValue" SG_ 584 IBS_SOH_Q "0000FFFFFF03FFFFh";
BA_ "GenSigCycleTime" SG_ 584 IBS_SOH_Q 500;
BA_ "GenSigSendType" SG_ 584 IBS_SOH_Q 5;
BA_ "GenSigSNA" SG_ 584 IBS_SOH_Q "FFh";
BA_ "GenSigStartValue" SG_ 584 IBS_SOH_Q 255;
BA_ "RID" SG_ 584 IBS_SOH_Q "770";
BA_ "FlexKomComment" SG_ 584 IBS_SOH_Q_Accuracy "14 V powernet limp-home cutoff state";
BA_ "FlexKomIsMotorola" SG_ 584 IBS_SOH_Q_Accuracy 1;
BA_ "FlexKomSID" SG_ 584 IBS_SOH_Q_Accuracy 1092;
BA_ "FlexKomSigLaenge" SG_ 584 IBS_SOH_Q_Accuracy 64;
BA_ "FlexKomSigName" SG_ 584 IBS_SOH_Q_Accuracy "PN14_LHC_Stat";
BA_ "FlexKomSigStartPos" SG_ 584 IBS_SOH_Q_Accuracy 7;
BA_ "FlexKomSigStartValue" SG_ 584 IBS_SOH_Q_Accuracy "0000FFFFFF03FFFFh";
BA_ "GenSigCycleTime" SG_ 584 IBS_SOH_Q_Accuracy 500;
BA_ "GenSigSendType" SG_ 584 IBS_SOH_Q_Accuracy 5;
BA_ "GenSigSNA" SG_ 584 IBS_SOH_Q_Accuracy "3h";
BA_ "GenSigStartValue" SG_ 584 IBS_SOH_Q_Accuracy 3;
BA_ "RID" SG_ 584 IBS_SOH_Q_Accuracy "780";
BA_ "FlexKomComment" SG_ 584 PN14_LS_Actv "14 V powernet limp-home cutoff state";
BA_ "FlexKomIsMotorola" SG_ 584 PN14_LS_Actv 1;
BA_ "FlexKomSID" SG_ 584 PN14_LS_Actv 1092;
BA_ "FlexKomSigLaenge" SG_ 584 PN14_LS_Actv 64;
BA_ "FlexKomSigName" SG_ 584 PN14_LS_Actv "PN14_LHC_Stat";
BA_ "FlexKomSigStartPos" SG_ 584 PN14_LS_Actv 7;
BA_ "FlexKomSigStartValue" SG_ 584 PN14_LS_Actv "0000FFFFFF03FFFFh";
BA_ "GenSigCycleTime" SG_ 584 PN14_LS_Actv 500;
BA_ "GenSigSendType" SG_ 584 PN14_LS_Actv 5;
BA_ "GenSigSNA" SG_ 584 PN14_LS_Actv "0h";
BA_ "GenSigTimeout_IC" SG_ 584 PN14_LS_Actv 5250;
BA_ "FlexKomComment" SG_ 900 IBS2_SOC "14 V powernet limp-home cutoff state";
BA_ "FlexKomIsMotorola" SG_ 900 IBS2_SOC 1;
BA_ "FlexKomSID" SG_ 900 IBS2_SOC 9212;
BA_ "FlexKomSigLaenge" SG_ 900 IBS2_SOC 64;
BA_ "FlexKomSigName" SG_ 900 IBS2_SOC "PN14_LHC_Stat_IBS2";
BA_ "FlexKomSigStartPos" SG_ 900 IBS2_SOC 7;
BA_ "FlexKomSigStartValue" SG_ 900 IBS2_SOC "0000FFFFFF03FFFFh";
BA_ "GenSigCycleTime" SG_ 900 IBS2_SOC 500;
BA_ "GenSigSendType" SG_ 900 IBS2_SOC 5;
BA_ "GenSigSNA" SG_ 900 IBS2_SOC "FFh";
BA_ "GenSigStartValue" SG_ 900 IBS2_SOC 255;
BA_ "RID" SG_ 900 IBS2_SOC "9943";
BA_ "FlexKomComment" SG_ 900 IBS2_SOC_Accuracy "14 V powernet limp-home cutoff state";
BA_ "FlexKomIsMotorola" SG_ 900 IBS2_SOC_Accuracy 1;
BA_ "FlexKomSID" SG_ 900 IBS2_SOC_Accuracy 9212;
BA_ "FlexKomSigLaenge" SG_ 900 IBS2_SOC_Accuracy 64;
BA_ "FlexKomSigName" SG_ 900 IBS2_SOC_Accuracy "PN14_LHC_Stat_IBS2";
BA_ "FlexKomSigStartPos" SG_ 900 IBS2_SOC_Accuracy 7;
BA_ "FlexKomSigStartValue" SG_ 900 IBS2_SOC_Accuracy "0000FFFFFF03FFFFh";
BA_ "GenSigCycleTime" SG_ 900 IBS2_SOC_Accuracy 500;
BA_ "GenSigSendType" SG_ 900 IBS2_SOC_Accuracy 5;
BA_ "GenSigSNA" SG_ 900 IBS2_SOC_Accuracy "3h";
BA_ "GenSigStartValue" SG_ 900 IBS2_SOC_Accuracy 3;
BA_ "RID" SG_ 900 IBS2_SOC_Accuracy "9950";
BA_ "FlexKomComment" SG_ 900 IBS2_SOF_Q "14 V powernet limp-home cutoff state";
BA_ "FlexKomIsMotorola" SG_ 900 IBS2_SOF_Q 1;
BA_ "FlexKomSID" SG_ 900 IBS2_SOF_Q 9212;
BA_ "FlexKomSigLaenge" SG_ 900 IBS2_SOF_Q 64;
BA_ "FlexKomSigName" SG_ 900 IBS2_SOF_Q "PN14_LHC_Stat_IBS2";
BA_ "FlexKomSigStartPos" SG_ 900 IBS2_SOF_Q 7;
BA_ "FlexKomSigStartValue" SG_ 900 IBS2_SOF_Q "0000FFFFFF03FFFFh";
BA_ "GenSigCycleTime" SG_ 900 IBS2_SOF_Q 500;
BA_ "GenSigSendType" SG_ 900 IBS2_SOF_Q 5;
BA_ "GenSigSNA" SG_ 900 IBS2_SOF_Q "FFh";
BA_ "GenSigStartValue" SG_ 900 IBS2_SOF_Q 255;
BA_ "RID" SG_ 900 IBS2_SOF_Q "9944";
BA_ "FlexKomComment" SG_ 900 IBS2_SOF_Q_Accuracy "14 V powernet limp-home cutoff state";
BA_ "FlexKomIsMotorola" SG_ 900 IBS2_SOF_Q_Accuracy 1;
BA_ "FlexKomSID" SG_ 900 IBS2_SOF_Q_Accuracy 9212;
BA_ "FlexKomSigLaenge" SG_ 900 IBS2_SOF_Q_Accuracy 64;
BA_ "FlexKomSigName" SG_ 900 IBS2_SOF_Q_Accuracy "PN14_LHC_Stat_IBS2";
BA_ "FlexKomSigStartPos" SG_ 900 IBS2_SOF_Q_Accuracy 7;
BA_ "FlexKomSigStartValue" SG_ 900 IBS2_SOF_Q_Accuracy "0000FFFFFF03FFFFh";
BA_ "GenSigCycleTime" SG_ 900 IBS2_SOF_Q_Accuracy 500;
BA_ "GenSigSendType" SG_ 900 IBS2_SOF_Q_Accuracy 5;
BA_ "GenSigSNA" SG_ 900 IBS2_SOF_Q_Accuracy "3h";
BA_ "GenSigStartValue" SG_ 900 IBS2_SOF_Q_Accuracy 3;
BA_ "RID" SG_ 900 IBS2_SOF_Q_Accuracy "9951";
BA_ "FlexKomComment" SG_ 900 IBS2_SOF_t "14 V powernet limp-home cutoff state";
BA_ "FlexKomIsMotorola" SG_ 900 IBS2_SOF_t 1;
BA_ "FlexKomSID" SG_ 900 IBS2_SOF_t 9212;
BA_ "FlexKomSigLaenge" SG_ 900 IBS2_SOF_t 64;
BA_ "FlexKomSigName" SG_ 900 IBS2_SOF_t "PN14_LHC_Stat_IBS2";
BA_ "FlexKomSigStartPos" SG_ 900 IBS2_SOF_t 7;
BA_ "FlexKomSigStartValue" SG_ 900 IBS2_SOF_t "0000FFFFFF03FFFFh";
BA_ "GenSigCycleTime" SG_ 900 IBS2_SOF_t 500;
BA_ "GenSigSendType" SG_ 900 IBS2_SOF_t 5;
BA_ "GenSigSNA" SG_ 900 IBS2_SOF_t "3FFh";
BA_ "GenSigStartValue" SG_ 900 IBS2_SOF_t 1023;
BA_ "RID" SG_ 900 IBS2_SOF_t "9947";
BA_ "FlexKomComment" SG_ 900 IBS2_SOF_t_Accuracy "14 V powernet limp-home cutoff state";
BA_ "FlexKomIsMotorola" SG_ 900 IBS2_SOF_t_Accuracy 1;
BA_ "FlexKomSID" SG_ 900 IBS2_SOF_t_Accuracy 9212;
BA_ "FlexKomSigLaenge" SG_ 900 IBS2_SOF_t_Accuracy 64;
BA_ "FlexKomSigName" SG_ 900 IBS2_SOF_t_Accuracy "PN14_LHC_Stat_IBS2";
BA_ "FlexKomSigStartPos" SG_ 900 IBS2_SOF_t_Accuracy 7;
BA_ "FlexKomSigStartValue" SG_ 900 IBS2_SOF_t_Accuracy "0000FFFFFF03FFFFh";
BA_ "GenSigCycleTime" SG_ 900 IBS2_SOF_t_Accuracy 500;
BA_ "GenSigSendType" SG_ 900 IBS2_SOF_t_Accuracy 5;
BA_ "GenSigSNA" SG_ 900 IBS2_SOF_t_Accuracy "3h";
BA_ "GenSigStartValue" SG_ 900 IBS2_SOF_t_Accuracy 3;
BA_ "RID" SG_ 900 IBS2_SOF_t_Accuracy "9953";
BA_ "FlexKomComment" SG_ 900 IBS2_SOH_Q "14 V powernet limp-home cutoff state";
BA_ "FlexKomIsMotorola" SG_ 900 IBS2_SOH_Q 1;
BA_ "FlexKomSID" SG_ 900 IBS2_SOH_Q 9212;
BA_ "FlexKomSigLaenge" SG_ 900 IBS2_SOH_Q 64;
BA_ "FlexKomSigName" SG_ 900 IBS2_SOH_Q "PN14_LHC_Stat_IBS2";
BA_ "FlexKomSigStartPos" SG_ 900 IBS2_SOH_Q 7;
BA_ "FlexKomSigStartValue" SG_ 900 IBS2_SOH_Q "0000FFFFFF03FFFFh";
BA_ "GenSigCycleTime" SG_ 900 IBS2_SOH_Q 500;
BA_ "GenSigSendType" SG_ 900 IBS2_SOH_Q 5;
BA_ "GenSigSNA" SG_ 900 IBS2_SOH_Q "FFh";
BA_ "GenSigStartValue" SG_ 900 IBS2_SOH_Q 255;
BA_ "RID" SG_ 900 IBS2_SOH_Q "9946";
BA_ "FlexKomComment" SG_ 900 IBS2_SOH_Q_Accuracy "14 V powernet limp-home cutoff state";
BA_ "FlexKomIsMotorola" SG_ 900 IBS2_SOH_Q_Accuracy 1;
BA_ "FlexKomSID" SG_ 900 IBS2_SOH_Q_Accuracy 9212;
BA_ "FlexKomSigLaenge" SG_ 900 IBS2_SOH_Q_Accuracy 64;
BA_ "FlexKomSigName" SG_ 900 IBS2_SOH_Q_Accuracy "PN14_LHC_Stat_IBS2";
BA_ "FlexKomSigStartPos" SG_ 900 IBS2_SOH_Q_Accuracy 7;
BA_ "FlexKomSigStartValue" SG_ 900 IBS2_SOH_Q_Accuracy "0000FFFFFF03FFFFh";
BA_ "GenSigCycleTime" SG_ 900 IBS2_SOH_Q_Accuracy 500;
BA_ "GenSigSendType" SG_ 900 IBS2_SOH_Q_Accuracy 5;
BA_ "GenSigSNA" SG_ 900 IBS2_SOH_Q_Accuracy "3h";
BA_ "GenSigStartValue" SG_ 900 IBS2_SOH_Q_Accuracy 3;
BA_ "RID" SG_ 900 IBS2_SOH_Q_Accuracy "9948";
BA_ "FlexKomComment" SG_ 826 PTS_AlrFC "Park assist front center warnings";
BA_ "FlexKomIsMotorola" SG_ 826 PTS_AlrFC 1;
BA_ "FlexKomSID" SG_ 826 PTS_AlrFC 1121;
BA_ "FlexKomSigLaenge" SG_ 826 PTS_AlrFC 8;
BA_ "FlexKomSigName" SG_ 826 PTS_AlrFC "PTS_FC";
BA_ "FlexKomSigStartPos" SG_ 826 PTS_AlrFC 47;
BA_ "FlexKomSigStartValue" SG_ 826 PTS_AlrFC "F0h";
BA_ "GenSigCycleTime" SG_ 826 PTS_AlrFC 500;
BA_ "GenSigSendType" SG_ 826 PTS_AlrFC 5;
BA_ "GenSigSNA" SG_ 826 PTS_AlrFC "Fh";
BA_ "GenSigTimeout_CBC" SG_ 826 PTS_AlrFC 5250;
BA_ "GenSigTimeout_IC" SG_ 826 PTS_AlrFC 5250;
BA_ "RID" SG_ 826 PTS_AlrFC "2103";
BA_ "FlexKomComment" SG_ 826 PTS_AlrFL "Park assist front left warnings";
BA_ "FlexKomIsMotorola" SG_ 826 PTS_AlrFL 1;
BA_ "FlexKomSID" SG_ 826 PTS_AlrFL 1117;
BA_ "FlexKomSigLaenge" SG_ 826 PTS_AlrFL 8;
BA_ "FlexKomSigName" SG_ 826 PTS_AlrFL "PTS_FL";
BA_ "FlexKomSigStartPos" SG_ 826 PTS_AlrFL 15;
BA_ "FlexKomSigStartValue" SG_ 826 PTS_AlrFL "F0h";
BA_ "GenSigCycleTime" SG_ 826 PTS_AlrFL 500;
BA_ "GenSigSendType" SG_ 826 PTS_AlrFL 5;
BA_ "GenSigSNA" SG_ 826 PTS_AlrFL "Fh";
BA_ "GenSigTimeout_CBC" SG_ 826 PTS_AlrFL 5250;
BA_ "GenSigTimeout_IC" SG_ 826 PTS_AlrFL 5250;
BA_ "RID" SG_ 826 PTS_AlrFL "2104";
BA_ "FlexKomComment" SG_ 826 PTS_AlrFR "Park assist front right warnings";
BA_ "FlexKomIsMotorola" SG_ 826 PTS_AlrFR 1;
BA_ "FlexKomSID" SG_ 826 PTS_AlrFR 1118;
BA_ "FlexKomSigLaenge" SG_ 826 PTS_AlrFR 8;
BA_ "FlexKomSigName" SG_ 826 PTS_AlrFR "PTS_FR";
BA_ "FlexKomSigStartPos" SG_ 826 PTS_AlrFR 23;
BA_ "FlexKomSigStartValue" SG_ 826 PTS_AlrFR "F0h";
BA_ "GenSigCycleTime" SG_ 826 PTS_AlrFR 500;
BA_ "GenSigSendType" SG_ 826 PTS_AlrFR 5;
BA_ "GenSigSNA" SG_ 826 PTS_AlrFR "Fh";
BA_ "GenSigTimeout_CBC" SG_ 826 PTS_AlrFR 5250;
BA_ "GenSigTimeout_IC" SG_ 826 PTS_AlrFR 5250;
BA_ "RID" SG_ 826 PTS_AlrFR "2100";
BA_ "FlexKomComment" SG_ 826 PTS_AlrRC "Park assist rear center warnings";
BA_ "FlexKomIsMotorola" SG_ 826 PTS_AlrRC 1;
BA_ "FlexKomSID" SG_ 826 PTS_AlrRC 1123;
BA_ "FlexKomSigLaenge" SG_ 826 PTS_AlrRC 8;
BA_ "FlexKomSigName" SG_ 826 PTS_AlrRC "PTS_RC";
BA_ "FlexKomSigStartPos" SG_ 826 PTS_AlrRC 55;
BA_ "FlexKomSigStartValue" SG_ 826 PTS_AlrRC "F0h";
BA_ "GenSigCycleTime" SG_ 826 PTS_AlrRC 500;
BA_ "GenSigSendType" SG_ 826 PTS_AlrRC 5;
BA_ "GenSigSNA" SG_ 826 PTS_AlrRC "Fh";
BA_ "GenSigTimeout_CBC" SG_ 826 PTS_AlrRC 5250;
BA_ "GenSigTimeout_IC" SG_ 826 PTS_AlrRC 5250;
BA_ "RID" SG_ 826 PTS_AlrRC "1026 2098";
BA_ "FlexKomComment" SG_ 826 PTS_AlrRL "Park assist rear left warnings";
BA_ "FlexKomIsMotorola" SG_ 826 PTS_AlrRL 1;
BA_ "FlexKomSID" SG_ 826 PTS_AlrRL 1119;
BA_ "FlexKomSigLaenge" SG_ 826 PTS_AlrRL 8;
BA_ "FlexKomSigName" SG_ 826 PTS_AlrRL "PTS_RL";
BA_ "FlexKomSigStartPos" SG_ 826 PTS_AlrRL 31;
BA_ "FlexKomSigStartValue" SG_ 826 PTS_AlrRL "F0h";
BA_ "GenSigCycleTime" SG_ 826 PTS_AlrRL 500;
BA_ "GenSigSendType" SG_ 826 PTS_AlrRL 5;
BA_ "GenSigSNA" SG_ 826 PTS_AlrRL "Fh";
BA_ "GenSigTimeout_CBC" SG_ 826 PTS_AlrRL 5250;
BA_ "GenSigTimeout_IC" SG_ 826 PTS_AlrRL 5250;
BA_ "RID" SG_ 826 PTS_AlrRL "1009 2101";
BA_ "FlexKomComment" SG_ 826 PTS_AlrRR "Park assist rear right warnings";
BA_ "FlexKomIsMotorola" SG_ 826 PTS_AlrRR 1;
BA_ "FlexKomSID" SG_ 826 PTS_AlrRR 1120;
BA_ "FlexKomSigLaenge" SG_ 826 PTS_AlrRR 8;
BA_ "FlexKomSigName" SG_ 826 PTS_AlrRR "PTS_RR";
BA_ "FlexKomSigStartPos" SG_ 826 PTS_AlrRR 39;
BA_ "FlexKomSigStartValue" SG_ 826 PTS_AlrRR "F0h";
BA_ "GenSigCycleTime" SG_ 826 PTS_AlrRR 500;
BA_ "GenSigSendType" SG_ 826 PTS_AlrRR 5;
BA_ "GenSigSNA" SG_ 826 PTS_AlrRR "Fh";
BA_ "GenSigTimeout_CBC" SG_ 826 PTS_AlrRR 5250;
BA_ "GenSigTimeout_IC" SG_ 826 PTS_AlrRR 5250;
BA_ "RID" SG_ 826 PTS_AlrRR "1005 2099";
BA_ "FlexKomComment" SG_ 826 PTS_CFG_STAT "Park assist configuration status";
BA_ "FlexKomIsMotorola" SG_ 826 PTS_CFG_STAT 1;
BA_ "FlexKomSID" SG_ 826 PTS_CFG_STAT 1114;
BA_ "FlexKomSigLaenge" SG_ 826 PTS_CFG_STAT 2;
BA_ "FlexKomSigName" SG_ 826 PTS_CFG_STAT "PTS_CFG_STAT";
BA_ "FlexKomSigStartPos" SG_ 826 PTS_CFG_STAT 2;
BA_ "FlexKomSigStartValue" SG_ 826 PTS_CFG_STAT "00h";
BA_ "GenSigCycleTime" SG_ 826 PTS_CFG_STAT 500;
BA_ "GenSigSendType" SG_ 826 PTS_CFG_STAT 5;
BA_ "GenSigSNA" SG_ 826 PTS_CFG_STAT "3h";
BA_ "GenSigTimeout_CBC" SG_ 826 PTS_CFG_STAT 5250;
BA_ "GenSigTimeout_IC" SG_ 826 PTS_CFG_STAT 5250;
BA_ "RID" SG_ 826 PTS_CFG_STAT "1181";
BA_ "FlexKomComment" SG_ 826 PTS_FT_NA "Front park assist not available - blinded sensor; ";
BA_ "FlexKomIsMotorola" SG_ 826 PTS_FT_NA 1;
BA_ "FlexKomSID" SG_ 826 PTS_FT_NA 1314;
BA_ "FlexKomSigLaenge" SG_ 826 PTS_FT_NA 1;
BA_ "FlexKomSigName" SG_ 826 PTS_FT_NA "PTS_FT_NA";
BA_ "FlexKomSigStartPos" SG_ 826 PTS_FT_NA 3;
BA_ "FlexKomSigStartValue" SG_ 826 PTS_FT_NA "00h";
BA_ "GenSigCycleTime" SG_ 826 PTS_FT_NA 500;
BA_ "GenSigSendType" SG_ 826 PTS_FT_NA 5;
BA_ "GenSigSNA" SG_ 826 PTS_FT_NA "0h";
BA_ "GenSigTimeout_IC" SG_ 826 PTS_FT_NA 5250;
BA_ "FlexKomComment" SG_ 826 PTS_FT_SRV "Front PTS sensor service request; True = [1]";
BA_ "FlexKomIsMotorola" SG_ 826 PTS_FT_SRV 1;
BA_ "FlexKomSID" SG_ 826 PTS_FT_SRV 1354;
BA_ "FlexKomSigLaenge" SG_ 826 PTS_FT_SRV 1;
BA_ "FlexKomSigName" SG_ 826 PTS_FT_SRV "PTS_FT_SRV";
BA_ "FlexKomSigStartPos" SG_ 826 PTS_FT_SRV 58;
BA_ "FlexKomSigStartValue" SG_ 826 PTS_FT_SRV "00h";
BA_ "GenSigCycleTime" SG_ 826 PTS_FT_SRV 500;
BA_ "GenSigSendType" SG_ 826 PTS_FT_SRV 5;
BA_ "GenSigSNA" SG_ 826 PTS_FT_SRV "0h";
BA_ "GenSigTimeout_IC" SG_ 826 PTS_FT_SRV 5250;
BA_ "FlexKomComment" SG_ 826 PTS_GraphicFC "Park assist front center warnings";
BA_ "FlexKomIsMotorola" SG_ 826 PTS_GraphicFC 1;
BA_ "FlexKomSID" SG_ 826 PTS_GraphicFC 1121;
BA_ "FlexKomSigLaenge" SG_ 826 PTS_GraphicFC 8;
BA_ "FlexKomSigName" SG_ 826 PTS_GraphicFC "PTS_FC";
BA_ "FlexKomSigStartPos" SG_ 826 PTS_GraphicFC 47;
BA_ "FlexKomSigStartValue" SG_ 826 PTS_GraphicFC "F0h";
BA_ "GenSigCycleTime" SG_ 826 PTS_GraphicFC 500;
BA_ "GenSigSendType" SG_ 826 PTS_GraphicFC 5;
BA_ "GenSigSNA" SG_ 826 PTS_GraphicFC "3h";
BA_ "GenSigStartValue" SG_ 826 PTS_GraphicFC 3;
BA_ "GenSigTimeout_IC" SG_ 826 PTS_GraphicFC 5250;
BA_ "FlexKomComment" SG_ 826 PTS_GraphicFL "Park assist front left warnings";
BA_ "FlexKomIsMotorola" SG_ 826 PTS_GraphicFL 1;
BA_ "FlexKomSID" SG_ 826 PTS_GraphicFL 1117;
BA_ "FlexKomSigLaenge" SG_ 826 PTS_GraphicFL 8;
BA_ "FlexKomSigName" SG_ 826 PTS_GraphicFL "PTS_FL";
BA_ "FlexKomSigStartPos" SG_ 826 PTS_GraphicFL 15;
BA_ "FlexKomSigStartValue" SG_ 826 PTS_GraphicFL "F0h";
BA_ "GenSigCycleTime" SG_ 826 PTS_GraphicFL 500;
BA_ "GenSigSendType" SG_ 826 PTS_GraphicFL 5;
BA_ "GenSigSNA" SG_ 826 PTS_GraphicFL "3h";
BA_ "GenSigStartValue" SG_ 826 PTS_GraphicFL 3;
BA_ "GenSigTimeout_IC" SG_ 826 PTS_GraphicFL 5250;
BA_ "FlexKomComment" SG_ 826 PTS_GraphicFR "Park assist front right warnings";
BA_ "FlexKomIsMotorola" SG_ 826 PTS_GraphicFR 1;
BA_ "FlexKomSID" SG_ 826 PTS_GraphicFR 1118;
BA_ "FlexKomSigLaenge" SG_ 826 PTS_GraphicFR 8;
BA_ "FlexKomSigName" SG_ 826 PTS_GraphicFR "PTS_FR";
BA_ "FlexKomSigStartPos" SG_ 826 PTS_GraphicFR 23;
BA_ "FlexKomSigStartValue" SG_ 826 PTS_GraphicFR "F0h";
BA_ "GenSigCycleTime" SG_ 826 PTS_GraphicFR 500;
BA_ "GenSigSendType" SG_ 826 PTS_GraphicFR 5;
BA_ "GenSigSNA" SG_ 826 PTS_GraphicFR "3h";
BA_ "GenSigStartValue" SG_ 826 PTS_GraphicFR 3;
BA_ "GenSigTimeout_IC" SG_ 826 PTS_GraphicFR 5250;
BA_ "FlexKomComment" SG_ 826 PTS_GraphicRC "Park assist rear center warnings";
BA_ "FlexKomIsMotorola" SG_ 826 PTS_GraphicRC 1;
BA_ "FlexKomSID" SG_ 826 PTS_GraphicRC 1123;
BA_ "FlexKomSigLaenge" SG_ 826 PTS_GraphicRC 8;
BA_ "FlexKomSigName" SG_ 826 PTS_GraphicRC "PTS_RC";
BA_ "FlexKomSigStartPos" SG_ 826 PTS_GraphicRC 55;
BA_ "FlexKomSigStartValue" SG_ 826 PTS_GraphicRC "F0h";
BA_ "GenSigCycleTime" SG_ 826 PTS_GraphicRC 500;
BA_ "GenSigSendType" SG_ 826 PTS_GraphicRC 5;
BA_ "GenSigSNA" SG_ 826 PTS_GraphicRC "3h";
BA_ "GenSigStartValue" SG_ 826 PTS_GraphicRC 3;
BA_ "GenSigTimeout_IC" SG_ 826 PTS_GraphicRC 5250;
BA_ "FlexKomComment" SG_ 826 PTS_GraphicRL "Park assist rear left warnings";
BA_ "FlexKomIsMotorola" SG_ 826 PTS_GraphicRL 1;
BA_ "FlexKomSID" SG_ 826 PTS_GraphicRL 1119;
BA_ "FlexKomSigLaenge" SG_ 826 PTS_GraphicRL 8;
BA_ "FlexKomSigName" SG_ 826 PTS_GraphicRL "PTS_RL";
BA_ "FlexKomSigStartPos" SG_ 826 PTS_GraphicRL 31;
BA_ "FlexKomSigStartValue" SG_ 826 PTS_GraphicRL "F0h";
BA_ "GenSigCycleTime" SG_ 826 PTS_GraphicRL 500;
BA_ "GenSigSendType" SG_ 826 PTS_GraphicRL 5;
BA_ "GenSigSNA" SG_ 826 PTS_GraphicRL "3h";
BA_ "GenSigStartValue" SG_ 826 PTS_GraphicRL 3;
BA_ "GenSigTimeout_IC" SG_ 826 PTS_GraphicRL 5250;
BA_ "FlexKomComment" SG_ 826 PTS_GraphicRR "Park assist rear right warnings";
BA_ "FlexKomIsMotorola" SG_ 826 PTS_GraphicRR 1;
BA_ "FlexKomSID" SG_ 826 PTS_GraphicRR 1120;
BA_ "FlexKomSigLaenge" SG_ 826 PTS_GraphicRR 8;
BA_ "FlexKomSigName" SG_ 826 PTS_GraphicRR "PTS_RR";
BA_ "FlexKomSigStartPos" SG_ 826 PTS_GraphicRR 39;
BA_ "FlexKomSigStartValue" SG_ 826 PTS_GraphicRR "F0h";
BA_ "GenSigCycleTime" SG_ 826 PTS_GraphicRR 500;
BA_ "GenSigSendType" SG_ 826 PTS_GraphicRR 5;
BA_ "GenSigSNA" SG_ 826 PTS_GraphicRR "3h";
BA_ "GenSigStartValue" SG_ 826 PTS_GraphicRR 3;
BA_ "GenSigTimeout_IC" SG_ 826 PTS_GraphicRR 5250;
BA_ "FlexKomComment" SG_ 826 PTS_RR_NA "Rear park assist not available - blinded sensor; T";
BA_ "FlexKomIsMotorola" SG_ 826 PTS_RR_NA 1;
BA_ "FlexKomSID" SG_ 826 PTS_RR_NA 1315;
BA_ "FlexKomSigLaenge" SG_ 826 PTS_RR_NA 1;
BA_ "FlexKomSigName" SG_ 826 PTS_RR_NA "PTS_RR_NA";
BA_ "FlexKomSigStartPos" SG_ 826 PTS_RR_NA 4;
BA_ "FlexKomSigStartValue" SG_ 826 PTS_RR_NA "00h";
BA_ "GenSigCycleTime" SG_ 826 PTS_RR_NA 500;
BA_ "GenSigSendType" SG_ 826 PTS_RR_NA 5;
BA_ "GenSigSNA" SG_ 826 PTS_RR_NA "0h";
BA_ "GenSigTimeout_IC" SG_ 826 PTS_RR_NA 5250;
BA_ "FlexKomComment" SG_ 826 PTS_RR_SRV "Rear PTS sensor service request; True = [1]";
BA_ "FlexKomIsMotorola" SG_ 826 PTS_RR_SRV 1;
BA_ "FlexKomSID" SG_ 826 PTS_RR_SRV 1353;
BA_ "FlexKomSigLaenge" SG_ 826 PTS_RR_SRV 1;
BA_ "FlexKomSigName" SG_ 826 PTS_RR_SRV "PTS_RR_SRV";
BA_ "FlexKomSigStartPos" SG_ 826 PTS_RR_SRV 59;
BA_ "FlexKomSigStartValue" SG_ 826 PTS_RR_SRV "00h";
BA_ "GenSigCycleTime" SG_ 826 PTS_RR_SRV 500;
BA_ "GenSigSendType" SG_ 826 PTS_RR_SRV 5;
BA_ "GenSigSNA" SG_ 826 PTS_RR_SRV "0h";
BA_ "GenSigTimeout_IC" SG_ 826 PTS_RR_SRV 5250;
BA_ "FlexKomComment" SG_ 826 PTS_SRV_RQ "PTS service warning request; True = [1]";
BA_ "FlexKomIsMotorola" SG_ 826 PTS_SRV_RQ 1;
BA_ "FlexKomSID" SG_ 826 PTS_SRV_RQ 54;
BA_ "FlexKomSigLaenge" SG_ 826 PTS_SRV_RQ 1;
BA_ "FlexKomSigName" SG_ 826 PTS_SRV_RQ "PTS_SRV_RQ";
BA_ "FlexKomSigStartPos" SG_ 826 PTS_SRV_RQ 5;
BA_ "FlexKomSigStartValue" SG_ 826 PTS_SRV_RQ "00h";
BA_ "GenSigCycleTime" SG_ 826 PTS_SRV_RQ 500;
BA_ "GenSigSendType" SG_ 826 PTS_SRV_RQ 5;
BA_ "GenSigSNA" SG_ 826 PTS_SRV_RQ "0h";
BA_ "GenSigTimeout_IC" SG_ 826 PTS_SRV_RQ 5250;
BA_ "FlexKomComment" SG_ 826 PTS_STAT "Park Assist System - LED control status";
BA_ "FlexKomIsMotorola" SG_ 826 PTS_STAT 1;
BA_ "FlexKomSID" SG_ 826 PTS_STAT 1862;
BA_ "FlexKomSigLaenge" SG_ 826 PTS_STAT 2;
BA_ "FlexKomSigName" SG_ 826 PTS_STAT "PTS_STAT";
BA_ "FlexKomSigStartPos" SG_ 826 PTS_STAT 61;
BA_ "FlexKomSigStartValue" SG_ 826 PTS_STAT "00h";
BA_ "GenSigCycleTime" SG_ 826 PTS_STAT 500;
BA_ "GenSigSendType" SG_ 826 PTS_STAT 5;
BA_ "GenSigSNA" SG_ 826 PTS_STAT "3h";
BA_ "GenSigTimeout_CBC" SG_ 826 PTS_STAT 5250;
BA_ "RID" SG_ 826 PTS_STAT "1877 1939 5117";
BA_ "FlexKomComment" SG_ 608 CRC_PTS_2 "PTS 2 message packet";
BA_ "FlexKomIsMotorola" SG_ 608 CRC_PTS_2 1;
BA_ "FlexKomSID" SG_ 608 CRC_PTS_2 1954;
BA_ "FlexKomSigLaenge" SG_ 608 CRC_PTS_2 64;
BA_ "FlexKomSigName" SG_ 608 CRC_PTS_2 "PTS_2_Pkt";
BA_ "FlexKomSigStartPos" SG_ 608 CRC_PTS_2 7;
BA_ "FlexKomSigStartValue" SG_ 608 CRC_PTS_2 "FF001400000000FFh";
BA_ "GenSigCycleTime" SG_ 608 CRC_PTS_2 500;
BA_ "GenSigSendType" SG_ 608 CRC_PTS_2 5;
BA_ "GenSigSNA" SG_ 608 CRC_PTS_2 "FFh";
BA_ "GenSigStartValue" SG_ 608 CRC_PTS_2 255;
BA_ "FlexKomComment" SG_ 608 MC_PTS_2 "PTS 2 message packet";
BA_ "FlexKomIsMotorola" SG_ 608 MC_PTS_2 1;
BA_ "FlexKomSID" SG_ 608 MC_PTS_2 1954;
BA_ "FlexKomSigLaenge" SG_ 608 MC_PTS_2 64;
BA_ "FlexKomSigName" SG_ 608 MC_PTS_2 "PTS_2_Pkt";
BA_ "FlexKomSigStartPos" SG_ 608 MC_PTS_2 7;
BA_ "FlexKomSigStartValue" SG_ 608 MC_PTS_2 "FF001400000000FFh";
BA_ "GenSigCycleTime" SG_ 608 MC_PTS_2 500;
BA_ "GenSigSendType" SG_ 608 MC_PTS_2 5;
BA_ "GenSigSNA" SG_ 608 MC_PTS_2 "0h";
BA_ "FlexKomComment" SG_ 608 PTS_CFG_STAT_TeenKey "PTS 2 message packet";
BA_ "FlexKomIsMotorola" SG_ 608 PTS_CFG_STAT_TeenKey 1;
BA_ "FlexKomSID" SG_ 608 PTS_CFG_STAT_TeenKey 1954;
BA_ "FlexKomSigLaenge" SG_ 608 PTS_CFG_STAT_TeenKey 64;
BA_ "FlexKomSigName" SG_ 608 PTS_CFG_STAT_TeenKey "PTS_2_Pkt";
BA_ "FlexKomSigStartPos" SG_ 608 PTS_CFG_STAT_TeenKey 7;
BA_ "FlexKomSigStartValue" SG_ 608 PTS_CFG_STAT_TeenKey "FF001400000000FFh";
BA_ "GenSigCycleTime" SG_ 608 PTS_CFG_STAT_TeenKey 500;
BA_ "GenSigSendType" SG_ 608 PTS_CFG_STAT_TeenKey 5;
BA_ "GenSigSNA" SG_ 608 PTS_CFG_STAT_TeenKey "3h";
BA_ "GenSigTimeout_CBC" SG_ 608 PTS_CFG_STAT_TeenKey 5250;
BA_ "RID" SG_ 608 PTS_CFG_STAT_TeenKey "2168";
BA_ "FlexKomComment" SG_ 608 PTS_FT_TEMP_NA "PTS 2 message packet";
BA_ "FlexKomIsMotorola" SG_ 608 PTS_FT_TEMP_NA 1;
BA_ "FlexKomSID" SG_ 608 PTS_FT_TEMP_NA 1954;
BA_ "FlexKomSigLaenge" SG_ 608 PTS_FT_TEMP_NA 64;
BA_ "FlexKomSigName" SG_ 608 PTS_FT_TEMP_NA "PTS_2_Pkt";
BA_ "FlexKomSigStartPos" SG_ 608 PTS_FT_TEMP_NA 7;
BA_ "FlexKomSigStartValue" SG_ 608 PTS_FT_TEMP_NA "FF001400000000FFh";
BA_ "GenSigCycleTime" SG_ 608 PTS_FT_TEMP_NA 500;
BA_ "GenSigSendType" SG_ 608 PTS_FT_TEMP_NA 5;
BA_ "GenSigSNA" SG_ 608 PTS_FT_TEMP_NA "0h";
BA_ "GenSigTimeout_IC" SG_ 608 PTS_FT_TEMP_NA 5250;
BA_ "FlexKomComment" SG_ 608 PTS_FT_VOL_TeenKey "PTS 2 message packet";
BA_ "FlexKomIsMotorola" SG_ 608 PTS_FT_VOL_TeenKey 1;
BA_ "FlexKomSID" SG_ 608 PTS_FT_VOL_TeenKey 1954;
BA_ "FlexKomSigLaenge" SG_ 608 PTS_FT_VOL_TeenKey 64;
BA_ "FlexKomSigName" SG_ 608 PTS_FT_VOL_TeenKey "PTS_2_Pkt";
BA_ "FlexKomSigStartPos" SG_ 608 PTS_FT_VOL_TeenKey 7;
BA_ "FlexKomSigStartValue" SG_ 608 PTS_FT_VOL_TeenKey "FF001400000000FFh";
BA_ "GenSigCycleTime" SG_ 608 PTS_FT_VOL_TeenKey 500;
BA_ "GenSigSendType" SG_ 608 PTS_FT_VOL_TeenKey 5;
BA_ "GenSigSNA" SG_ 608 PTS_FT_VOL_TeenKey "3h";
BA_ "GenSigStartValue" SG_ 608 PTS_FT_VOL_TeenKey 1;
BA_ "GenSigTimeout_CBC" SG_ 608 PTS_FT_VOL_TeenKey 5250;
BA_ "RID" SG_ 608 PTS_FT_VOL_TeenKey "2166";
BA_ "FlexKomComment" SG_ 608 PTS_Off_Status "PTS 2 message packet";
BA_ "FlexKomIsMotorola" SG_ 608 PTS_Off_Status 1;
BA_ "FlexKomSID" SG_ 608 PTS_Off_Status 1954;
BA_ "FlexKomSigLaenge" SG_ 608 PTS_Off_Status 64;
BA_ "FlexKomSigName" SG_ 608 PTS_Off_Status "PTS_2_Pkt";
BA_ "FlexKomSigStartPos" SG_ 608 PTS_Off_Status 7;
BA_ "FlexKomSigStartValue" SG_ 608 PTS_Off_Status "FF001400000000FFh";
BA_ "GenSigCycleTime" SG_ 608 PTS_Off_Status 500;
BA_ "GenSigSendType" SG_ 608 PTS_Off_Status 5;
BA_ "GenSigSNA" SG_ 608 PTS_Off_Status "0h";
BA_ "GenSigTimeout_IC" SG_ 608 PTS_Off_Status 5250;
BA_ "FlexKomComment" SG_ 608 PTS_PopUpRqst "PTS 2 message packet";
BA_ "FlexKomIsMotorola" SG_ 608 PTS_PopUpRqst 1;
BA_ "FlexKomSID" SG_ 608 PTS_PopUpRqst 1954;
BA_ "FlexKomSigLaenge" SG_ 608 PTS_PopUpRqst 64;
BA_ "FlexKomSigName" SG_ 608 PTS_PopUpRqst "PTS_2_Pkt";
BA_ "FlexKomSigStartPos" SG_ 608 PTS_PopUpRqst 7;
BA_ "FlexKomSigStartValue" SG_ 608 PTS_PopUpRqst "FF001400000000FFh";
BA_ "GenSigCycleTime" SG_ 608 PTS_PopUpRqst 500;
BA_ "GenSigSendType" SG_ 608 PTS_PopUpRqst 5;
BA_ "GenSigSNA" SG_ 608 PTS_PopUpRqst "FFh";
BA_ "GenSigTimeout_IC" SG_ 608 PTS_PopUpRqst 5250;
BA_ "FlexKomComment" SG_ 608 PTS_RR_TEMP_NA "PTS 2 message packet";
BA_ "FlexKomIsMotorola" SG_ 608 PTS_RR_TEMP_NA 1;
BA_ "FlexKomSID" SG_ 608 PTS_RR_TEMP_NA 1954;
BA_ "FlexKomSigLaenge" SG_ 608 PTS_RR_TEMP_NA 64;
BA_ "FlexKomSigName" SG_ 608 PTS_RR_TEMP_NA "PTS_2_Pkt";
BA_ "FlexKomSigStartPos" SG_ 608 PTS_RR_TEMP_NA 7;
BA_ "FlexKomSigStartValue" SG_ 608 PTS_RR_TEMP_NA "FF001400000000FFh";
BA_ "GenSigCycleTime" SG_ 608 PTS_RR_TEMP_NA 500;
BA_ "GenSigSendType" SG_ 608 PTS_RR_TEMP_NA 5;
BA_ "GenSigSNA" SG_ 608 PTS_RR_TEMP_NA "0h";
BA_ "GenSigTimeout_IC" SG_ 608 PTS_RR_TEMP_NA 5250;
BA_ "FlexKomComment" SG_ 608 PTS_RR_VOL_TeenKey "PTS 2 message packet";
BA_ "FlexKomIsMotorola" SG_ 608 PTS_RR_VOL_TeenKey 1;
BA_ "FlexKomSID" SG_ 608 PTS_RR_VOL_TeenKey 1954;
BA_ "FlexKomSigLaenge" SG_ 608 PTS_RR_VOL_TeenKey 64;
BA_ "FlexKomSigName" SG_ 608 PTS_RR_VOL_TeenKey "PTS_2_Pkt";
BA_ "FlexKomSigStartPos" SG_ 608 PTS_RR_VOL_TeenKey 7;
BA_ "FlexKomSigStartValue" SG_ 608 PTS_RR_VOL_TeenKey "FF001400000000FFh";
BA_ "GenSigCycleTime" SG_ 608 PTS_RR_VOL_TeenKey 500;
BA_ "GenSigSendType" SG_ 608 PTS_RR_VOL_TeenKey 5;
BA_ "GenSigSNA" SG_ 608 PTS_RR_VOL_TeenKey "3h";
BA_ "GenSigStartValue" SG_ 608 PTS_RR_VOL_TeenKey 1;
BA_ "GenSigTimeout_CBC" SG_ 608 PTS_RR_VOL_TeenKey 5250;
BA_ "RID" SG_ 608 PTS_RR_VOL_TeenKey "2170";
BA_ "FlexKomComment" SG_ 608 RR_PTS_Brk_RqSts "PTS 2 message packet";
BA_ "FlexKomIsMotorola" SG_ 608 RR_PTS_Brk_RqSts 1;
BA_ "FlexKomSID" SG_ 608 RR_PTS_Brk_RqSts 1954;
BA_ "FlexKomSigLaenge" SG_ 608 RR_PTS_Brk_RqSts 64;
BA_ "FlexKomSigName" SG_ 608 RR_PTS_Brk_RqSts "PTS_2_Pkt";
BA_ "FlexKomSigStartPos" SG_ 608 RR_PTS_Brk_RqSts 7;
BA_ "FlexKomSigStartValue" SG_ 608 RR_PTS_Brk_RqSts "FF001400000000FFh";
BA_ "GenSigCycleTime" SG_ 608 RR_PTS_Brk_RqSts 500;
BA_ "GenSigSendType" SG_ 608 RR_PTS_Brk_RqSts 5;
BA_ "GenSigSNA" SG_ 608 RR_PTS_Brk_RqSts "0h";
BA_ "FlexKomComment" SG_ 608 RR_PTS_Dist "PTS 2 message packet";
BA_ "FlexKomIsMotorola" SG_ 608 RR_PTS_Dist 1;
BA_ "FlexKomSID" SG_ 608 RR_PTS_Dist 1954;
BA_ "FlexKomSigLaenge" SG_ 608 RR_PTS_Dist 64;
BA_ "FlexKomSigName" SG_ 608 RR_PTS_Dist "PTS_2_Pkt";
BA_ "FlexKomSigStartPos" SG_ 608 RR_PTS_Dist 7;
BA_ "FlexKomSigStartValue" SG_ 608 RR_PTS_Dist "FF001400000000FFh";
BA_ "GenSigCycleTime" SG_ 608 RR_PTS_Dist 500;
BA_ "GenSigSendType" SG_ 608 RR_PTS_Dist 5;
BA_ "GenSigSNA" SG_ 608 RR_PTS_Dist "FFh";
BA_ "GenSigStartValue" SG_ 608 RR_PTS_Dist 255;
BA_ "FlexKomComment" SG_ 608 RR_PTS_StopControlSts "PTS 2 message packet";
BA_ "FlexKomIsMotorola" SG_ 608 RR_PTS_StopControlSts 1;
BA_ "FlexKomSID" SG_ 608 RR_PTS_StopControlSts 1954;
BA_ "FlexKomSigLaenge" SG_ 608 RR_PTS_StopControlSts 64;
BA_ "FlexKomSigName" SG_ 608 RR_PTS_StopControlSts "PTS_2_Pkt";
BA_ "FlexKomSigStartPos" SG_ 608 RR_PTS_StopControlSts 7;
BA_ "FlexKomSigStartValue" SG_ 608 RR_PTS_StopControlSts "FF001400000000FFh";
BA_ "GenSigCycleTime" SG_ 608 RR_PTS_StopControlSts 500;
BA_ "GenSigSendType" SG_ 608 RR_PTS_StopControlSts 5;
BA_ "GenSigSNA" SG_ 608 RR_PTS_StopControlSts "0h";
BA_ "RID" SG_ 608 RR_PTS_StopControlSts "2054";
BA_ "FlexKomComment" SG_ 608 RR_PTS_StopControlStsTeen "PTS 2 message packet";
BA_ "FlexKomIsMotorola" SG_ 608 RR_PTS_StopControlStsTeen 1;
BA_ "FlexKomSID" SG_ 608 RR_PTS_StopControlStsTeen 1954;
BA_ "FlexKomSigLaenge" SG_ 608 RR_PTS_StopControlStsTeen 64;
BA_ "FlexKomSigName" SG_ 608 RR_PTS_StopControlStsTeen "PTS_2_Pkt";
BA_ "FlexKomSigStartPos" SG_ 608 RR_PTS_StopControlStsTeen 7;
BA_ "FlexKomSigStartValue" SG_ 608 RR_PTS_StopControlStsTeen "FF001400000000FFh";
BA_ "GenSigCycleTime" SG_ 608 RR_PTS_StopControlStsTeen 500;
BA_ "GenSigSendType" SG_ 608 RR_PTS_StopControlStsTeen 5;
BA_ "GenSigSNA" SG_ 608 RR_PTS_StopControlStsTeen "0h";
BA_ "RID" SG_ 608 RR_PTS_StopControlStsTeen "2167";
BA_ "FlexKomComment" SG_ 825 PTS_CHIME_REP_RATE "PTS chime status";
BA_ "FlexKomIsMotorola" SG_ 825 PTS_CHIME_REP_RATE 1;
BA_ "FlexKomSID" SG_ 825 PTS_CHIME_REP_RATE 1350;
BA_ "FlexKomSigLaenge" SG_ 825 PTS_CHIME_REP_RATE 16;
BA_ "FlexKomSigName" SG_ 825 PTS_CHIME_REP_RATE "PTS_CHIME_STAT";
BA_ "FlexKomSigStartPos" SG_ 825 PTS_CHIME_REP_RATE 7;
BA_ "FlexKomSigStartValue" SG_ 825 PTS_CHIME_REP_RATE "0050h";
BA_ "GenSigCycleTime" SG_ 825 PTS_CHIME_REP_RATE 500;
BA_ "GenSigSendType" SG_ 825 PTS_CHIME_REP_RATE 5;
BA_ "GenSigSNA" SG_ 825 PTS_CHIME_REP_RATE "0h";
BA_ "RID" SG_ 825 PTS_CHIME_REP_RATE "1140";
BA_ "FlexKomComment" SG_ 825 PTS_CHIME_TYPE "PTS chime status";
BA_ "FlexKomIsMotorola" SG_ 825 PTS_CHIME_TYPE 1;
BA_ "FlexKomSID" SG_ 825 PTS_CHIME_TYPE 1350;
BA_ "FlexKomSigLaenge" SG_ 825 PTS_CHIME_TYPE 16;
BA_ "FlexKomSigName" SG_ 825 PTS_CHIME_TYPE "PTS_CHIME_STAT";
BA_ "FlexKomSigStartPos" SG_ 825 PTS_CHIME_TYPE 7;
BA_ "FlexKomSigStartValue" SG_ 825 PTS_CHIME_TYPE "0050h";
BA_ "GenSigCycleTime" SG_ 825 PTS_CHIME_TYPE 500;
BA_ "GenSigSendType" SG_ 825 PTS_CHIME_TYPE 5;
BA_ "GenSigSNA" SG_ 825 PTS_CHIME_TYPE "Fh";
BA_ "GenSigTimeout_CBC" SG_ 825 PTS_CHIME_TYPE 5250;
BA_ "RID" SG_ 825 PTS_CHIME_TYPE "1190";
BA_ "FlexKomComment" SG_ 825 PTS_FT_VOL "PTS chime status";
BA_ "FlexKomIsMotorola" SG_ 825 PTS_FT_VOL 1;
BA_ "FlexKomSID" SG_ 825 PTS_FT_VOL 1350;
BA_ "FlexKomSigLaenge" SG_ 825 PTS_FT_VOL 16;
BA_ "FlexKomSigName" SG_ 825 PTS_FT_VOL "PTS_CHIME_STAT";
BA_ "FlexKomSigStartPos" SG_ 825 PTS_FT_VOL 7;
BA_ "FlexKomSigStartValue" SG_ 825 PTS_FT_VOL "0050h";
BA_ "GenSigCycleTime" SG_ 825 PTS_FT_VOL 500;
BA_ "GenSigSendType" SG_ 825 PTS_FT_VOL 5;
BA_ "GenSigSNA" SG_ 825 PTS_FT_VOL "3h";
BA_ "GenSigStartValue" SG_ 825 PTS_FT_VOL 1;
BA_ "GenSigTimeout_CBC" SG_ 825 PTS_FT_VOL 5250;
BA_ "GenSigTimeout_IC" SG_ 825 PTS_FT_VOL 5250;
BA_ "RID" SG_ 825 PTS_FT_VOL "1886";
BA_ "FlexKomComment" SG_ 825 PTS_LF_CHIME_RQ "PTS chime status";
BA_ "FlexKomIsMotorola" SG_ 825 PTS_LF_CHIME_RQ 1;
BA_ "FlexKomSID" SG_ 825 PTS_LF_CHIME_RQ 1350;
BA_ "FlexKomSigLaenge" SG_ 825 PTS_LF_CHIME_RQ 16;
BA_ "FlexKomSigName" SG_ 825 PTS_LF_CHIME_RQ "PTS_CHIME_STAT";
BA_ "FlexKomSigStartPos" SG_ 825 PTS_LF_CHIME_RQ 7;
BA_ "FlexKomSigStartValue" SG_ 825 PTS_LF_CHIME_RQ "0050h";
BA_ "GenSigCycleTime" SG_ 825 PTS_LF_CHIME_RQ 500;
BA_ "GenSigSendType" SG_ 825 PTS_LF_CHIME_RQ 5;
BA_ "GenSigSNA" SG_ 825 PTS_LF_CHIME_RQ "0h";
BA_ "RID" SG_ 825 PTS_LF_CHIME_RQ "1083";
BA_ "FlexKomComment" SG_ 825 PTS_LR_CHIME_RQ "PTS chime status";
BA_ "FlexKomIsMotorola" SG_ 825 PTS_LR_CHIME_RQ 1;
BA_ "FlexKomSID" SG_ 825 PTS_LR_CHIME_RQ 1350;
BA_ "FlexKomSigLaenge" SG_ 825 PTS_LR_CHIME_RQ 16;
BA_ "FlexKomSigName" SG_ 825 PTS_LR_CHIME_RQ "PTS_CHIME_STAT";
BA_ "FlexKomSigStartPos" SG_ 825 PTS_LR_CHIME_RQ 7;
BA_ "FlexKomSigStartValue" SG_ 825 PTS_LR_CHIME_RQ "0050h";
BA_ "GenSigCycleTime" SG_ 825 PTS_LR_CHIME_RQ 500;
BA_ "GenSigSendType" SG_ 825 PTS_LR_CHIME_RQ 5;
BA_ "GenSigSNA" SG_ 825 PTS_LR_CHIME_RQ "0h";
BA_ "RID" SG_ 825 PTS_LR_CHIME_RQ "1054";
BA_ "FlexKomComment" SG_ 825 PTS_RF_CHIME_RQ "PTS chime status";
BA_ "FlexKomIsMotorola" SG_ 825 PTS_RF_CHIME_RQ 1;
BA_ "FlexKomSID" SG_ 825 PTS_RF_CHIME_RQ 1350;
BA_ "FlexKomSigLaenge" SG_ 825 PTS_RF_CHIME_RQ 16;
BA_ "FlexKomSigName" SG_ 825 PTS_RF_CHIME_RQ "PTS_CHIME_STAT";
BA_ "FlexKomSigStartPos" SG_ 825 PTS_RF_CHIME_RQ 7;
BA_ "FlexKomSigStartValue" SG_ 825 PTS_RF_CHIME_RQ "0050h";
BA_ "GenSigCycleTime" SG_ 825 PTS_RF_CHIME_RQ 500;
BA_ "GenSigSendType" SG_ 825 PTS_RF_CHIME_RQ 5;
BA_ "GenSigSNA" SG_ 825 PTS_RF_CHIME_RQ "0h";
BA_ "RID" SG_ 825 PTS_RF_CHIME_RQ "1240";
BA_ "FlexKomComment" SG_ 825 PTS_RR_CHIME_RQ "PTS chime status";
BA_ "FlexKomIsMotorola" SG_ 825 PTS_RR_CHIME_RQ 1;
BA_ "FlexKomSID" SG_ 825 PTS_RR_CHIME_RQ 1350;
BA_ "FlexKomSigLaenge" SG_ 825 PTS_RR_CHIME_RQ 16;
BA_ "FlexKomSigName" SG_ 825 PTS_RR_CHIME_RQ "PTS_CHIME_STAT";
BA_ "FlexKomSigStartPos" SG_ 825 PTS_RR_CHIME_RQ 7;
BA_ "FlexKomSigStartValue" SG_ 825 PTS_RR_CHIME_RQ "0050h";
BA_ "GenSigCycleTime" SG_ 825 PTS_RR_CHIME_RQ 500;
BA_ "GenSigSendType" SG_ 825 PTS_RR_CHIME_RQ 5;
BA_ "GenSigSNA" SG_ 825 PTS_RR_CHIME_RQ "0h";
BA_ "RID" SG_ 825 PTS_RR_CHIME_RQ "1090";
BA_ "FlexKomComment" SG_ 825 PTS_RR_VOL "PTS chime status";
BA_ "FlexKomIsMotorola" SG_ 825 PTS_RR_VOL 1;
BA_ "FlexKomSID" SG_ 825 PTS_RR_VOL 1350;
BA_ "FlexKomSigLaenge" SG_ 825 PTS_RR_VOL 16;
BA_ "FlexKomSigName" SG_ 825 PTS_RR_VOL "PTS_CHIME_STAT";
BA_ "FlexKomSigStartPos" SG_ 825 PTS_RR_VOL 7;
BA_ "FlexKomSigStartValue" SG_ 825 PTS_RR_VOL "0050h";
BA_ "GenSigCycleTime" SG_ 825 PTS_RR_VOL 500;
BA_ "GenSigSendType" SG_ 825 PTS_RR_VOL 5;
BA_ "GenSigSNA" SG_ 825 PTS_RR_VOL "3h";
BA_ "GenSigStartValue" SG_ 825 PTS_RR_VOL 1;
BA_ "GenSigTimeout_CBC" SG_ 825 PTS_RR_VOL 5250;
BA_ "GenSigTimeout_IC" SG_ 825 PTS_RR_VOL 5250;
BA_ "RID" SG_ 825 PTS_RR_VOL "1891";
BA_ "FlexKomComment" SG_ 671 CRC_29Fh "PTS steering control packet";
BA_ "FlexKomIsMotorola" SG_ 671 CRC_29Fh 1;
BA_ "FlexKomSID" SG_ 671 CRC_29Fh 1907;
BA_ "FlexKomSigLaenge" SG_ 671 CRC_29Fh 64;
BA_ "FlexKomSigName" SG_ 671 CRC_29Fh "PTS_StrCtrl";
BA_ "FlexKomSigStartPos" SG_ 671 CRC_29Fh 7;
BA_ "FlexKomSigStartValue" SG_ 671 CRC_29Fh "04000000000000FFh";
BA_ "GenSigCycleTime" SG_ 671 CRC_29Fh 20;
BA_ "GenSigSNA" SG_ 671 CRC_29Fh "FFh";
BA_ "GenSigStartValue" SG_ 671 CRC_29Fh 255;
BA_ "FlexKomComment" SG_ 671 MC_29Fh "PTS steering control packet";
BA_ "FlexKomIsMotorola" SG_ 671 MC_29Fh 1;
BA_ "FlexKomSID" SG_ 671 MC_29Fh 1907;
BA_ "FlexKomSigLaenge" SG_ 671 MC_29Fh 64;
BA_ "FlexKomSigName" SG_ 671 MC_29Fh "PTS_StrCtrl";
BA_ "FlexKomSigStartPos" SG_ 671 MC_29Fh 7;
BA_ "FlexKomSigStartValue" SG_ 671 MC_29Fh "04000000000000FFh";
BA_ "GenSigCycleTime" SG_ 671 MC_29Fh 20;
BA_ "GenSigSNA" SG_ 671 MC_29Fh "0h";
BA_ "FlexKomComment" SG_ 671 ManeuverPhase "PTS steering control packet";
BA_ "FlexKomIsMotorola" SG_ 671 ManeuverPhase 1;
BA_ "FlexKomSID" SG_ 671 ManeuverPhase 1907;
BA_ "FlexKomSigLaenge" SG_ 671 ManeuverPhase 64;
BA_ "FlexKomSigName" SG_ 671 ManeuverPhase "PTS_StrCtrl";
BA_ "FlexKomSigStartPos" SG_ 671 ManeuverPhase 7;
BA_ "FlexKomSigStartValue" SG_ 671 ManeuverPhase "04000000000000FFh";
BA_ "GenSigCycleTime" SG_ 671 ManeuverPhase 20;
BA_ "GenSigSNA" SG_ 671 ManeuverPhase "0h";
BA_ "FlexKomComment" SG_ 671 PTSDriveStyleReqSts "PTS steering control packet";
BA_ "FlexKomIsMotorola" SG_ 671 PTSDriveStyleReqSts 1;
BA_ "FlexKomSID" SG_ 671 PTSDriveStyleReqSts 1907;
BA_ "FlexKomSigLaenge" SG_ 671 PTSDriveStyleReqSts 64;
BA_ "FlexKomSigName" SG_ 671 PTSDriveStyleReqSts "PTS_StrCtrl";
BA_ "FlexKomSigStartPos" SG_ 671 PTSDriveStyleReqSts 7;
BA_ "FlexKomSigStartValue" SG_ 671 PTSDriveStyleReqSts "04000000000000FFh";
BA_ "GenSigCycleTime" SG_ 671 PTSDriveStyleReqSts 20;
BA_ "GenSigSNA" SG_ 671 PTSDriveStyleReqSts "0h";
BA_ "FlexKomComment" SG_ 671 PTSSystemFault "PTS steering control packet";
BA_ "FlexKomIsMotorola" SG_ 671 PTSSystemFault 1;
BA_ "FlexKomSID" SG_ 671 PTSSystemFault 1907;
BA_ "FlexKomSigLaenge" SG_ 671 PTSSystemFault 64;
BA_ "FlexKomSigName" SG_ 671 PTSSystemFault "PTS_StrCtrl";
BA_ "FlexKomSigStartPos" SG_ 671 PTSSystemFault 7;
BA_ "FlexKomSigStartValue" SG_ 671 PTSSystemFault "04000000000000FFh";
BA_ "GenSigCycleTime" SG_ 671 PTSSystemFault 20;
BA_ "GenSigSNA" SG_ 671 PTSSystemFault "0h";
BA_ "GenSigTimeout_IC" SG_ 671 PTSSystemFault 210;
BA_ "FlexKomComment" SG_ 671 PTS_ManoeuvreMode "PTS steering control packet";
BA_ "FlexKomIsMotorola" SG_ 671 PTS_ManoeuvreMode 1;
BA_ "FlexKomSID" SG_ 671 PTS_ManoeuvreMode 1907;
BA_ "FlexKomSigLaenge" SG_ 671 PTS_ManoeuvreMode 64;
BA_ "FlexKomSigName" SG_ 671 PTS_ManoeuvreMode "PTS_StrCtrl";
BA_ "FlexKomSigStartPos" SG_ 671 PTS_ManoeuvreMode 7;
BA_ "FlexKomSigStartValue" SG_ 671 PTS_ManoeuvreMode "04000000000000FFh";
BA_ "GenSigCycleTime" SG_ 671 PTS_ManoeuvreMode 20;
BA_ "GenSigSNA" SG_ 671 PTS_ManoeuvreMode "7h";
BA_ "GenSigTimeout_IC" SG_ 671 PTS_ManoeuvreMode 210;
BA_ "FlexKomComment" SG_ 671 TorqueOverlayIntActivation "PTS steering control packet";
BA_ "FlexKomIsMotorola" SG_ 671 TorqueOverlayIntActivation 1;
BA_ "FlexKomSID" SG_ 671 TorqueOverlayIntActivation 1907;
BA_ "FlexKomSigLaenge" SG_ 671 TorqueOverlayIntActivation 64;
BA_ "FlexKomSigName" SG_ 671 TorqueOverlayIntActivation "PTS_StrCtrl";
BA_ "FlexKomSigStartPos" SG_ 671 TorqueOverlayIntActivation 7;
BA_ "FlexKomSigStartValue" SG_ 671 TorqueOverlayIntActivation "04000000000000FFh";
BA_ "GenSigCycleTime" SG_ 671 TorqueOverlayIntActivation 20;
BA_ "GenSigSNA" SG_ 671 TorqueOverlayIntActivation "0h";
BA_ "FlexKomComment" SG_ 671 TorqueOverlaySteeringReq "PTS steering control packet";
BA_ "FlexKomIsMotorola" SG_ 671 TorqueOverlaySteeringReq 1;
BA_ "FlexKomSID" SG_ 671 TorqueOverlaySteeringReq 1907;
BA_ "FlexKomSigLaenge" SG_ 671 TorqueOverlaySteeringReq 64;
BA_ "FlexKomSigName" SG_ 671 TorqueOverlaySteeringReq "PTS_StrCtrl";
BA_ "FlexKomSigStartPos" SG_ 671 TorqueOverlaySteeringReq 7;
BA_ "FlexKomSigStartValue" SG_ 671 TorqueOverlaySteeringReq "04000000000000FFh";
BA_ "GenSigCycleTime" SG_ 671 TorqueOverlaySteeringReq 20;
BA_ "GenSigSNA" SG_ 671 TorqueOverlaySteeringReq "400h";
BA_ "GenSigStartValue" SG_ 671 TorqueOverlaySteeringReq 1024;
BA_ "FlexKomComment" SG_ 388 CustKeyInIgn "Customer ignition packet";
BA_ "FlexKomIsMotorola" SG_ 388 CustKeyInIgn 1;
BA_ "FlexKomSID" SG_ 388 CustKeyInIgn 1034;
BA_ "FlexKomSigLaenge" SG_ 388 CustKeyInIgn 32;
BA_ "FlexKomSigName" SG_ 388 CustKeyInIgn "CustIgnPkt";
BA_ "FlexKomSigStartPos" SG_ 388 CustKeyInIgn 7;
BA_ "FlexKomSigStartValue" SG_ 388 CustKeyInIgn "1C000000h";
BA_ "GenSigCycleTime" SG_ 388 CustKeyInIgn 100;
BA_ "GenSigSendType" SG_ 388 CustKeyInIgn 5;
BA_ "GenSigSNA" SG_ 388 CustKeyInIgn "3h";
BA_ "FlexKomComment" SG_ 388 IgnPos "Customer ignition packet";
BA_ "FlexKomIsMotorola" SG_ 388 IgnPos 1;
BA_ "FlexKomSID" SG_ 388 IgnPos 1034;
BA_ "FlexKomSigLaenge" SG_ 388 IgnPos 32;
BA_ "FlexKomSigName" SG_ 388 IgnPos "CustIgnPkt";
BA_ "FlexKomSigStartPos" SG_ 388 IgnPos 7;
BA_ "FlexKomSigStartValue" SG_ 388 IgnPos "1C000000h";
BA_ "GenSigCycleTime" SG_ 388 IgnPos 100;
BA_ "GenSigSendType" SG_ 388 IgnPos 5;
BA_ "GenSigSNA" SG_ 388 IgnPos "7h";
BA_ "GenSigStartValue" SG_ 388 IgnPos 7;
BA_ "GenSigTimeout_CBC" SG_ 388 IgnPos 1050;
BA_ "FlexKomComment" SG_ 388 TeenKey "Customer ignition packet";
BA_ "FlexKomIsMotorola" SG_ 388 TeenKey 1;
BA_ "FlexKomSID" SG_ 388 TeenKey 1034;
BA_ "FlexKomSigLaenge" SG_ 388 TeenKey 32;
BA_ "FlexKomSigName" SG_ 388 TeenKey "CustIgnPkt";
BA_ "FlexKomSigStartPos" SG_ 388 TeenKey 7;
BA_ "FlexKomSigStartValue" SG_ 388 TeenKey "1C000000h";
BA_ "GenSigCycleTime" SG_ 388 TeenKey 100;
BA_ "GenSigSendType" SG_ 388 TeenKey 5;
BA_ "GenSigSNA" SG_ 388 TeenKey "0h";
BA_ "FlexKomComment" SG_ 388 ValImmKey "Customer ignition packet";
BA_ "FlexKomIsMotorola" SG_ 388 ValImmKey 1;
BA_ "FlexKomSID" SG_ 388 ValImmKey 1034;
BA_ "FlexKomSigLaenge" SG_ 388 ValImmKey 32;
BA_ "FlexKomSigName" SG_ 388 ValImmKey "CustIgnPkt";
BA_ "FlexKomSigStartPos" SG_ 388 ValImmKey 7;
BA_ "FlexKomSigStartValue" SG_ 388 ValImmKey "1C000000h";
BA_ "GenSigCycleTime" SG_ 388 ValImmKey 100;
BA_ "GenSigSendType" SG_ 388 ValImmKey 5;
BA_ "GenSigSNA" SG_ 388 ValImmKey "3h";
BA_ "FlexKomComment" SG_ 448 KeyProgramSts "RFHUB_A2_Pkt";
BA_ "FlexKomIsMotorola" SG_ 448 KeyProgramSts 1;
BA_ "FlexKomSID" SG_ 448 KeyProgramSts 1037;
BA_ "FlexKomSigLaenge" SG_ 448 KeyProgramSts 48;
BA_ "FlexKomSigName" SG_ 448 KeyProgramSts "RFHUB_A2_Pkt";
BA_ "FlexKomSigStartPos" SG_ 448 KeyProgramSts 7;
BA_ "FlexKomSigStartValue" SG_ 448 KeyProgramSts "000000000000h";
BA_ "GenSigCycleTime" SG_ 448 KeyProgramSts 200;
BA_ "GenSigSendType" SG_ 448 KeyProgramSts 5;
BA_ "GenSigSNA" SG_ 448 KeyProgramSts "Fh";
BA_ "GenSigTimeout_IC" SG_ 448 KeyProgramSts 2100;
BA_ "RID" SG_ 448 KeyProgramSts "1678";
BA_ "FlexKomComment" SG_ 448 PE_ENABLE "RFHUB_A2_Pkt";
BA_ "FlexKomIsMotorola" SG_ 448 PE_ENABLE 1;
BA_ "FlexKomSID" SG_ 448 PE_ENABLE 1037;
BA_ "FlexKomSigLaenge" SG_ 448 PE_ENABLE 48;
BA_ "FlexKomSigName" SG_ 448 PE_ENABLE "RFHUB_A2_Pkt";
BA_ "FlexKomSigStartPos" SG_ 448 PE_ENABLE 7;
BA_ "FlexKomSigStartValue" SG_ 448 PE_ENABLE "000000000000h";
BA_ "GenSigCycleTime" SG_ 448 PE_ENABLE 200;
BA_ "GenSigSendType" SG_ 448 PE_ENABLE 5;
BA_ "GenSigSNA" SG_ 448 PE_ENABLE "0h";
BA_ "GenSigTimeout_IC" SG_ 448 PE_ENABLE 2100;
BA_ "RID" SG_ 448 PE_ENABLE "1166";
BA_ "FlexKomComment" SG_ 448 RFCfgReq "RFHUB_A2_Pkt";
BA_ "FlexKomIsMotorola" SG_ 448 RFCfgReq 1;
BA_ "FlexKomSID" SG_ 448 RFCfgReq 1037;
BA_ "FlexKomSigLaenge" SG_ 448 RFCfgReq 48;
BA_ "FlexKomSigName" SG_ 448 RFCfgReq "RFHUB_A2_Pkt";
BA_ "FlexKomSigStartPos" SG_ 448 RFCfgReq 7;
BA_ "FlexKomSigStartValue" SG_ 448 RFCfgReq "000000000000h";
BA_ "GenSigCycleTime" SG_ 448 RFCfgReq 200;
BA_ "GenSigSendType" SG_ 448 RFCfgReq 5;
BA_ "GenSigSNA" SG_ 448 RFCfgReq "7h";
BA_ "RID" SG_ 448 RFCfgReq "1151";
BA_ "FlexKomComment" SG_ 448 RFFobNum "RFHUB_A2_Pkt";
BA_ "FlexKomIsMotorola" SG_ 448 RFFobNum 1;
BA_ "FlexKomSID" SG_ 448 RFFobNum 1037;
BA_ "FlexKomSigLaenge" SG_ 448 RFFobNum 48;
BA_ "FlexKomSigName" SG_ 448 RFFobNum "RFHUB_A2_Pkt";
BA_ "FlexKomSigStartPos" SG_ 448 RFFobNum 7;
BA_ "FlexKomSigStartValue" SG_ 448 RFFobNum "000000000000h";
BA_ "GenSigCycleTime" SG_ 448 RFFobNum 200;
BA_ "GenSigSendType" SG_ 448 RFFobNum 5;
BA_ "GenSigSNA" SG_ 448 RFFobNum "Fh";
BA_ "RID" SG_ 448 RFFobNum "1157";
BA_ "FlexKomComment" SG_ 448 RFFuncReq "RFHUB_A2_Pkt";
BA_ "FlexKomIsMotorola" SG_ 448 RFFuncReq 1;
BA_ "FlexKomSID" SG_ 448 RFFuncReq 1037;
BA_ "FlexKomSigLaenge" SG_ 448 RFFuncReq 48;
BA_ "FlexKomSigName" SG_ 448 RFFuncReq "RFHUB_A2_Pkt";
BA_ "FlexKomSigStartPos" SG_ 448 RFFuncReq 7;
BA_ "FlexKomSigStartValue" SG_ 448 RFFuncReq "000000000000h";
BA_ "GenSigCycleTime" SG_ 448 RFFuncReq 200;
BA_ "GenSigSendType" SG_ 448 RFFuncReq 5;
BA_ "GenSigSNA" SG_ 448 RFFuncReq "1Fh";
BA_ "GenSigTimeout_IC" SG_ 448 RFFuncReq 2100;
BA_ "RID" SG_ 448 RFFuncReq "1255";
BA_ "FlexKomComment" SG_ 448 RFReq "RFHUB_A2_Pkt";
BA_ "FlexKomIsMotorola" SG_ 448 RFReq 1;
BA_ "FlexKomSID" SG_ 448 RFReq 1037;
BA_ "FlexKomSigLaenge" SG_ 448 RFReq 48;
BA_ "FlexKomSigName" SG_ 448 RFReq "RFHUB_A2_Pkt";
BA_ "FlexKomSigStartPos" SG_ 448 RFReq 7;
BA_ "FlexKomSigStartValue" SG_ 448 RFReq "000000000000h";
BA_ "GenSigCycleTime" SG_ 448 RFReq 200;
BA_ "GenSigSendType" SG_ 448 RFReq 5;
BA_ "GenSigSNA" SG_ 448 RFReq "7h";
BA_ "RID" SG_ 448 RFReq "1288";
BA_ "FlexKomComment" SG_ 924 FOB_ExtLT "RF message packet";
BA_ "FlexKomIsMotorola" SG_ 924 FOB_ExtLT 1;
BA_ "FlexKomSID" SG_ 924 FOB_ExtLT 1038;
BA_ "FlexKomSigLaenge" SG_ 924 FOB_ExtLT 64;
BA_ "FlexKomSigName" SG_ 924 FOB_ExtLT "RFMsgPkt";
BA_ "FlexKomSigStartPos" SG_ 924 FOB_ExtLT 7;
BA_ "FlexKomSigStartValue" SG_ 924 FOB_ExtLT "000000h";
BA_ "GenSigCycleTime" SG_ 924 FOB_ExtLT 1000;
BA_ "GenSigSendType" SG_ 924 FOB_ExtLT 5;
BA_ "GenSigSNA" SG_ 924 FOB_ExtLT "0h";
BA_ "FlexKomComment" SG_ 924 FOB_ExtRR "RF message packet";
BA_ "FlexKomIsMotorola" SG_ 924 FOB_ExtRR 1;
BA_ "FlexKomSID" SG_ 924 FOB_ExtRR 1038;
BA_ "FlexKomSigLaenge" SG_ 924 FOB_ExtRR 64;
BA_ "FlexKomSigName" SG_ 924 FOB_ExtRR "RFMsgPkt";
BA_ "FlexKomSigStartPos" SG_ 924 FOB_ExtRR 7;
BA_ "FlexKomSigStartValue" SG_ 924 FOB_ExtRR "0000000000000000h";
BA_ "GenSigCycleTime" SG_ 924 FOB_ExtRR 1000;
BA_ "GenSigSendType" SG_ 924 FOB_ExtRR 5;
BA_ "GenSigSNA" SG_ 924 FOB_ExtRR "0h";
BA_ "FlexKomComment" SG_ 924 FOB_ExtRT "RF message packet";
BA_ "FlexKomIsMotorola" SG_ 924 FOB_ExtRT 1;
BA_ "FlexKomSID" SG_ 924 FOB_ExtRT 1038;
BA_ "FlexKomSigLaenge" SG_ 924 FOB_ExtRT 64;
BA_ "FlexKomSigName" SG_ 924 FOB_ExtRT "RFMsgPkt";
BA_ "FlexKomSigStartPos" SG_ 924 FOB_ExtRT 7;
BA_ "FlexKomSigStartValue" SG_ 924 FOB_ExtRT "0000000000000000h";
BA_ "GenSigCycleTime" SG_ 924 FOB_ExtRT 1000;
BA_ "GenSigSendType" SG_ 924 FOB_ExtRT 5;
BA_ "GenSigSNA" SG_ 924 FOB_ExtRT "0h";
BA_ "FlexKomComment" SG_ 924 FOB_SrchFLT "RF message packet";
BA_ "FlexKomIsMotorola" SG_ 924 FOB_SrchFLT 1;
BA_ "FlexKomSID" SG_ 924 FOB_SrchFLT 1038;
BA_ "FlexKomSigLaenge" SG_ 924 FOB_SrchFLT 64;
BA_ "FlexKomSigName" SG_ 924 FOB_SrchFLT "RFMsgPkt";
BA_ "FlexKomSigStartPos" SG_ 924 FOB_SrchFLT 7;
BA_ "FlexKomSigStartValue" SG_ 924 FOB_SrchFLT "0000000000000000h";
BA_ "GenSigCycleTime" SG_ 924 FOB_SrchFLT 1000;
BA_ "GenSigSendType" SG_ 924 FOB_SrchFLT 5;
BA_ "GenSigSNA" SG_ 924 FOB_SrchFLT "0h";
BA_ "FlexKomComment" SG_ 924 FOB_SrchRslt "RF message packet";
BA_ "FlexKomIsMotorola" SG_ 924 FOB_SrchRslt 1;
BA_ "FlexKomSID" SG_ 924 FOB_SrchRslt 1038;
BA_ "FlexKomSigLaenge" SG_ 924 FOB_SrchRslt 64;
BA_ "FlexKomSigName" SG_ 924 FOB_SrchRslt "RFMsgPkt";
BA_ "FlexKomSigStartPos" SG_ 924 FOB_SrchRslt 7;
BA_ "FlexKomSigStartValue" SG_ 924 FOB_SrchRslt "0000000000000000h";
BA_ "GenSigCycleTime" SG_ 924 FOB_SrchRslt 1000;
BA_ "GenSigSendType" SG_ 924 FOB_SrchRslt 5;
BA_ "GenSigSNA" SG_ 924 FOB_SrchRslt "0h";
BA_ "GenSigTimeout_CBC" SG_ 924 FOB_SrchRslt 10500;
BA_ "FlexKomComment" SG_ 924 FOBinINT "RF message packet";
BA_ "FlexKomIsMotorola" SG_ 924 FOBinINT 1;
BA_ "FlexKomSID" SG_ 924 FOBinINT 1038;
BA_ "FlexKomSigLaenge" SG_ 924 FOBinINT 64;
BA_ "FlexKomSigName" SG_ 924 FOBinINT "RFMsgPkt";
BA_ "FlexKomSigStartPos" SG_ 924 FOBinINT 7;
BA_ "FlexKomSigStartValue" SG_ 924 FOBinINT "0000000000000000h";
BA_ "GenSigCycleTime" SG_ 924 FOBinINT 1000;
BA_ "GenSigSendType" SG_ 924 FOBinINT 5;
BA_ "GenSigSNA" SG_ 924 FOBinINT "0h";
BA_ "FlexKomComment" SG_ 924 FOBinTRUNK "RF message packet";
BA_ "FlexKomIsMotorola" SG_ 924 FOBinTRUNK 1;
BA_ "FlexKomSID" SG_ 924 FOBinTRUNK 1038;
BA_ "FlexKomSigLaenge" SG_ 924 FOBinTRUNK 64;
BA_ "FlexKomSigName" SG_ 924 FOBinTRUNK "RFMsgPkt";
BA_ "FlexKomSigStartPos" SG_ 924 FOBinTRUNK 7;
BA_ "FlexKomSigStartValue" SG_ 924 FOBinTRUNK "0000000000000000h";
BA_ "GenSigCycleTime" SG_ 924 FOBinTRUNK 1000;
BA_ "GenSigSendType" SG_ 924 FOBinTRUNK 5;
BA_ "GenSigSNA" SG_ 924 FOBinTRUNK "0h";
BA_ "FlexKomComment" SG_ 924 MsgFobBattLow "RF message packet";
BA_ "FlexKomIsMotorola" SG_ 924 MsgFobBattLow 1;
BA_ "FlexKomSID" SG_ 924 MsgFobBattLow 1038;
BA_ "FlexKomSigLaenge" SG_ 924 MsgFobBattLow 64;
BA_ "FlexKomSigName" SG_ 924 MsgFobBattLow "RFMsgPkt";
BA_ "FlexKomSigStartPos" SG_ 924 MsgFobBattLow 7;
BA_ "FlexKomSigStartValue" SG_ 924 MsgFobBattLow "0000000000000000h";
BA_ "GenSigCycleTime" SG_ 924 MsgFobBattLow 1000;
BA_ "GenSigSendType" SG_ 924 MsgFobBattLow 5;
BA_ "GenSigSNA" SG_ 924 MsgFobBattLow "3h";
BA_ "GenSigTimeout_IC" SG_ 924 MsgFobBattLow 10500;
BA_ "FlexKomComment" SG_ 924 MsgFobNotFnd "RF message packet";
BA_ "FlexKomIsMotorola" SG_ 924 MsgFobNotFnd 1;
BA_ "FlexKomSID" SG_ 924 MsgFobNotFnd 1038;
BA_ "FlexKomSigLaenge" SG_ 924 MsgFobNotFnd 64;
BA_ "FlexKomSigName" SG_ 924 MsgFobNotFnd "RFMsgPkt";
BA_ "FlexKomSigStartPos" SG_ 924 MsgFobNotFnd 7;
BA_ "FlexKomSigStartValue" SG_ 924 MsgFobNotFnd "0000000000000000h";
BA_ "GenSigCycleTime" SG_ 924 MsgFobNotFnd 1000;
BA_ "GenSigSendType" SG_ 924 MsgFobNotFnd 5;
BA_ "GenSigSNA" SG_ 924 MsgFobNotFnd "3h";
BA_ "GenSigTimeout_IC" SG_ 924 MsgFobNotFnd 10500;
BA_ "FlexKomComment" SG_ 924 MsgKG1 "RF message packet";
BA_ "FlexKomIsMotorola" SG_ 924 MsgKG1 1;
BA_ "FlexKomSID" SG_ 924 MsgKG1 1038;
BA_ "FlexKomSigLaenge" SG_ 924 MsgKG1 64;
BA_ "FlexKomSigName" SG_ 924 MsgKG1 "RFMsgPkt";
BA_ "FlexKomSigStartPos" SG_ 924 MsgKG1 7;
BA_ "FlexKomSigStartValue" SG_ 924 MsgKG1 "0000000000000000h";
BA_ "GenSigCycleTime" SG_ 924 MsgKG1 1000;
BA_ "GenSigSendType" SG_ 924 MsgKG1 5;
BA_ "GenSigSNA" SG_ 924 MsgKG1 "3h";
BA_ "GenSigTimeout_IC" SG_ 924 MsgKG1 10500;
BA_ "FlexKomComment" SG_ 924 MsgKG2 "RF message packet";
BA_ "FlexKomIsMotorola" SG_ 924 MsgKG2 1;
BA_ "FlexKomSID" SG_ 924 MsgKG2 1038;
BA_ "FlexKomSigLaenge" SG_ 924 MsgKG2 64;
BA_ "FlexKomSigName" SG_ 924 MsgKG2 "RFMsgPkt";
BA_ "FlexKomSigStartPos" SG_ 924 MsgKG2 7;
BA_ "FlexKomSigStartValue" SG_ 924 MsgKG2 "0000000000000000h";
BA_ "GenSigCycleTime" SG_ 924 MsgKG2 1000;
BA_ "GenSigSendType" SG_ 924 MsgKG2 5;
BA_ "GenSigSNA" SG_ 924 MsgKG2 "3h";
BA_ "GenSigTimeout_IC" SG_ 924 MsgKG2 10500;
BA_ "FlexKomComment" SG_ 924 MsgNotInPark "RF message packet";
BA_ "FlexKomIsMotorola" SG_ 924 MsgNotInPark 1;
BA_ "FlexKomSID" SG_ 924 MsgNotInPark 1038;
BA_ "FlexKomSigLaenge" SG_ 924 MsgNotInPark 64;
BA_ "FlexKomSigName" SG_ 924 MsgNotInPark "RFMsgPkt";
BA_ "FlexKomSigStartPos" SG_ 924 MsgNotInPark 7;
BA_ "FlexKomSigStartValue" SG_ 924 MsgNotInPark "0000000000000000h";
BA_ "GenSigCycleTime" SG_ 924 MsgNotInPark 1000;
BA_ "GenSigSendType" SG_ 924 MsgNotInPark 5;
BA_ "GenSigSNA" SG_ 924 MsgNotInPark "3h";
BA_ "GenSigTimeout_IC" SG_ 924 MsgNotInPark 10500;
BA_ "FlexKomComment" SG_ 924 MsgServPEKG "RF message packet";
BA_ "FlexKomIsMotorola" SG_ 924 MsgServPEKG 1;
BA_ "FlexKomSID" SG_ 924 MsgServPEKG 1038;
BA_ "FlexKomSigLaenge" SG_ 924 MsgServPEKG 64;
BA_ "FlexKomSigName" SG_ 924 MsgServPEKG "RFMsgPkt";
BA_ "FlexKomSigStartPos" SG_ 924 MsgServPEKG 7;
BA_ "FlexKomSigStartValue" SG_ 924 MsgServPEKG "0000000000000000h";
BA_ "GenSigCycleTime" SG_ 924 MsgServPEKG 1000;
BA_ "GenSigSendType" SG_ 924 MsgServPEKG 5;
BA_ "GenSigSNA" SG_ 924 MsgServPEKG "3h";
BA_ "GenSigTimeout_IC" SG_ 924 MsgServPEKG 10500;
BA_ "FlexKomComment" SG_ 656 UConnSeed1 "RF hub characters";
BA_ "FlexKomIsMotorola" SG_ 656 UConnSeed1 1;
BA_ "FlexKomSID" SG_ 656 UConnSeed1 1794;
BA_ "FlexKomSigLaenge" SG_ 656 UConnSeed1 32;
BA_ "FlexKomSigName" SG_ 656 UConnSeed1 "RF_CharPkt";
BA_ "FlexKomSigStartPos" SG_ 656 UConnSeed1 7;
BA_ "FlexKomSigStartValue" SG_ 656 UConnSeed1 "00000000h";
BA_ "GenSigSendType" SG_ 656 UConnSeed1 1;
BA_ "GenSigSNA" SG_ 656 UConnSeed1 "0h";
BA_ "FlexKomComment" SG_ 656 UConnSeed2 "RF hub characters";
BA_ "FlexKomIsMotorola" SG_ 656 UConnSeed2 1;
BA_ "FlexKomSID" SG_ 656 UConnSeed2 1794;
BA_ "FlexKomSigLaenge" SG_ 656 UConnSeed2 32;
BA_ "FlexKomSigName" SG_ 656 UConnSeed2 "RF_CharPkt";
BA_ "FlexKomSigStartPos" SG_ 656 UConnSeed2 7;
BA_ "FlexKomSigStartValue" SG_ 656 UConnSeed2 "00000000h";
BA_ "GenSigSendType" SG_ 656 UConnSeed2 1;
BA_ "GenSigSNA" SG_ 656 UConnSeed2 "0h";
BA_ "FlexKomComment" SG_ 656 UConnSeed3 "RF hub characters";
BA_ "FlexKomIsMotorola" SG_ 656 UConnSeed3 1;
BA_ "FlexKomSID" SG_ 656 UConnSeed3 1794;
BA_ "FlexKomSigLaenge" SG_ 656 UConnSeed3 32;
BA_ "FlexKomSigName" SG_ 656 UConnSeed3 "RF_CharPkt";
BA_ "FlexKomSigStartPos" SG_ 656 UConnSeed3 7;
BA_ "FlexKomSigStartValue" SG_ 656 UConnSeed3 "00000000h";
BA_ "GenSigSendType" SG_ 656 UConnSeed3 1;
BA_ "GenSigSNA" SG_ 656 UConnSeed3 "0h";
BA_ "FlexKomComment" SG_ 656 UConnSeed4 "RF hub characters";
BA_ "FlexKomIsMotorola" SG_ 656 UConnSeed4 1;
BA_ "FlexKomSID" SG_ 656 UConnSeed4 1794;
BA_ "FlexKomSigLaenge" SG_ 656 UConnSeed4 32;
BA_ "FlexKomSigName" SG_ 656 UConnSeed4 "RF_CharPkt";
BA_ "FlexKomSigStartPos" SG_ 656 UConnSeed4 7;
BA_ "FlexKomSigStartValue" SG_ 656 UConnSeed4 "00000000h";
BA_ "GenSigSendType" SG_ 656 UConnSeed4 1;
BA_ "GenSigSNA" SG_ 656 UConnSeed4 "0h";
BA_ "FlexKomComment" SG_ 929 DateTmFormat2 "Radio A3 packet";
BA_ "FlexKomIsMotorola" SG_ 929 DateTmFormat2 1;
BA_ "FlexKomSID" SG_ 929 DateTmFormat2 2562;
BA_ "FlexKomSigLaenge" SG_ 929 DateTmFormat2 64;
BA_ "FlexKomSigName" SG_ 929 DateTmFormat2 "Radio_A3_Pkt";
BA_ "FlexKomSigStartPos" SG_ 929 DateTmFormat2 7;
BA_ "FlexKomSigStartValue" SG_ 929 DateTmFormat2 "07FFFFFFFF000000h";
BA_ "GenSigCycleTime" SG_ 929 DateTmFormat2 1000;
BA_ "GenSigSendType" SG_ 929 DateTmFormat2 5;
BA_ "GenSigSNA" SG_ 929 DateTmFormat2 "7h";
BA_ "GenSigStartValue" SG_ 929 DateTmFormat2 7;
BA_ "GenSigTimeout_IC" SG_ 929 DateTmFormat2 10500;
BA_ "RID" SG_ 929 DateTmFormat2 "5015";
BA_ "FlexKomComment" SG_ 929 WeekdayTmHour_End "Radio A3 packet";
BA_ "FlexKomIsMotorola" SG_ 929 WeekdayTmHour_End 1;
BA_ "FlexKomSID" SG_ 929 WeekdayTmHour_End 2562;
BA_ "FlexKomSigLaenge" SG_ 929 WeekdayTmHour_End 64;
BA_ "FlexKomSigName" SG_ 929 WeekdayTmHour_End "Radio_A3_Pkt";
BA_ "FlexKomSigStartPos" SG_ 929 WeekdayTmHour_End 7;
BA_ "FlexKomSigStartValue" SG_ 929 WeekdayTmHour_End "07FFFFFFFF000000h";
BA_ "GenSigCycleTime" SG_ 929 WeekdayTmHour_End 1000;
BA_ "GenSigSendType" SG_ 929 WeekdayTmHour_End 5;
BA_ "GenSigSNA" SG_ 929 WeekdayTmHour_End "1Fh";
BA_ "GenSigStartValue" SG_ 929 WeekdayTmHour_End 31;
BA_ "GenSigTimeout_IC" SG_ 929 WeekdayTmHour_End 10500;
BA_ "RID" SG_ 929 WeekdayTmHour_End "5014";
BA_ "FlexKomComment" SG_ 929 WeekdayTmHour_Start "Radio A3 packet";
BA_ "FlexKomIsMotorola" SG_ 929 WeekdayTmHour_Start 1;
BA_ "FlexKomSID" SG_ 929 WeekdayTmHour_Start 2562;
BA_ "FlexKomSigLaenge" SG_ 929 WeekdayTmHour_Start 64;
BA_ "FlexKomSigName" SG_ 929 WeekdayTmHour_Start "Radio_A3_Pkt";
BA_ "FlexKomSigStartPos" SG_ 929 WeekdayTmHour_Start 7;
BA_ "FlexKomSigStartValue" SG_ 929 WeekdayTmHour_Start "07FFFFFFFF000000h";
BA_ "GenSigCycleTime" SG_ 929 WeekdayTmHour_Start 1000;
BA_ "GenSigSendType" SG_ 929 WeekdayTmHour_Start 5;
BA_ "GenSigSNA" SG_ 929 WeekdayTmHour_Start "1Fh";
BA_ "GenSigStartValue" SG_ 929 WeekdayTmHour_Start 31;
BA_ "GenSigTimeout_IC" SG_ 929 WeekdayTmHour_Start 10500;
BA_ "RID" SG_ 929 WeekdayTmHour_Start "5008";
BA_ "FlexKomComment" SG_ 929 WeekdayTmMinute_End "Radio A3 packet";
BA_ "FlexKomIsMotorola" SG_ 929 WeekdayTmMinute_End 1;
BA_ "FlexKomSID" SG_ 929 WeekdayTmMinute_End 2562;
BA_ "FlexKomSigLaenge" SG_ 929 WeekdayTmMinute_End 64;
BA_ "FlexKomSigName" SG_ 929 WeekdayTmMinute_End "Radio_A3_Pkt";
BA_ "FlexKomSigStartPos" SG_ 929 WeekdayTmMinute_End 7;
BA_ "FlexKomSigStartValue" SG_ 929 WeekdayTmMinute_End "07FFFFFFFF000000h";
BA_ "GenSigCycleTime" SG_ 929 WeekdayTmMinute_End 1000;
BA_ "GenSigSendType" SG_ 929 WeekdayTmMinute_End 5;
BA_ "GenSigSNA" SG_ 929 WeekdayTmMinute_End "7h";
BA_ "GenSigStartValue" SG_ 929 WeekdayTmMinute_End 7;
BA_ "GenSigTimeout_IC" SG_ 929 WeekdayTmMinute_End 10500;
BA_ "RID" SG_ 929 WeekdayTmMinute_End "5011";
BA_ "FlexKomComment" SG_ 929 WeekdayTmMinute_Start "Radio A3 packet";
BA_ "FlexKomIsMotorola" SG_ 929 WeekdayTmMinute_Start 1;
BA_ "FlexKomSID" SG_ 929 WeekdayTmMinute_Start 2562;
BA_ "FlexKomSigLaenge" SG_ 929 WeekdayTmMinute_Start 64;
BA_ "FlexKomSigName" SG_ 929 WeekdayTmMinute_Start "Radio_A3_Pkt";
BA_ "FlexKomSigStartPos" SG_ 929 WeekdayTmMinute_Start 7;
BA_ "FlexKomSigStartValue" SG_ 929 WeekdayTmMinute_Start "07FFFFFFFF000000h";
BA_ "GenSigCycleTime" SG_ 929 WeekdayTmMinute_Start 1000;
BA_ "GenSigSendType" SG_ 929 WeekdayTmMinute_Start 5;
BA_ "GenSigSNA" SG_ 929 WeekdayTmMinute_Start "7h";
BA_ "GenSigStartValue" SG_ 929 WeekdayTmMinute_Start 7;
BA_ "GenSigTimeout_IC" SG_ 929 WeekdayTmMinute_Start 10500;
BA_ "RID" SG_ 929 WeekdayTmMinute_Start "5009";
BA_ "FlexKomComment" SG_ 929 WeekendTmHour_End "Radio A3 packet";
BA_ "FlexKomIsMotorola" SG_ 929 WeekendTmHour_End 1;
BA_ "FlexKomSID" SG_ 929 WeekendTmHour_End 2562;
BA_ "FlexKomSigLaenge" SG_ 929 WeekendTmHour_End 64;
BA_ "FlexKomSigName" SG_ 929 WeekendTmHour_End "Radio_A3_Pkt";
BA_ "FlexKomSigStartPos" SG_ 929 WeekendTmHour_End 7;
BA_ "FlexKomSigStartValue" SG_ 929 WeekendTmHour_End "07FFFFFFFF000000h";
BA_ "GenSigCycleTime" SG_ 929 WeekendTmHour_End 1000;
BA_ "GenSigSendType" SG_ 929 WeekendTmHour_End 5;
BA_ "GenSigSNA" SG_ 929 WeekendTmHour_End "1Fh";
BA_ "GenSigStartValue" SG_ 929 WeekendTmHour_End 31;
BA_ "GenSigTimeout_IC" SG_ 929 WeekendTmHour_End 10500;
BA_ "RID" SG_ 929 WeekendTmHour_End "5016";
BA_ "FlexKomComment" SG_ 929 WeekendTmHour_Start "Radio A3 packet";
BA_ "FlexKomIsMotorola" SG_ 929 WeekendTmHour_Start 1;
BA_ "FlexKomSID" SG_ 929 WeekendTmHour_Start 2562;
BA_ "FlexKomSigLaenge" SG_ 929 WeekendTmHour_Start 64;
BA_ "FlexKomSigName" SG_ 929 WeekendTmHour_Start "Radio_A3_Pkt";
BA_ "FlexKomSigStartPos" SG_ 929 WeekendTmHour_Start 7;
BA_ "FlexKomSigStartValue" SG_ 929 WeekendTmHour_Start "07FFFFFFFF000000h";
BA_ "GenSigCycleTime" SG_ 929 WeekendTmHour_Start 1000;
BA_ "GenSigSendType" SG_ 929 WeekendTmHour_Start 5;
BA_ "GenSigSNA" SG_ 929 WeekendTmHour_Start "1Fh";
BA_ "GenSigStartValue" SG_ 929 WeekendTmHour_Start 31;
BA_ "GenSigTimeout_IC" SG_ 929 WeekendTmHour_Start 10500;
BA_ "RID" SG_ 929 WeekendTmHour_Start "5010";
BA_ "FlexKomComment" SG_ 929 WeekendTmMinute_End "Radio A3 packet";
BA_ "FlexKomIsMotorola" SG_ 929 WeekendTmMinute_End 1;
BA_ "FlexKomSID" SG_ 929 WeekendTmMinute_End 2562;
BA_ "FlexKomSigLaenge" SG_ 929 WeekendTmMinute_End 64;
BA_ "FlexKomSigName" SG_ 929 WeekendTmMinute_End "Radio_A3_Pkt";
BA_ "FlexKomSigStartPos" SG_ 929 WeekendTmMinute_End 7;
BA_ "FlexKomSigStartValue" SG_ 929 WeekendTmMinute_End "07FFFFFFFF000000h";
BA_ "GenSigCycleTime" SG_ 929 WeekendTmMinute_End 1000;
BA_ "GenSigSendType" SG_ 929 WeekendTmMinute_End 5;
BA_ "GenSigSNA" SG_ 929 WeekendTmMinute_End "7h";
BA_ "GenSigStartValue" SG_ 929 WeekendTmMinute_End 7;
BA_ "GenSigTimeout_IC" SG_ 929 WeekendTmMinute_End 10500;
BA_ "RID" SG_ 929 WeekendTmMinute_End "5012";
BA_ "FlexKomComment" SG_ 929 WeekendTmMinute_Start "Radio A3 packet";
BA_ "FlexKomIsMotorola" SG_ 929 WeekendTmMinute_Start 1;
BA_ "FlexKomSID" SG_ 929 WeekendTmMinute_Start 2562;
BA_ "FlexKomSigLaenge" SG_ 929 WeekendTmMinute_Start 64;
BA_ "FlexKomSigName" SG_ 929 WeekendTmMinute_Start "Radio_A3_Pkt";
BA_ "FlexKomSigStartPos" SG_ 929 WeekendTmMinute_Start 7;
BA_ "FlexKomSigStartValue" SG_ 929 WeekendTmMinute_Start "07FFFFFFFF000000h";
BA_ "GenSigCycleTime" SG_ 929 WeekendTmMinute_Start 1000;
BA_ "GenSigSendType" SG_ 929 WeekendTmMinute_Start 5;
BA_ "GenSigSNA" SG_ 929 WeekendTmMinute_Start "7h";
BA_ "GenSigStartValue" SG_ 929 WeekendTmMinute_Start 7;
BA_ "GenSigTimeout_IC" SG_ 929 WeekendTmMinute_Start 10500;
BA_ "RID" SG_ 929 WeekendTmMinute_Start "5013";
BA_ "FlexKomComment" SG_ 746 APCM_Stat "Shift by wire - rotary 1 packet";
BA_ "FlexKomIsMotorola" SG_ 746 APCM_Stat 1;
BA_ "FlexKomSID" SG_ 746 APCM_Stat 1661;
BA_ "FlexKomSigLaenge" SG_ 746 APCM_Stat 40;
BA_ "FlexKomSigName" SG_ 746 APCM_Stat "SBW_ROT1_PKT";
BA_ "FlexKomSigStartPos" SG_ 746 APCM_Stat 7;
BA_ "FlexKomSigStartValue" SG_ 746 APCM_Stat "00000000FFh";
BA_ "GenSigCycleTime" SG_ 746 APCM_Stat 20;
BA_ "GenSigSNA" SG_ 746 APCM_Stat "3h";
BA_ "RID" SG_ 746 APCM_Stat "9758";
BA_ "FlexKomComment" SG_ 746 CRC_SBW_ROT1 "Shift by wire - rotary 1 packet";
BA_ "FlexKomIsMotorola" SG_ 746 CRC_SBW_ROT1 1;
BA_ "FlexKomSID" SG_ 746 CRC_SBW_ROT1 1661;
BA_ "FlexKomSigLaenge" SG_ 746 CRC_SBW_ROT1 40;
BA_ "FlexKomSigName" SG_ 746 CRC_SBW_ROT1 "SBW_ROT1_PKT";
BA_ "FlexKomSigStartPos" SG_ 746 CRC_SBW_ROT1 7;
BA_ "FlexKomSigStartValue" SG_ 746 CRC_SBW_ROT1 "00000000FFh";
BA_ "GenSigCycleTime" SG_ 746 CRC_SBW_ROT1 20;
BA_ "GenSigSNA" SG_ 746 CRC_SBW_ROT1 "FFh";
BA_ "GenSigStartValue" SG_ 746 CRC_SBW_ROT1 255;
BA_ "FlexKomComment" SG_ 746 DrvRqShftROT "Shift by wire - rotary 1 packet";
BA_ "FlexKomIsMotorola" SG_ 746 DrvRqShftROT 1;
BA_ "FlexKomSID" SG_ 746 DrvRqShftROT 1661;
BA_ "FlexKomSigLaenge" SG_ 746 DrvRqShftROT 40;
BA_ "FlexKomSigName" SG_ 746 DrvRqShftROT "SBW_ROT1_PKT";
BA_ "FlexKomSigStartPos" SG_ 746 DrvRqShftROT 7;
BA_ "FlexKomSigStartValue" SG_ 746 DrvRqShftROT "00000000FFh";
BA_ "GenSigCycleTime" SG_ 746 DrvRqShftROT 20;
BA_ "GenSigSNA" SG_ 746 DrvRqShftROT "7h";
BA_ "GenSigTimeout_RF_HUB" SG_ 746 DrvRqShftROT 210;
BA_ "RID" SG_ 746 DrvRqShftROT "9760";
BA_ "FlexKomComment" SG_ 746 MC_SBW_ROT1 "Shift by wire - rotary 1 packet";
BA_ "FlexKomIsMotorola" SG_ 746 MC_SBW_ROT1 1;
BA_ "FlexKomSID" SG_ 746 MC_SBW_ROT1 1661;
BA_ "FlexKomSigLaenge" SG_ 746 MC_SBW_ROT1 40;
BA_ "FlexKomSigName" SG_ 746 MC_SBW_ROT1 "SBW_ROT1_PKT";
BA_ "FlexKomSigStartPos" SG_ 746 MC_SBW_ROT1 7;
BA_ "FlexKomSigStartValue" SG_ 746 MC_SBW_ROT1 "00000000FFh";
BA_ "GenSigCycleTime" SG_ 746 MC_SBW_ROT1 20;
BA_ "GenSigSNA" SG_ 746 MC_SBW_ROT1 "0h";
BA_ "RID" SG_ 746 MC_SBW_ROT1 "9761";
BA_ "FlexKomComment" SG_ 746 RackFlt "Shift by wire - rotary 1 packet";
BA_ "FlexKomIsMotorola" SG_ 746 RackFlt 1;
BA_ "FlexKomSID" SG_ 746 RackFlt 1661;
BA_ "FlexKomSigLaenge" SG_ 746 RackFlt 40;
BA_ "FlexKomSigName" SG_ 746 RackFlt "SBW_ROT1_PKT";
BA_ "FlexKomSigStartPos" SG_ 746 RackFlt 7;
BA_ "FlexKomSigStartValue" SG_ 746 RackFlt "00000000FFh";
BA_ "GenSigCycleTime" SG_ 746 RackFlt 20;
BA_ "GenSigSNA" SG_ 746 RackFlt "0h";
BA_ "RID" SG_ 746 RackFlt "9762";
BA_ "FlexKomComment" SG_ 746 ShftDispFltROT "Shift by wire - rotary 1 packet";
BA_ "FlexKomIsMotorola" SG_ 746 ShftDispFltROT 1;
BA_ "FlexKomSID" SG_ 746 ShftDispFltROT 1661;
BA_ "FlexKomSigLaenge" SG_ 746 ShftDispFltROT 40;
BA_ "FlexKomSigName" SG_ 746 ShftDispFltROT "SBW_ROT1_PKT";
BA_ "FlexKomSigStartPos" SG_ 746 ShftDispFltROT 7;
BA_ "FlexKomSigStartValue" SG_ 746 ShftDispFltROT "00000000FFh";
BA_ "GenSigCycleTime" SG_ 746 ShftDispFltROT 20;
BA_ "GenSigSNA" SG_ 746 ShftDispFltROT "0h";
BA_ "RID" SG_ 746 ShftDispFltROT "9763";
BA_ "FlexKomComment" SG_ 746 ShftLkFltROT "Shift by wire - rotary 1 packet";
BA_ "FlexKomIsMotorola" SG_ 746 ShftLkFltROT 1;
BA_ "FlexKomSID" SG_ 746 ShftLkFltROT 1661;
BA_ "FlexKomSigLaenge" SG_ 746 ShftLkFltROT 40;
BA_ "FlexKomSigName" SG_ 746 ShftLkFltROT "SBW_ROT1_PKT";
BA_ "FlexKomSigStartPos" SG_ 746 ShftLkFltROT 7;
BA_ "FlexKomSigStartValue" SG_ 746 ShftLkFltROT "00000000FFh";
BA_ "GenSigCycleTime" SG_ 746 ShftLkFltROT 20;
BA_ "GenSigSNA" SG_ 746 ShftLkFltROT "0h";
BA_ "RID" SG_ 746 ShftLkFltROT "9764";
BA_ "FlexKomComment" SG_ 746 ShftSensFltROT "Shift by wire - rotary 1 packet";
BA_ "FlexKomIsMotorola" SG_ 746 ShftSensFltROT 1;
BA_ "FlexKomSID" SG_ 746 ShftSensFltROT 1661;
BA_ "FlexKomSigLaenge" SG_ 746 ShftSensFltROT 40;
BA_ "FlexKomSigName" SG_ 746 ShftSensFltROT "SBW_ROT1_PKT";
BA_ "FlexKomSigStartPos" SG_ 746 ShftSensFltROT 7;
BA_ "FlexKomSigStartValue" SG_ 746 ShftSensFltROT "00000000FFh";
BA_ "GenSigCycleTime" SG_ 746 ShftSensFltROT 20;
BA_ "GenSigSNA" SG_ 746 ShftSensFltROT "0h";
BA_ "GenSigTimeout_IC" SG_ 746 ShftSensFltROT 210;
BA_ "RID" SG_ 746 ShftSensFltROT "9765";
BA_ "FlexKomComment" SG_ 571 ACC_DistSwDec "Cruise Control Lever Status";
BA_ "FlexKomIsMotorola" SG_ 571 ACC_DistSwDec 1;
BA_ "FlexKomSID" SG_ 571 ACC_DistSwDec 1848;
BA_ "FlexKomSigLaenge" SG_ 571 ACC_DistSwDec 24;
BA_ "FlexKomSigName" SG_ 571 ACC_DistSwDec "CrsCtrlLvrSts";
BA_ "FlexKomSigStartPos" SG_ 571 ACC_DistSwDec 7;
BA_ "FlexKomSigStartValue" SG_ 571 ACC_DistSwDec "0000FFh";
BA_ "GenSigSendType" SG_ 571 ACC_DistSwDec 1;
BA_ "GenSigSNA" SG_ 571 ACC_DistSwDec "0h";
BA_ "FlexKomComment" SG_ 571 ACC_DistSwInc "Cruise Control Lever Status";
BA_ "FlexKomIsMotorola" SG_ 571 ACC_DistSwInc 1;
BA_ "FlexKomSID" SG_ 571 ACC_DistSwInc 1848;
BA_ "FlexKomSigLaenge" SG_ 571 ACC_DistSwInc 24;
BA_ "FlexKomSigName" SG_ 571 ACC_DistSwInc "CrsCtrlLvrSts";
BA_ "FlexKomSigStartPos" SG_ 571 ACC_DistSwInc 7;
BA_ "FlexKomSigStartValue" SG_ 571 ACC_DistSwInc "0000FFh";
BA_ "GenSigSendType" SG_ 571 ACC_DistSwInc 1;
BA_ "GenSigSNA" SG_ 571 ACC_DistSwInc "0h";
BA_ "FlexKomComment" SG_ 571 ACC_On "Cruise Control Lever Status";
BA_ "FlexKomIsMotorola" SG_ 571 ACC_On 1;
BA_ "FlexKomSID" SG_ 571 ACC_On 1848;
BA_ "FlexKomSigLaenge" SG_ 571 ACC_On 24;
BA_ "FlexKomSigName" SG_ 571 ACC_On "CrsCtrlLvrSts";
BA_ "FlexKomSigStartPos" SG_ 571 ACC_On 7;
BA_ "FlexKomSigStartValue" SG_ 571 ACC_On "0000FFh";
BA_ "GenSigSendType" SG_ 571 ACC_On 1;
BA_ "GenSigSNA" SG_ 571 ACC_On "0h";
BA_ "FlexKomComment" SG_ 571 AcceleratorSts "Cruise Control Lever Status";
BA_ "FlexKomIsMotorola" SG_ 571 AcceleratorSts 1;
BA_ "FlexKomSID" SG_ 571 AcceleratorSts 1848;
BA_ "FlexKomSigLaenge" SG_ 571 AcceleratorSts 24;
BA_ "FlexKomSigName" SG_ 571 AcceleratorSts "CrsCtrlLvrSts";
BA_ "FlexKomSigStartPos" SG_ 571 AcceleratorSts 7;
BA_ "FlexKomSigStartValue" SG_ 571 AcceleratorSts "0000FFh";
BA_ "GenSigSendType" SG_ 571 AcceleratorSts 1;
BA_ "GenSigSNA" SG_ 571 AcceleratorSts "0h";
BA_ "FlexKomComment" SG_ 571 CRC_CSWC_1 "Cruise Control Lever Status";
BA_ "FlexKomIsMotorola" SG_ 571 CRC_CSWC_1 1;
BA_ "FlexKomSID" SG_ 571 CRC_CSWC_1 1848;
BA_ "FlexKomSigLaenge" SG_ 571 CRC_CSWC_1 24;
BA_ "FlexKomSigName" SG_ 571 CRC_CSWC_1 "CrsCtrlLvrSts";
BA_ "FlexKomSigStartPos" SG_ 571 CRC_CSWC_1 7;
BA_ "FlexKomSigStartValue" SG_ 571 CRC_CSWC_1 "0000FFh";
BA_ "GenSigSendType" SG_ 571 CRC_CSWC_1 1;
BA_ "GenSigSNA" SG_ 571 CRC_CSWC_1 "FFh";
BA_ "GenSigStartValue" SG_ 571 CRC_CSWC_1 255;
BA_ "FlexKomComment" SG_ 571 CruiseControlFailSts "Cruise Control Lever Status";
BA_ "FlexKomIsMotorola" SG_ 571 CruiseControlFailSts 1;
BA_ "FlexKomSID" SG_ 571 CruiseControlFailSts 1848;
BA_ "FlexKomSigLaenge" SG_ 571 CruiseControlFailSts 24;
BA_ "FlexKomSigName" SG_ 571 CruiseControlFailSts "CrsCtrlLvrSts";
BA_ "FlexKomSigStartPos" SG_ 571 CruiseControlFailSts 7;
BA_ "FlexKomSigStartValue" SG_ 571 CruiseControlFailSts "0000FFh";
BA_ "GenSigSendType" SG_ 571 CruiseControlFailSts 1;
BA_ "GenSigSNA" SG_ 571 CruiseControlFailSts "0h";
BA_ "FlexKomComment" SG_ 571 CruiseControlOnOffSts "Cruise Control Lever Status";
BA_ "FlexKomIsMotorola" SG_ 571 CruiseControlOnOffSts 1;
BA_ "FlexKomSID" SG_ 571 CruiseControlOnOffSts 1848;
BA_ "FlexKomSigLaenge" SG_ 571 CruiseControlOnOffSts 24;
BA_ "FlexKomSigName" SG_ 571 CruiseControlOnOffSts "CrsCtrlLvrSts";
BA_ "FlexKomSigStartPos" SG_ 571 CruiseControlOnOffSts 7;
BA_ "FlexKomSigStartValue" SG_ 571 CruiseControlOnOffSts "0000FFh";
BA_ "GenSigSendType" SG_ 571 CruiseControlOnOffSts 1;
BA_ "GenSigSNA" SG_ 571 CruiseControlOnOffSts "0h";
BA_ "FlexKomComment" SG_ 571 CrusCnclSwitch "Cruise Control Lever Status";
BA_ "FlexKomIsMotorola" SG_ 571 CrusCnclSwitch 1;
BA_ "FlexKomSID" SG_ 571 CrusCnclSwitch 1848;
BA_ "FlexKomSigLaenge" SG_ 571 CrusCnclSwitch 24;
BA_ "FlexKomSigName" SG_ 571 CrusCnclSwitch "CrsCtrlLvrSts";
BA_ "FlexKomSigStartPos" SG_ 571 CrusCnclSwitch 7;
BA_ "FlexKomSigStartValue" SG_ 571 CrusCnclSwitch "0000FFh";
BA_ "GenSigSendType" SG_ 571 CrusCnclSwitch 1;
BA_ "GenSigSNA" SG_ 571 CrusCnclSwitch "0h";
BA_ "FlexKomComment" SG_ 571 DeceleratorSts "Cruise Control Lever Status";
BA_ "FlexKomIsMotorola" SG_ 571 DeceleratorSts 1;
BA_ "FlexKomSID" SG_ 571 DeceleratorSts 1848;
BA_ "FlexKomSigLaenge" SG_ 571 DeceleratorSts 24;
BA_ "FlexKomSigName" SG_ 571 DeceleratorSts "CrsCtrlLvrSts";
BA_ "FlexKomSigStartPos" SG_ 571 DeceleratorSts 7;
BA_ "FlexKomSigStartValue" SG_ 571 DeceleratorSts "0000FFh";
BA_ "GenSigSendType" SG_ 571 DeceleratorSts 1;
BA_ "GenSigSNA" SG_ 571 DeceleratorSts "0h";
BA_ "FlexKomComment" SG_ 571 MC_CSWC_1 "Cruise Control Lever Status";
BA_ "FlexKomIsMotorola" SG_ 571 MC_CSWC_1 1;
BA_ "FlexKomSID" SG_ 571 MC_CSWC_1 1848;
BA_ "FlexKomSigLaenge" SG_ 571 MC_CSWC_1 24;
BA_ "FlexKomSigName" SG_ 571 MC_CSWC_1 "CrsCtrlLvrSts";
BA_ "FlexKomSigStartPos" SG_ 571 MC_CSWC_1 7;
BA_ "FlexKomSigStartValue" SG_ 571 MC_CSWC_1 "0000FFh";
BA_ "GenSigSendType" SG_ 571 MC_CSWC_1 1;
BA_ "GenSigSNA" SG_ 571 MC_CSWC_1 "0h";
BA_ "FlexKomComment" SG_ 571 ResumeSwitch "Cruise Control Lever Status";
BA_ "FlexKomIsMotorola" SG_ 571 ResumeSwitch 1;
BA_ "FlexKomSID" SG_ 571 ResumeSwitch 1848;
BA_ "FlexKomSigLaenge" SG_ 571 ResumeSwitch 24;
BA_ "FlexKomSigName" SG_ 571 ResumeSwitch "CrsCtrlLvrSts";
BA_ "FlexKomSigStartPos" SG_ 571 ResumeSwitch 7;
BA_ "FlexKomSigStartValue" SG_ 571 ResumeSwitch "0000FFh";
BA_ "GenSigSendType" SG_ 571 ResumeSwitch 1;
BA_ "GenSigSNA" SG_ 571 ResumeSwitch "0h";
VAL_ 1033 NM_Mode 252 "LHOM" 253 "RING" 254 "ALIVE" 255 "SNA" ;
VAL_ 1033 NM_Successor 255 "SNA" ;
VAL_ 1033 NM_Ud_Launch 4 "BROADCAST" 63 "SNA" ;
VAL_ 1033 NM_Ud_Srv 2 "WAKEUP_SA" 15 "AWAKE_BC" 255 "NO_USER_DATA" ;
VAL_ 1033 Nw_Id 0 "POWERTRAIN" 1 "BODY" 2 "AUDIO_TELE" 255 "SNA" ;
VAL_ 1033 WakeupCnt 255 "SNA" ;
VAL_ 1033 WakeupRsn_SBWM 0 "NETWORK" 1 "UNLK_R_S" 255 "SNA" ;
VAL_ 1059 NM_Mode 252 "LHOM" 253 "RING" 254 "ALIVE" 255 "SNA" ;
VAL_ 1059 NM_Successor 255 "SNA" ;
VAL_ 1059 NM_Ud_Launch 4 "BROADCAST" 63 "SNA" ;
VAL_ 1059 NM_Ud_Srv 2 "WAKEUP_SA" 15 "AWAKE_BC" 255 "NO_USER_DATA" ;
VAL_ 1059 Nw_Id 0 "POWERTRAIN" 1 "BODY" 2 "AUDIO_TELE" 255 "SNA" ;
VAL_ 1059 WakeupCnt 255 "SNA" ;
VAL_ 1059 WakeupRsn_SCCM 0 "NETWORK" 71 "TILT" 72 "FP_LVR" 73 "HRN_SW" 76 "STW_SW" 255 "SNA" ;
VAL_ 528 PsgSeatOCSts 0 "CLASS0" 1 "CLASS1" 3 "CLASS3" 4 "CLASS4" 15 "SNA" ;
VAL_ 528 PsgSeatSBRSts 0 "CLASS0" 1 "CLASS1" 15 "SNA" ;
VAL_ 464 DRV_SEATBELT 0 "DRV_SEATBELT_OK" 1 "DRV_SEATBELT_NOK" 2 "SEATBELT_FAIL" 3 "SNA" ;
VAL_ 464 DrvSbltUnFltr 0 "BUCKLED" 1 "UNBUCKLED" 2 "LOW" 3 "HIGH" 7 "SNA" ;
VAL_ 464 PSG_ODS_STAT 0 "ODS_STAT_NOCC" 1 "ODS_STAT_OCC" 2 "ODS_FAULT" 3 "SNA" ;
VAL_ 464 PSG_SEATBELT 0 "PSG_SEATBELT_OK" 1 "PSG_SEATBELT_NOK" 2 "SEATBELT_FAIL" 3 "SNA" ;
VAL_ 464 SRS_IndLmp_Rq 0 "OFF" 1 "CONT" 2 "BLINK" 3 "SNA" ;
VAL_ 294 AXSStat 0 "SISL" 1 "TSE" 2 "PSE" 3 "SEII" ;
VAL_ 294 AYSStat 0 "SISL" 1 "TSE" 2 "PSE" 3 "SEII" ;
VAL_ 294 LatAcceleration 4095 "SNA" ;
VAL_ 294 LongAcceleration 4095 "SNA" ;
VAL_ 294 YRSStat 0 "SISL" 1 "TSE" 2 "PSE" 3 "SEII" ;
VAL_ 294 YawRate 4095 "SNA" ;
VAL_ 542 PTRInfo 0 "SN" 1 "CPN" 3 "SUPPLIER" ;
VAL_ 764 MAP 255 "SNA" ;
VAL_ 764 RawPVS1 255 "SNA" ;
VAL_ 764 RawPVS2 255 "SNA" ;
VAL_ 764 RawTPS1 255 "SNA" ;
VAL_ 764 RawTPS2 255 "SNA" ;
VAL_ 764 RelativePdl 255 "SNA" ;
VAL_ 764 RelativeThrt 255 "SNA" ;
VAL_ 766 GF_Charge 65535 "SNA" ;
VAL_ 766 RelativeThrtPct 255 "SNA" ;
VAL_ 766 VVT_ExhCam1Pos 0 "SNA" ;
VAL_ 766 VVT_ExhCam2Pos 0 "SNA" ;
VAL_ 766 VVT_IntCam1Pos 0 "SNA" ;
VAL_ 766 VVT_IntCam2Pos 0 "SNA" ;
VAL_ 859 IBS2_Current_Status 0 "NO_ERROR" 1 "OPEN_CKT" 2 "HW_DEFECT" 3 "SATURATED" ;
VAL_ 859 IBS2_I_BATT 65535 "SNA" ;
VAL_ 859 IBS2_I_RANGE 0 "Range_I1" 1 "Range_I200" 2 "Range_I1500" 3 "SNA" ;
VAL_ 859 IBS2_PreWakeupVoltage 1023 "SNA" ;
VAL_ 859 IBS2_T_BATT 255 "SNA" ;
VAL_ 859 IBS2_Temp_Status 0 "NO_ERROR" 1 "OPEN_CKT" 2 "HW_DEFECT" 3 "SATURATED" ;
VAL_ 859 IBS2_V_BATT 16383 "SNA" ;
VAL_ 859 IBS2_Voltage_Status 0 "NO_ERROR" 1 "OPEN_CKT" 2 "HW_DEFECT" 3 "SATURATED" ;
VAL_ 532 IBS_Current_Status 0 "NO_ERROR" 1 "OPEN_CKT" 2 "HW_DEFECT" 3 "SATURATED" ;
VAL_ 532 IBS_I_BATT 65535 "SNA" ;
VAL_ 532 IBS_I_RANGE 0 "Range_I1" 1 "Range_I200" 2 "Range_I1500" 3 "SNA" ;
VAL_ 532 IBS_PreWakeupVoltage 1023 "SNA" ;
VAL_ 532 IBS_T_BATT 255 "SNA" ;
VAL_ 532 IBS_Temp_Status 0 "NO_ERROR" 1 "OPEN_CKT" 2 "HW_DEFECT" 3 "SATURATED" ;
VAL_ 532 IBS_V_BATT 16383 "SNA" ;
VAL_ 532 IBS_Voltage_Status 0 "NO_ERROR" 1 "OPEN_CKT" 2 "HW_DEFECT" 3 "SATURATED" ;
VAL_ 584 IBS_SOC 255 "SNA" ;
VAL_ 584 IBS_SOC_Accuracy 0 "ACCURACY_0" 1 "ACCURACY_1" 2 "ACCURACY_2" 3 "SNA" ;
VAL_ 584 IBS_SOF_Q 255 "SNA" ;
VAL_ 584 IBS_SOF_Q_Accuracy 0 "ACCURACY_0" 1 "ACCURACY_1" 2 "ACCURACY_2" 3 "SNA" ;
VAL_ 584 IBS_SOF_t 1023 "SNA" ;
VAL_ 584 IBS_SOF_t_Accuracy 0 "ACCURACY_0" 1 "ACCURACY_1" 2 "ACCURACY_2" 3 "SNA" ;
VAL_ 584 IBS_SOH_Q 255 "SNA" ;
VAL_ 584 IBS_SOH_Q_Accuracy 0 "ACCURACY_0" 1 "ACCURACY_1" 2 "ACCURACY_2" 3 "SNA" ;
VAL_ 900 IBS2_SOC 255 "SNA" ;
VAL_ 900 IBS2_SOC_Accuracy 0 "ACCURACY_0" 1 "ACCURACY_1" 2 "ACCURACY_2" 3 "SNA" ;
VAL_ 900 IBS2_SOF_Q 255 "SNA" ;
VAL_ 900 IBS2_SOF_Q_Accuracy 0 "ACCURACY_0" 1 "ACCURACY_1" 2 "ACCURACY_2" 3 "SNA" ;
VAL_ 900 IBS2_SOF_t 1023 "SNA" ;
VAL_ 900 IBS2_SOF_t_Accuracy 0 "ACCURACY_0" 1 "ACCURACY_1" 2 "ACCURACY_2" 3 "SNA" ;
VAL_ 900 IBS2_SOH_Q 255 "SNA" ;
VAL_ 900 IBS2_SOH_Q_Accuracy 0 "ACCURACY_0" 1 "ACCURACY_1" 2 "ACCURACY_2" 3 "SNA" ;
VAL_ 826 PTS_AlrFC 0 "PTS_ALR_NOD" 1 "ARC1" 2 "ARC2" 3 "ARC3" 4 "ARC4" 5 "ARC5" 6 "ARC6" 7 "ARC7" 8 "ARC8" 15 "SNA" ;
VAL_ 826 PTS_AlrFL 0 "PTS_ALR_NOD" 1 "ARC1" 2 "ARC2" 3 "ARC3" 4 "ARC4" 5 "ARC5" 6 "ARC6" 7 "ARC7" 8 "ARC8" 15 "SNA" ;
VAL_ 826 PTS_AlrFR 0 "PTS_ALR_NOD" 1 "ARC1" 2 "ARC2" 3 "ARC3" 4 "ARC4" 5 "ARC5" 6 "ARC6" 7 "ARC7" 8 "ARC8" 15 "SNA" ;
VAL_ 826 PTS_AlrRC 0 "PTS_ALR_NOD" 1 "ARC1" 2 "ARC2" 3 "ARC3" 4 "ARC4" 5 "ARC5" 6 "ARC6" 7 "ARC7" 8 "ARC8" 15 "SNA" ;
VAL_ 826 PTS_AlrRL 0 "PTS_ALR_NOD" 1 "ARC1" 2 "ARC2" 3 "ARC3" 4 "ARC4" 5 "ARC5" 6 "ARC6" 7 "ARC7" 8 "ARC8" 15 "SNA" ;
VAL_ 826 PTS_AlrRR 0 "PTS_ALR_NOD" 1 "ARC1" 2 "ARC2" 3 "ARC3" 4 "ARC4" 5 "ARC5" 6 "ARC6" 7 "ARC7" 8 "ARC8" 15 "SNA" ;
VAL_ 826 PTS_CFG_STAT 0 "OFF" 1 "SND" 2 "SND_DISP" 3 "SNA" ;
VAL_ 826 PTS_GraphicFC 0 "SLOW_FLS_RQ" 1 "FAST_FLS_RQ" 2 "CONT_FLS_RQ" 3 "None" ;
VAL_ 826 PTS_GraphicFL 0 "SLOW_FLS_RQ" 1 "FAST_FLS_RQ" 2 "CONT_FLS_RQ" 3 "None" ;
VAL_ 826 PTS_GraphicFR 0 "SLOW_FLS_RQ" 1 "FAST_FLS_RQ" 2 "CONT_FLS_RQ" 3 "None" ;
VAL_ 826 PTS_GraphicRC 0 "SLOW_FLS_RQ" 1 "FAST_FLS_RQ" 2 "CONT_FLS_RQ" 3 "None" ;
VAL_ 826 PTS_GraphicRL 0 "SLOW_FLS_RQ" 1 "FAST_FLS_RQ" 2 "CONT_FLS_RQ" 3 "None" ;
VAL_ 826 PTS_GraphicRR 0 "SLOW_FLS_RQ" 1 "FAST_FLS_RQ" 2 "CONT_FLS_RQ" 3 "None" ;
VAL_ 826 PTS_STAT 0 "OFF" 1 "CONT" 2 "BLINK" 3 "SNA" ;
VAL_ 608 PTS_CFG_STAT_TeenKey 0 "OFF" 1 "SND" 2 "SND_DISP" 3 "SNA" ;
VAL_ 608 PTS_FT_VOL_TeenKey 0 "LOW" 1 "MED" 2 "HIGH" 3 "SNA" ;
VAL_ 608 PTS_PopUpRqst 0 "TM0" 1 "TM1" 2 "TM2" 3 "TM3" 4 "TM4" 5 "TM5" 6 "TM6" 7 "TM7" 8 "TM8" 9 "TM9" 10 "TM10" 11 "TM11" 12 "TM12" 13 "TM13" 14 "TM14" 15 "TM15" 16 "TM16" 17 "TM17" 18 "TM18" 19 "TM19" 20 "TM20" 21 "TM21" 22 "TM22" 23 "TM23" 24 "TM24" 25 "TM25" 26 "TM26" 27 "TM27" 28 "TM28" 29 "TM29" 30 "TM30" 31 "TM31" 32 "TM32" 33 "TM33" 34 "TM34" 35 "TM35" 36 "TM36" 37 "TM37" 38 "TM38" 39 "TM39" 40 "TM40" 41 "TM41" 42 "TM42" 43 "TM43" 44 "TM44" 45 "TM45" 46 "TM46" 47 "TM47" 48 "TM48" 49 "TM49" 50 "TM50" 51 "TM51" 52 "TM52" 53 "TM53" 54 "TM54" 55 "TM55" 56 "TM56" 57 "TM57" 58 "TM58" 59 "TM59" 60 "TM60" 61 "TM61" 62 "TM62" 63 "TM63" 64 "TM64" 65 "TM65" 66 "TM66" 67 "TM67" 68 "TM68" 69 "TM69" 70 "TM70" 71 "TM71" 72 "TM72" 73 "TM73" 74 "TM74" 75 "TM75" 76 "TM76" 77 "TM77" 78 "TM78" 79 "TM79" 80 "TM80" 81 "TM81" 82 "TM82" 83 "TM83" 84 "TM84" 85 "TM85" 86 "TM86" 87 "TM87" 88 "TM88" 89 "TM89" 90 "TM90" 91 "TM91" 92 "TM92" 93 "TM93" 94 "TM94" 95 "TM95" 96 "TM96" 97 "TM97" 98 "TM98" 99 "TM99" 100 "TM100" 255 "SNA" ;
VAL_ 608 PTS_RR_VOL_TeenKey 0 "LOW" 1 "MED" 2 "HIGH" 3 "SNA" ;
VAL_ 608 RR_PTS_Dist 255 "SNA" ;
VAL_ 825 PTS_CHIME_TYPE 0 "NONE" 1 "TYP_1" 2 "TYP_2" 3 "TYP_3" 4 "TYP_4" 5 "TYP_5" 6 "TYP_6" 7 "TYP_7" 8 "TYP_8" 9 "TYP_9" 10 "TYP_10" 11 "TYP_11" 12 "TYP_12" 13 "TYP_13" 14 "TYP_14" 15 "SNA" ;
VAL_ 825 PTS_FT_VOL 0 "LOW" 1 "MED" 2 "HIGH" 3 "SNA" ;
VAL_ 825 PTS_RR_VOL 0 "LOW" 1 "MED" 2 "HIGH" 3 "SNA" ;
VAL_ 671 PTS_ManoeuvreMode 0 "None" 1 "PARA" 2 "PERP" 3 "PULL_OUT" 4 "OVER" 7 "SNA" ;
VAL_ 388 CustKeyInIgn 0 "CUST_KEY_DEFAULT" 1 "CUST_KEY_NOT_IN_IGNITION" 2 "CUST_KEY_IN_IGNITION" 3 "SNA" ;
VAL_ 388 IgnPos 0 "IGN_LK" 3 "IGN_OFF_ACC" 4 "IGN_RUN" 5 "IGN_START" 7 "SNA" ;
VAL_ 388 ValImmKey 0 "CUST_IMMOB_KEY_DEFAULT" 1 "CUST_IMMOB_KEY_VALID" 3 "SNA" ;
VAL_ 448 KeyProgramSts 0 "RKE_NORM_STAT" 1 "EN_KEY_PROG" 2 "PROG_ACT" 3 "EX_KEY_PROG" 4 "KEY_PROG" 5 "DMG_KEY" 6 "INV_KEY" 7 "EXCD_KEY" 8 "RKE_BATT_LO" 9 "SRV_SKREEM" 10 "BTN_DLY_ACT" 11 "BTN_DLY_INACT" 12 "KEY_NOT_PROG" 15 "SNA" ;
VAL_ 448 RFCfgReq 0 "DEFAULT" 1 "HORN_CHIRP_TOGGLE" 2 "OPTICAL_CHIRP_TOGGLE" 3 "DRIVER_UNLOCK_FIRST_TOGGLE" 7 "SNA" ;
VAL_ 448 RFFobNum 0 "FOB_DEFAULT" 1 "FOB_1" 2 "FOB_2" 3 "FOB_3" 4 "FOB_4" 5 "FOB_5" 6 "FOB_6" 7 "FOB_7" 8 "FOB_8" 15 "SNA" ;
VAL_ 448 RFFuncReq 0 "NO_BASIC_REQUEST" 1 "LOCK_REQUEST" 2 "RELOCK_REQUEST" 3 "DRIVER_UNLOCK_REQUEST" 4 "ALL_UNLOCK_REQUEST" 5 "TRUNK_PLG_TOGGLE_REQUEST" 6 "LEFT_SLIDER_TOGGLE_REQUEST" 7 "RIGHT_SLIDER_TOGGLE_REQUEST" 8 "FLIPPER_GLASS_REQUEST" 9 "REMOTE_START_ON" 10 "REMOTE_START_OFF" 11 "GLOBAL_WINDOW_DOWN_REQUEST" 12 "OPEN_CONVERTIBLE_TOP" 13 "CLOSE_CONVERTIBLE_TOP" 14 "PANIC_TOGGLE_REQUEST" 15 "DRIVER_TOGGLE_REQUEST" 16 "PASSENGER_TOGGLE_REQUEST" 17 "ExtLightReq" 18 "AirSuspReq" 19 "AirSuspCancel" 20 "GLBL_WIN_UP_RQ" 21 "CAR_FINDER_REQUEST" 22 "TRUNK_PLG_BTN_PRESSED" 23 "TRUNK_PLG_STOP_REQUEST" 24 "TRUNK_PLG_OPEN_REQUEST" 25 "TRUNK_PLG_CLOSE_REQUEST" 26 "VTA_RQ" 27 "RAP_UNLOCK_REQUEST" 31 "SNA" ;
VAL_ 448 RFReq 0 "REQUESTOR_DEFAULT" 1 "REQUESTOR_RKE" 2 "REQUESTOR_PE" 3 "REQUESTOR_REMOTESTART" 4 "REQUESTOR_UCONNECT" 5 "REQUESTOR_PE_HANDSFREE" 7 "SNA" ;
VAL_ 924 FOB_SrchRslt 0 "NO_ACT" 1 "SIP" 2 "COMPLETE" 3 "TIMEOUT" ;
VAL_ 924 MsgFobBattLow 0 "MSG_DEFAULT" 1 "MSG_ACTIVE" 3 "SNA" ;
VAL_ 924 MsgFobNotFnd 0 "MSG_DEFAULT" 1 "MSG_ACTIVE" 3 "SNA" ;
VAL_ 924 MsgKG1 0 "MSG_DEFAULT" 1 "MSG_ACTIVE" 3 "SNA" ;
VAL_ 924 MsgKG2 0 "MSG_DEFAULT" 1 "MSG_ACTIVE" 3 "SNA" ;
VAL_ 924 MsgNotInPark 0 "MSG_DEFAULT" 1 "MSG_ACTIVE" 3 "SNA" ;
VAL_ 924 MsgServPEKG 0 "MSG_DEFAULT" 1 "MSG_ACTIVE" 3 "SNA" ;
VAL_ 929 DateTmFormat2 0 "NDEF0" 1 "FORMAT_12H" 2 "FORMAT_24H" 3 "FORMAT_0" 4 "FORMAT_1" 5 "FORMAT_2" 6 "FORMAT_3" 7 "SNA" ;
VAL_ 929 WeekdayTmHour_End 25 "Charge_Full" 31 "SNA" ;
VAL_ 929 WeekdayTmHour_Start 31 "SNA" ;
VAL_ 929 WeekdayTmMinute_End 0 "ZERO" 1 "FIFTEEN" 2 "THIRTY" 3 "FOURTY_FIVE" 7 "SNA" ;
VAL_ 929 WeekdayTmMinute_Start 0 "ZERO" 1 "FIFTEEN" 2 "THIRTY" 3 "FOURTY_FIVE" 7 "SNA" ;
VAL_ 929 WeekendTmHour_End 25 "Charge_Full" 31 "SNA" ;
VAL_ 929 WeekendTmHour_Start 31 "SNA" ;
VAL_ 929 WeekendTmMinute_End 0 "ZERO" 1 "FIFTEEN" 2 "THIRTY" 3 "FOURTY_FIVE" 7 "SNA" ;
VAL_ 929 WeekendTmMinute_Start 0 "ZERO" 1 "FIFTEEN" 2 "THIRTY" 3 "FOURTY_FIVE" 7 "SNA" ;
VAL_ 746 APCM_Stat 0 "OFF" 1 "ON" 2 "PENDING" 3 "SNA" ;
VAL_ 746 DrvRqShftROT 0 "INIT" 1 "PARK" 2 "REV" 3 "NEUT" 4 "DRIVE" 5 "FIFTH" 7 "SNA" ;
